VERSION ""

NS_ :

BS_:

BU_: WPC2 PSB SHVU_RR FCS vHS_B2 EMCU SLB GW_APSU GW_DLBCU RCM ARS CGW_CCU vDummy_HS_B GW_RLPSU ATS RLHV SGU PFSU GW_RRPSU ALBCU DSAU SWRC SHVU_FR RCS GW_DPSU BLTN_CAM SCM OHCL RWPC RRHV WPC HOD ASAU

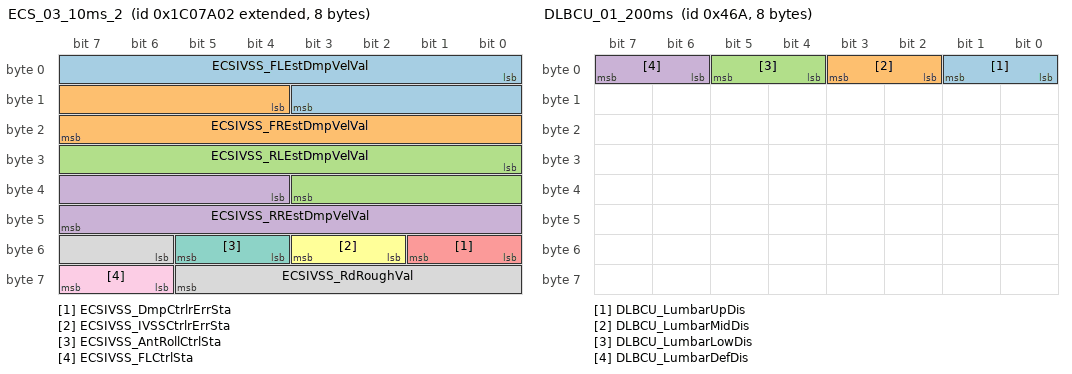
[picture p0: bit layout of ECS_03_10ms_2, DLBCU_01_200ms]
BO_ 2176875010 ECS_03_10ms_2: 8 CGW_CCU
 SG_ ECSIVSS_FLEstDmpVelVal : 0|12@1- (1,0) [0|0] "mm/s" Vector__XXX
 SG_ ECSIVSS_FREstDmpVelVal : 12|12@1- (1,0) [0|0] "mm/s" Vector__XXX
 SG_ ECSIVSS_RLEstDmpVelVal : 24|12@1- (1,0) [0|0] "mm/s" Vector__XXX
 SG_ ECSIVSS_RREstDmpVelVal : 36|12@1- (1,0) [0|0] "mm/s" Vector__XXX
 SG_ ECSIVSS_DmpCtrlrErrSta : 48|2@1+ (1,0) [0|0] "" Vector__XXX
 SG_ ECSIVSS_IVSSCtrlrErrSta : 50|2@1+ (1,0) [0|0] "" Vector__XXX
 SG_ ECSIVSS_AntRollCtrlSta : 52|2@1+ (1,0) [0|0] "" Vector__XXX
 SG_ ECSIVSS_RdRoughVal : 54|8@1+ (1,0) [0|0] ""  EMCU
 SG_ ECSIVSS_FLCtrlSta : 62|2@1+ (1,0) [0|0] "" Vector__XXX

BO_ 1130 DLBCU_01_200ms: 8 GW_DLBCU
 SG_ DLBCU_LumbarUpDis : 0|2@1+ (1,0) [0|0] ""  CGW_CCU,GW_DPSU
 SG_ DLBCU_LumbarMidDis : 2|2@1+ (1,0) [0|0] ""  CGW_CCU,GW_DPSU
 SG_ DLBCU_LumbarLowDis : 4|2@1+ (1,0) [0|0] ""  CGW_CCU,GW_DPSU
 SG_ DLBCU_LumbarDefDis : 6|2@1+ (1,0) [0|0] ""  CGW_CCU,GW_DPSU

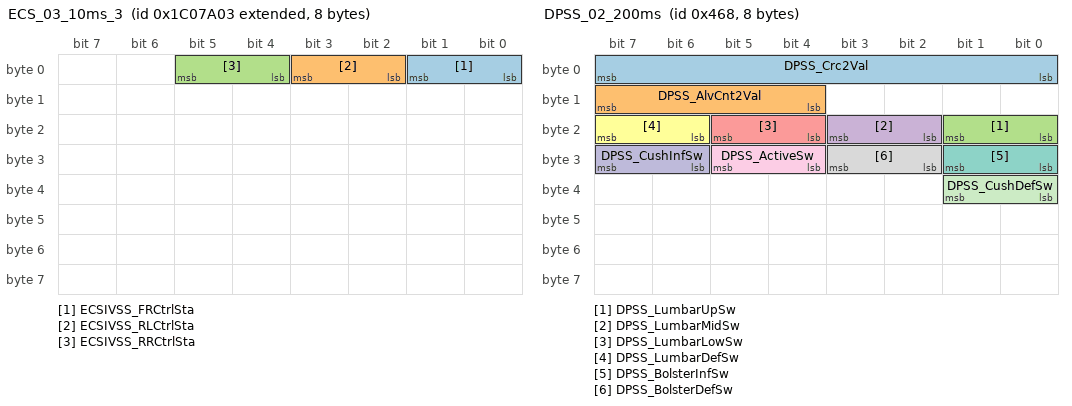
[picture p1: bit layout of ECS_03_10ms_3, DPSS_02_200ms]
BO_ 2176875011 ECS_03_10ms_3: 8 CGW_CCU
 SG_ ECSIVSS_FRCtrlSta : 0|2@1+ (1,0) [0|0] "" Vector__XXX
 SG_ ECSIVSS_RLCtrlSta : 2|2@1+ (1,0) [0|0] "" Vector__XXX
 SG_ ECSIVSS_RRCtrlSta : 4|2@1+ (1,0) [0|0] "" Vector__XXX

BO_ 1131 DLBCU_02_200ms: 8 GW_DLBCU
 SG_ DLBCU_BolsterInfDis : 0|2@1+ (1,0) [0|0] ""  CGW_CCU,GW_DPSU
 SG_ DLBCU_BolsterDefDis : 2|2@1+ (1,0) [0|0] ""  CGW_CCU,GW_DPSU

BO_ 1128 DPSS_02_200ms: 8 GW_DPSU
 SG_ DPSS_Crc2Val : 0|8@1+ (1,0) [0|0] ""  GW_DLBCU
 SG_ DPSS_AlvCnt2Val : 12|4@1+ (1,0) [0|0] ""  GW_DLBCU
 SG_ DPSS_LumbarUpSw : 16|2@1+ (1,0) [0|0] ""  CGW_CCU,GW_DLBCU
 SG_ DPSS_LumbarMidSw : 18|2@1+ (1,0) [0|0] ""  CGW_CCU,GW_DLBCU
 SG_ DPSS_LumbarLowSw : 20|2@1+ (1,0) [0|0] ""  CGW_CCU,GW_DLBCU
 SG_ DPSS_LumbarDefSw : 22|2@1+ (1,0) [0|0] ""  CGW_CCU,GW_DLBCU
 SG_ DPSS_BolsterInfSw : 24|2@1+ (1,0) [0|0] ""  GW_DLBCU
 SG_ DPSS_BolsterDefSw : 26|2@1+ (1,0) [0|0] ""  GW_DLBCU
 SG_ DPSS_ActiveSw : 28|2@1+ (1,0) [0|0] ""  GW_DLBCU
 SG_ DPSS_CushInfSw : 30|2@1+ (1,0) [0|0] ""  GW_DLBCU
 SG_ DPSS_CushDefSw : 32|2@1+ (1,0) [0|0] ""  GW_DLBCU

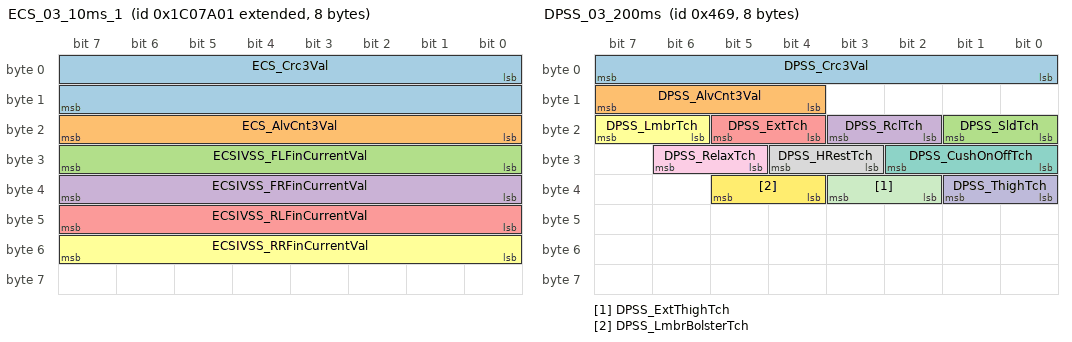
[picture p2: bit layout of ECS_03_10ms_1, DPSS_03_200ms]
BO_ 2176875009 ECS_03_10ms_1: 8 CGW_CCU
 SG_ ECS_Crc3Val : 0|16@1+ (1,0) [0|0] "" Vector__XXX
 SG_ ECS_AlvCnt3Val : 16|8@1+ (1,0) [0|0] "" Vector__XXX
 SG_ ECSIVSS_FLFinCurrentVal : 24|8@1+ (0.5,0) [0|0] "%" Vector__XXX
 SG_ ECSIVSS_FRFinCurrentVal : 32|8@1+ (0.5,0) [0|0] "%" Vector__XXX
 SG_ ECSIVSS_RLFinCurrentVal : 40|8@1+ (0.5,0) [0|0] "%" Vector__XXX
 SG_ ECSIVSS_RRFinCurrentVal : 48|8@1+ (0.5,0) [0|0] "%" Vector__XXX

BO_ 1129 DPSS_03_200ms: 8 GW_DPSU
 SG_ DPSS_Crc3Val : 0|8@1+ (1,0) [0|0] ""  CGW_CCU
 SG_ DPSS_AlvCnt3Val : 12|4@1+ (1,0) [0|0] "" Vector__XXX
 SG_ DPSS_SldTch : 16|2@1+ (1,0) [0|0] ""  CGW_CCU
 SG_ DPSS_RclTch : 18|2@1+ (1,0) [0|0] ""  CGW_CCU
 SG_ DPSS_ExtTch : 20|2@1+ (1,0) [0|0] ""  CGW_CCU
 SG_ DPSS_LmbrTch : 22|2@1+ (1,0) [0|0] ""  CGW_CCU
 SG_ DPSS_CushOnOffTch : 24|3@1+ (1,0) [0|0] ""  CGW_CCU
 SG_ DPSS_HRestTch : 27|2@1+ (1,0) [0|0] ""  CGW_CCU
 SG_ DPSS_RelaxTch : 29|2@1+ (1,0) [0|0] ""  CGW_CCU
 SG_ DPSS_ThighTch : 32|2@1+ (1,0) [0|0] ""  CGW_CCU
 SG_ DPSS_ExtThighTch : 34|2@1+ (1,0) [0|0] ""  CGW_CCU
 SG_ DPSS_LmbrBolsterTch : 36|2@1+ (1,0) [0|0] ""  CGW_CCU

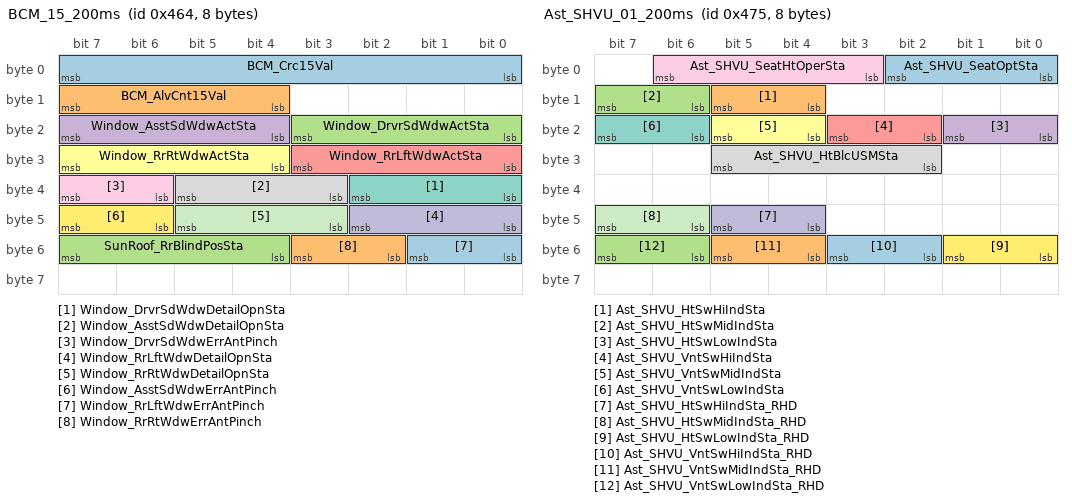
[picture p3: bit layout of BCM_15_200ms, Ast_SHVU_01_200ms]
BO_ 1124 BCM_15_200ms: 8 CGW_CCU
 SG_ BCM_Crc15Val : 0|8@1+ (1,0) [0|0] "" Vector__XXX
 SG_ BCM_AlvCnt15Val : 12|4@1+ (1,0) [0|0] "" Vector__XXX
 SG_ Window_DrvrSdWdwActSta : 16|4@1+ (1,0) [0|0] "" Vector__XXX
 SG_ Window_AsstSdWdwActSta : 20|4@1+ (1,0) [0|0] "" Vector__XXX
 SG_ Window_RrLftWdwActSta : 24|4@1+ (1,0) [0|0] "" Vector__XXX
 SG_ Window_RrRtWdwActSta : 28|4@1+ (1,0) [0|0] "" Vector__XXX
 SG_ Window_DrvrSdWdwDetailOpnSta : 32|3@1+ (1,0) [0|0] "" Vector__XXX
 SG_ Window_AsstSdWdwDetailOpnSta : 35|3@1+ (1,0) [0|0] "" Vector__XXX
 SG_ Window_DrvrSdWdwErrAntPinch : 38|2@1+ (1,0) [0|0] "" Vector__XXX
 SG_ Window_RrLftWdwDetailOpnSta : 40|3@1+ (1,0) [0|0] "" Vector__XXX
 SG_ Window_RrRtWdwDetailOpnSta : 43|3@1+ (1,0) [0|0] "" Vector__XXX
 SG_ Window_AsstSdWdwErrAntPinch : 46|2@1+ (1,0) [0|0] "" Vector__XXX
 SG_ Window_RrLftWdwErrAntPinch : 48|2@1+ (1,0) [0|0] "" Vector__XXX
 SG_ Window_RrRtWdwErrAntPinch : 50|2@1+ (1,0) [0|0] "" Vector__XXX
 SG_ SunRoof_RrBlindPosSta : 52|4@1+ (1,0) [0|0] ""  ATS

BO_ 1141 Ast_SHVU_01_200ms: 8 SHVU_FR
 SG_ Ast_SHVU_SeatOptSta : 0|3@1+ (1,0) [0|0] ""  CGW_CCU,FCS
 SG_ Ast_SHVU_HtSwHiIndSta : 12|2@1+ (1,0) [0|0] ""  CGW_CCU,FCS
 SG_ Ast_SHVU_HtSwMidIndSta : 14|2@1+ (1,0) [0|0] ""  CGW_CCU,FCS
 SG_ Ast_SHVU_HtSwLowIndSta : 16|2@1+ (1,0) [0|0] ""  CGW_CCU,FCS
 SG_ Ast_SHVU_VntSwHiIndSta : 18|2@1+ (1,0) [0|0] ""  CGW_CCU,FCS
 SG_ Ast_SHVU_VntSwMidIndSta : 20|2@1+ (1,0) [0|0] ""  CGW_CCU,FCS
 SG_ Ast_SHVU_VntSwLowIndSta : 22|2@1+ (1,0) [0|0] ""  CGW_CCU,FCS
 SG_ Ast_SHVU_HtBlcUSMSta : 26|4@1+ (1,0) [0|0] ""  CGW_CCU
 SG_ Ast_SHVU_SeatHtOperSta : 3|4@1+ (1,0) [0|0] ""  CGW_CCU,FCS
 SG_ Ast_SHVU_HtSwHiIndSta_RHD : 44|2@1+ (1,0) [0|0] ""  CGW_CCU,FCS
 SG_ Ast_SHVU_HtSwMidIndSta_RHD : 46|2@1+ (1,0) [0|0] ""  CGW_CCU,FCS
 SG_ Ast_SHVU_HtSwLowIndSta_RHD : 48|2@1+ (1,0) [0|0] ""  CGW_CCU,FCS
 SG_ Ast_SHVU_VntSwHiIndSta_RHD : 50|2@1+ (1,0) [0|0] ""  CGW_CCU,FCS
 SG_ Ast_SHVU_VntSwMidIndSta_RHD : 52|2@1+ (1,0) [0|0] ""  CGW_CCU,FCS
 SG_ Ast_SHVU_VntSwLowIndSta_RHD : 54|2@1+ (1,0) [0|0] ""  CGW_CCU,FCS

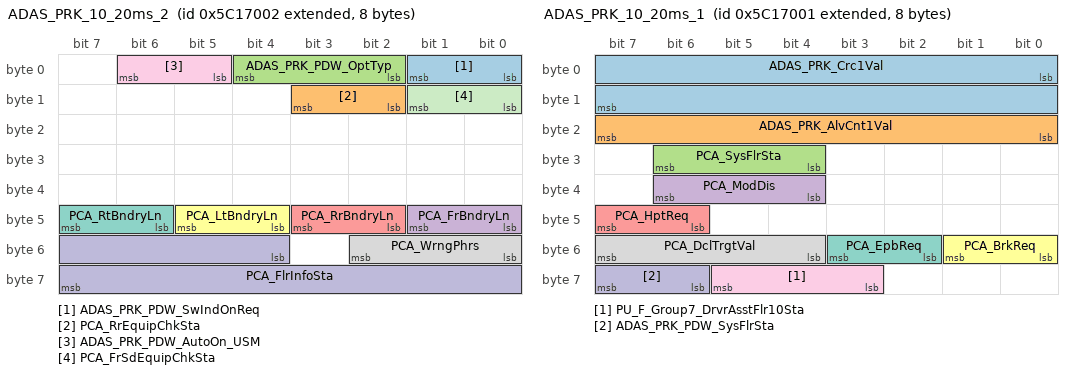
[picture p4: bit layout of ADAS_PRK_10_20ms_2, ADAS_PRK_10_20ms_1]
BO_ 2244046850 ADAS_PRK_10_20ms_2: 8 CGW_CCU
 SG_ ADAS_PRK_PDW_SwIndOnReq : 0|2@1+ (1,0) [0|0] ""  FCS
 SG_ PCA_RrEquipChkSta : 10|2@1+ (1,0) [0|0] "" Vector__XXX
 SG_ ADAS_PRK_PDW_OptTyp : 2|3@1+ (1,0) [0|0] "" Vector__XXX
 SG_ PCA_FrBndryLn : 40|2@1+ (1,0) [0|0] "" Vector__XXX
 SG_ PCA_RrBndryLn : 42|2@1+ (1,0) [0|0] "" Vector__XXX
 SG_ PCA_LtBndryLn : 44|2@1+ (1,0) [0|0] "" Vector__XXX
 SG_ PCA_RtBndryLn : 46|2@1+ (1,0) [0|0] "" Vector__XXX
 SG_ PCA_WrngPhrs : 48|3@1+ (1,0) [0|0] "" Vector__XXX
 SG_ ADAS_PRK_PDW_AutoOn_USM : 5|2@1+ (1,0) [0|0] "" Vector__XXX
 SG_ PCA_FlrInfoSta : 52|12@1+ (1,0) [0|0] "" Vector__XXX
 SG_ PCA_FrSdEquipChkSta : 8|2@1+ (1,0) [0|0] "" Vector__XXX

BO_ 2244046849 ADAS_PRK_10_20ms_1: 8 CGW_CCU
 SG_ ADAS_PRK_Crc1Val : 0|16@1+ (1,0) [0|0] "" Vector__XXX
 SG_ ADAS_PRK_AlvCnt1Val : 16|8@1+ (1,0) [0|0] "" Vector__XXX
 SG_ PCA_SysFlrSta : 28|3@1+ (1,0) [0|0] "" Vector__XXX
 SG_ PCA_ModDis : 36|3@1+ (1,0) [0|0] "" Vector__XXX
 SG_ PCA_HptReq : 46|2@1+ (1,0) [0|0] "" Vector__XXX
 SG_ PCA_BrkReq : 48|2@1+ (1,0) [0|0] "" Vector__XXX
 SG_ PCA_EpbReq : 50|2@1+ (1,0) [0|0] "" Vector__XXX
 SG_ PCA_DclTrgtVal : 52|4@1+ (0.04,0) [0|0] "g" Vector__XXX
 SG_ PU_F_Group7_DrvrAsstFlr10Sta : 59|3@1+ (1,0) [0|0] "" Vector__XXX
 SG_ ADAS_PRK_PDW_SysFlrSta : 62|2@1+ (1,0) [0|0] "" Vector__XXX

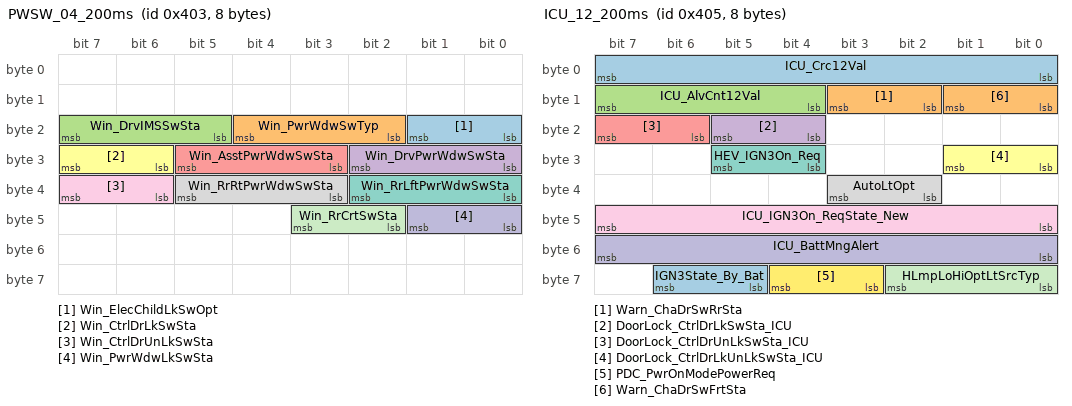
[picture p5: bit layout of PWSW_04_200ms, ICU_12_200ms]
BO_ 1027 PWSW_04_200ms: 8 CGW_CCU
 SG_ Win_ElecChildLkSwOpt : 16|2@1+ (1,0) [0|0] "" Vector__XXX
 SG_ Win_PwrWdwSwTyp : 18|3@1+ (1,0) [0|0] "" Vector__XXX
 SG_ Win_DrvIMSSwSta : 21|3@1+ (1,0) [0|0] ""  GW_DPSU
 SG_ Win_DrvPwrWdwSwSta : 24|3@1+ (1,0) [0|0] "" Vector__XXX
 SG_ Win_AsstPwrWdwSwSta : 27|3@1+ (1,0) [0|0] "" Vector__XXX
 SG_ Win_CtrlDrLkSwSta : 30|2@1+ (1,0) [0|0] "" Vector__XXX
 SG_ Win_RrLftPwrWdwSwSta : 32|3@1+ (1,0) [0|0] "" Vector__XXX
 SG_ Win_RrRtPwrWdwSwSta : 35|3@1+ (1,0) [0|0] "" Vector__XXX
 SG_ Win_CtrlDrUnLkSwSta : 38|2@1+ (1,0) [0|0] "" Vector__XXX
 SG_ Win_PwrWdwLkSwSta : 40|2@1+ (1,0) [0|0] "" Vector__XXX
 SG_ Win_RrCrtSwSta : 42|2@1+ (1,0) [0|0] "" Vector__XXX

BO_ 1029 ICU_12_200ms: 8 CGW_CCU
 SG_ ICU_Crc12Val : 0|8@1+ (1,0) [0|0] "" Vector__XXX
 SG_ Warn_ChaDrSwRrSta : 10|2@1+ (1,0) [0|0] "" Vector__XXX
 SG_ ICU_AlvCnt12Val : 12|4@1+ (1,0) [0|0] "" Vector__XXX
 SG_ DoorLock_CtrlDrLkSwSta_ICU : 20|2@1+ (1,0) [0|0] "" Vector__XXX
 SG_ DoorLock_CtrlDrUnLkSwSta_ICU : 22|2@1+ (1,0) [0|0] "" Vector__XXX
 SG_ DoorLock_CtrlDrLkUnLkSwSta_ICU : 24|2@1+ (1,0) [0|0] "" Vector__XXX
 SG_ HEV_IGN3On_Req : 28|2@1+ (1,0) [0|0] "" Vector__XXX
 SG_ AutoLtOpt : 34|2@1+ (1,0) [0|0] "" Vector__XXX
 SG_ ICU_IGN3On_ReqState_New : 40|8@1+ (1,0) [0|0] ""  GW_APSU,GW_DLBCU,GW_DPSU,GW_RLPSU,GW_RRPSU,PFSU,RLHV,RRHV,SHVU_FR,SHVU_RR
 SG_ ICU_BattMngAlert : 48|8@1+ (1,0) [0|0] "" Vector__XXX
 SG_ HLmpLoHiOptLtSrcTyp : 56|3@1+ (1,0) [0|0] "" Vector__XXX
 SG_ PDC_PwrOnModePowerReq : 59|2@1+ (1,0) [0|0] "" Vector__XXX
 SG_ IGN3State_By_Bat : 61|2@1+ (1,0) [0|0] "" Vector__XXX
 SG_ Warn_ChaDrSwFrtSta : 8|2@1+ (1,0) [0|0] "" Vector__XXX

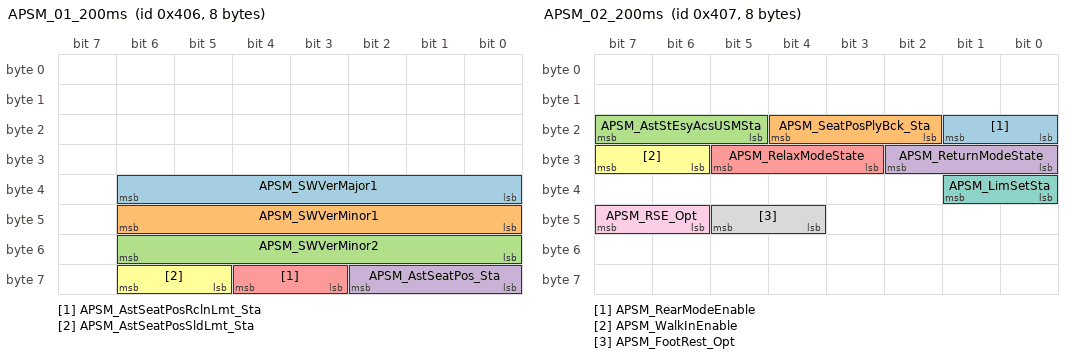
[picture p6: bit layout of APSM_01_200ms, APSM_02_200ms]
BO_ 1030 APSM_01_200ms: 8 GW_APSU
 SG_ APSM_SWVerMajor1 : 32|7@1+ (1,0) [0|0] ""  CGW_CCU
 SG_ APSM_SWVerMinor1 : 40|7@1+ (1,0) [0|0] ""  CGW_CCU
 SG_ APSM_SWVerMinor2 : 48|7@1+ (1,0) [0|0] ""  CGW_CCU
 SG_ APSM_AstSeatPos_Sta : 56|3@1+ (1,0) [0|0] ""  GW_RLPSU
 SG_ APSM_AstSeatPosRclnLmt_Sta : 59|2@1+ (1,0) [0|0] ""  CGW_CCU
 SG_ APSM_AstSeatPosSldLmt_Sta : 61|2@1+ (1,0) [0|0] ""  CGW_CCU

BO_ 1031 APSM_02_200ms: 8 GW_APSU
 SG_ APSM_RearModeEnable : 16|2@1+ (1,0) [0|0] ""  GW_RLPSU,GW_RRPSU
 SG_ APSM_SeatPosPlyBck_Sta : 18|3@1+ (1,0) [0|0] ""  GW_RLPSU
 SG_ APSM_AstStEsyAcsUSMSta : 21|3@1+ (1,0) [0|0] ""  ALBCU,CGW_CCU
 SG_ APSM_ReturnModeState : 24|3@1+ (1,0) [0|0] ""  GW_RLPSU,GW_RRPSU
 SG_ APSM_RelaxModeState : 27|3@1+ (1,0) [0|0] ""  GW_RLPSU,GW_RRPSU
 SG_ APSM_WalkInEnable : 30|2@1+ (1,0) [0|0] "" Vector__XXX
 SG_ APSM_LimSetSta : 32|2@1+ (1,0) [0|0] ""  GW_RLPSU,GW_RRPSU
 SG_ APSM_FootRest_Opt : 44|2@1+ (1,0) [0|0] "" Vector__XXX
 SG_ APSM_RSE_Opt : 46|2@1+ (1,0) [0|0] "" Vector__XXX

BO_ 1048 ICU_08_200ms: 8 CGW_CCU
 SG_ ICU_Crc8Val : 0|8@1+ (1,0) [0|0] "" Vector__XXX
 SG_ ICU_AlvCnt8Val : 12|4@1+ (1,0) [0|0] "" Vector__XXX
 SG_ DriveTypeOption : 16|2@1+ (1,0) [0|0] ""  ATS,BLTN_CAM,GW_APSU,GW_DLBCU,GW_DPSU,GW_RLPSU,GW_RRPSU,SHVU_FR,SHVU_RR
 SG_ Warn_RrLftSBRMATSwSta : 18|2@1+ (1,0) [0|0] "" Vector__XXX
 SG_ Warn_RrRhtSBRMATSwSta : 20|2@1+ (1,0) [0|0] "" Vector__XXX
 SG_ Lamp_FootLampOnReq : 30|2@1+ (1,0) [0|0] "" Vector__XXX
 SG_ Lamp_MoodLampOnReq : 32|3@1+ (1,0) [0|0] "" Vector__XXX
 SG_ ICU_PowerAutoCutModSta : 35|2@1+ (1,0) [0|0] ""  BLTN_CAM,GW_APSU,GW_DPSU,GW_RLPSU,GW_RRPSU,PFSU,RLHV,RRHV,SHVU_FR,SHVU_RR
 SG_ ICU_SoCBattStaMsgReq : 37|2@1+ (1,0) [0|0] "" Vector__XXX
 SG_ C_1stCTRSeatBeltSW : 39|1@1+ (1,0) [0|0] "" Vector__XXX
 SG_ Brake_SwSta_ICU : 46|2@1+ (1,0) [0|0] "" Vector__XXX
 SG_ C_1stCTRSBRMatSw : 48|1@1+ (1,0) [0|0] "" Vector__XXX
 SG_ C_3rdRCSeatBeltSW : 51|1@1+ (1,0) [0|0] ""  ARS,GW_RLPSU,GW_RRPSU,PFSU,WPC2
 SG_ C_3rdRRSBRMatSw : 52|1@1+ (1,0) [0|0] ""  ARS,GW_RRPSU,PFSU,WPC2
 SG_ C_3rdRLSBRMatSw : 53|1@1+ (1,0) [0|0] ""  ARS,GW_RLPSU,PFSU,WPC2
 SG_ C_3rdRRSeatBeltSW : 54|1@1+ (1,0) [0|0] ""  ARS,GW_RRPSU,PFSU,WPC2
 SG_ C_3rdRLSeatBeltSW : 55|1@1+ (1,0) [0|0] ""  ARS,GW_RLPSU,PFSU,WPC2
 SG_ HSWS_SysWrngSta_ICU : 8|2@1+ (1,0) [0|0] "" Vector__XXX

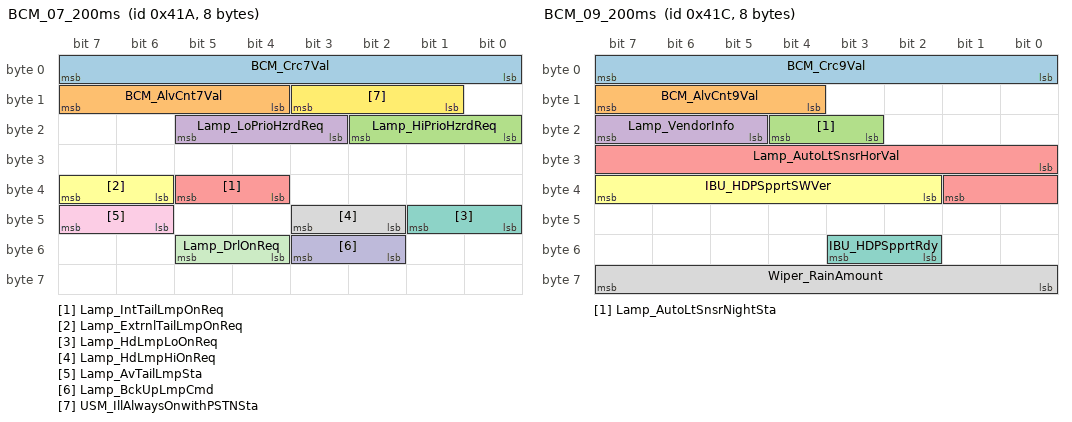
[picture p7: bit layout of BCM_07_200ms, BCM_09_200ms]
BO_ 1050 BCM_07_200ms: 8 CGW_CCU
 SG_ BCM_Crc7Val : 0|8@1+ (1,0) [0|0] "" Vector__XXX
 SG_ BCM_AlvCnt7Val : 12|4@1+ (1,0) [0|0] "" Vector__XXX
 SG_ Lamp_HiPrioHzrdReq : 16|3@1+ (1,0) [0|0] "" Vector__XXX
 SG_ Lamp_LoPrioHzrdReq : 19|3@1+ (1,0) [0|0] "" Vector__XXX
 SG_ Lamp_IntTailLmpOnReq : 36|2@1+ (1,0) [0|0] ""  FCS,GW_APSU,GW_DPSU,RLHV,RRHV,RWPC,SHVU_FR,SHVU_RR,WPC,WPC2
 SG_ Lamp_ExtrnlTailLmpOnReq : 38|2@1+ (1,0) [0|0] ""  BLTN_CAM
 SG_ Lamp_HdLmpLoOnReq : 40|2@1+ (1,0) [0|0] "" Vector__XXX
 SG_ Lamp_HdLmpHiOnReq : 42|2@1+ (1,0) [0|0] "" Vector__XXX
 SG_ Lamp_AvTailLmpSta : 46|2@1+ (1,0) [0|0] ""  ARS,ATS,GW_APSU,SWRC
 SG_ Lamp_BckUpLmpCmd : 50|2@1+ (1,0) [0|0] "" Vector__XXX
 SG_ Lamp_DrlOnReq : 52|2@1+ (1,0) [0|0] "" Vector__XXX
 SG_ USM_IllAlwaysOnwithPSTNSta : 9|3@1+ (1,0) [0|0] "" Vector__XXX

BO_ 1052 BCM_09_200ms: 8 CGW_CCU
 SG_ BCM_Crc9Val : 0|8@1+ (1,0) [0|0] "" Vector__XXX
 SG_ BCM_AlvCnt9Val : 12|4@1+ (1,0) [0|0] "" Vector__XXX
 SG_ Lamp_AutoLtSnsrNightSta : 19|2@1+ (1,0) [0|0] ""  ARS,ATS,GW_APSU,SWRC
 SG_ Lamp_VendorInfo : 21|3@1+ (1,0) [0|0] "" Vector__XXX
 SG_ Lamp_AutoLtSnsrHorVal : 24|10@1+ (1,0) [0|0] ""  ATS
 SG_ IBU_HDPSpprtSWVer : 34|6@1+ (1,0) [0|0] "" Vector__XXX
 SG_ IBU_HDPSpprtRdy : 50|2@1+ (1,0) [0|0] "" Vector__XXX
 SG_ Wiper_RainAmount : 56|8@1+ (0.1,0) [0|0] "" Vector__XXX

BO_ 1041 ICU_02_200ms: 8 CGW_CCU
 SG_ ICU_Crc2Val : 0|8@1+ (1,0) [0|0] "" Vector__XXX
 SG_ ICU_MtGearPosRSta : 10|2@1+ (1,0) [0|0] ""  BLTN_CAM
 SG_ ICU_AlvCnt2Val : 12|4@1+ (1,0) [0|0] "" Vector__XXX
 SG_ Autocut_DlvryModSta : 20|2@1+ (1,0) [0|0] "" Vector__XXX
 SG_ DoorLock_AsstDrUnLkSta : 22|2@1+ (1,0) [0|0] "" Vector__XXX
 SG_ Warn_DrvDrSwSta : 24|2@1+ (1,0) [0|0] ""  BLTN_CAM,GW_DPSU,PSB,RWPC,WPC,WPC2
 SG_ DoorLock_DrvKeyUnLkSwSta : 26|2@1+ (1,0) [0|0] "" Vector__XXX
 SG_ DoorLock_RrLftDrUnLkSta : 28|2@1+ (1,0) [0|0] "" Vector__XXX
 SG_ DoorLock_RrRtDrUnLkSta : 30|2@1+ (1,0) [0|0] "" Vector__XXX
 SG_ Warn_AsstDrSwSta : 34|2@1+ (1,0) [0|0] ""  ALBCU,BLTN_CAM,GW_APSU,GW_RLPSU,GW_RRPSU,PSB,RWPC,WPC,WPC2
 SG_ Warn_AsstStBltSwSta : 36|2@1+ (1,0) [0|0] ""  ALBCU,ASAU,GW_APSU,GW_RLPSU,PSB
 SG_ Warn_BrkFldSwSta : 38|2@1+ (1,0) [0|0] "" Vector__XXX
 SG_ DoorLock_DrvKeyLkSwSta : 40|2@1+ (1,0) [0|0] "" Vector__XXX
 SG_ Warn_DrvStBltSwSta : 42|2@1+ (1,0) [0|0] ""  ASAU,ATS,DSAU,GW_DLBCU,GW_DPSU,PSB
 SG_ Warn_HoodSwSta : 44|2@1+ (1,0) [0|0] ""  BLTN_CAM
 SG_ Warn_PassStOccSta : 46|2@1+ (1,0) [0|0] ""  GW_APSU
 SG_ Warn_PrkngBrkSwSta : 48|2@1+ (1,0) [0|0] ""  GW_APSU,GW_RLPSU,GW_RRPSU,PFSU,RLHV,RRHV
 SG_ Warn_RrCtrStBltSwSta : 50|2@1+ (1,0) [0|0] ""  GW_RLPSU,GW_RRPSU,PSB
 SG_ Warn_RrLftDrSwSta : 52|2@1+ (1,0) [0|0] ""  BLTN_CAM,GW_APSU,GW_RLPSU,GW_RRPSU,RLHV,RWPC,WPC,WPC2
 SG_ Warn_RrLftStBltSwSta : 54|2@1+ (1,0) [0|0] ""  GW_APSU,GW_DPSU,GW_RLPSU,GW_RRPSU,PSB
 SG_ Warn_RrRtDrSwSta : 56|2@1+ (1,0) [0|0] ""  BLTN_CAM,GW_APSU,GW_RLPSU,GW_RRPSU,RRHV,RWPC,WPC,WPC2
 SG_ Warn_RrRtStBltSwSta : 58|2@1+ (1,0) [0|0] ""  GW_APSU,GW_DPSU,GW_RRPSU,PSB
 SG_ Warn_HoodSwMemorySta : 60|2@1+ (1,0) [0|0] "" Vector__XXX
 SG_ Warn_WshrFldSwSta : 62|2@1+ (1,0) [0|0] "" Vector__XXX
 SG_ ICU_Haptic_OPT : 8|2@1+ (1,0) [0|0] "" Vector__XXX

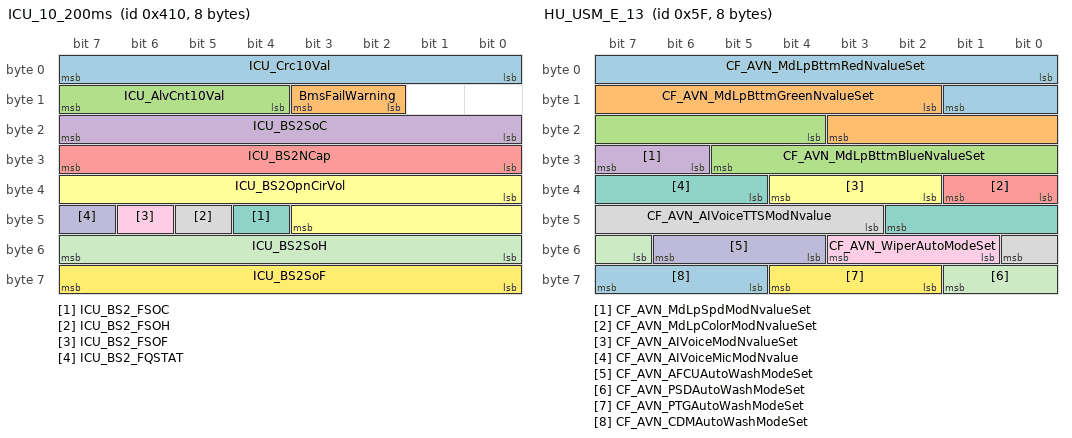
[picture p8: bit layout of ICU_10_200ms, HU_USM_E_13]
BO_ 1040 ICU_10_200ms: 8 CGW_CCU
 SG_ ICU_Crc10Val : 0|8@1+ (1,0) [0|0] "" Vector__XXX
 SG_ BmsFailWarning : 10|2@1+ (1,0) [0|0] "" Vector__XXX
 SG_ ICU_AlvCnt10Val : 12|4@1+ (1,0) [0|0] "" Vector__XXX
 SG_ ICU_BS2SoC : 16|8@1+ (1,0) [0|0] ""  BLTN_CAM
 SG_ ICU_BS2NCap : 24|8@1+ (1,0) [0|0] "" Vector__XXX
 SG_ ICU_BS2OpnCirVol : 32|12@1+ (0.001,10) [0|0] "" Vector__XXX
 SG_ ICU_BS2_FSOC : 44|1@1+ (1,0) [0|0] "" Vector__XXX
 SG_ ICU_BS2_FSOH : 45|1@1+ (1,0) [0|0] "" Vector__XXX
 SG_ ICU_BS2_FSOF : 46|1@1+ (1,0) [0|0] "" Vector__XXX
 SG_ ICU_BS2_FQSTAT : 47|1@1+ (1,0) [0|0] "" Vector__XXX
 SG_ ICU_BS2SoH : 48|8@1+ (1,0) [0|0] "" Vector__XXX
 SG_ ICU_BS2SoF : 56|8@1+ (0.05,0) [0|0] "" Vector__XXX

BO_ 95 HU_USM_E_13: 8 CGW_CCU
 SG_ CF_AVN_MdLpBttmRedNvalueSet : 0|10@1+ (1,0) [0|0] "" Vector__XXX
 SG_ CF_AVN_MdLpBttmGreenNvalueSet : 10|10@1+ (1,0) [0|0] "" Vector__XXX
 SG_ CF_AVN_MdLpBttmBlueNvalueSet : 20|10@1+ (1,0) [0|0] "" Vector__XXX
 SG_ CF_AVN_MdLpSpdModNvalueSet : 30|2@1+ (1,0) [0|0] "" Vector__XXX
 SG_ CF_AVN_MdLpColorModNvalueSet : 32|2@1+ (1,0) [0|0] "" Vector__XXX
 SG_ CF_AVN_AIVoiceModNvalueSet : 34|3@1+ (1,0) [0|0] ""  SWRC
 SG_ CF_AVN_AIVoiceMicModNvalue : 37|6@1+ (1,0) [0|0] ""  SWRC
 SG_ CF_AVN_AIVoiceTTSModNvalue : 43|6@1+ (1,0) [0|0] ""  SWRC
 SG_ CF_AVN_WiperAutoModeSet : 49|3@1+ (1,0) [0|0] "" Vector__XXX
 SG_ CF_AVN_AFCUAutoWashModeSet : 52|3@1+ (1,0) [0|0] "" Vector__XXX
 SG_ CF_AVN_PSDAutoWashModeSet : 55|3@1+ (1,0) [0|0] "" Vector__XXX
 SG_ CF_AVN_PTGAutoWashModeSet : 58|3@1+ (1,0) [0|0] "" Vector__XXX
 SG_ CF_AVN_CDMAutoWashModeSet : 61|3@1+ (1,0) [0|0] "" Vector__XXX

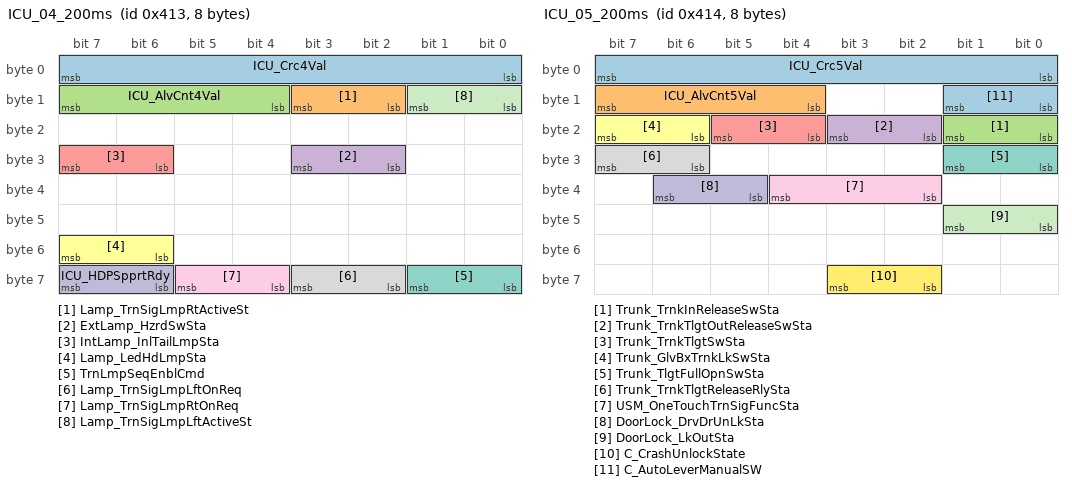
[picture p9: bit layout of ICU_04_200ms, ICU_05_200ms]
BO_ 1043 ICU_04_200ms: 8 CGW_CCU
 SG_ ICU_Crc4Val : 0|8@1+ (1,0) [0|0] "" Vector__XXX
 SG_ Lamp_TrnSigLmpRtActiveSt : 10|2@1+ (1,0) [0|0] "" Vector__XXX
 SG_ ICU_AlvCnt4Val : 12|4@1+ (1,0) [0|0] "" Vector__XXX
 SG_ ExtLamp_HzrdSwSta : 26|2@1+ (1,0) [0|0] "" Vector__XXX
 SG_ IntLamp_InlTailLmpSta : 30|2@1+ (1,0) [0|0] ""  BLTN_CAM,SWRC,WPC2
 SG_ Lamp_LedHdLmpSta : 54|2@1+ (1,0) [0|0] "" Vector__XXX
 SG_ TrnLmpSeqEnblCmd : 56|2@1+ (1,0) [0|0] "" Vector__XXX
 SG_ Lamp_TrnSigLmpLftOnReq : 58|2@1+ (1,0) [0|0] ""  BLTN_CAM
 SG_ Lamp_TrnSigLmpRtOnReq : 60|2@1+ (1,0) [0|0] ""  BLTN_CAM
 SG_ ICU_HDPSpprtRdy : 62|2@1+ (1,0) [0|0] "" Vector__XXX
 SG_ Lamp_TrnSigLmpLftActiveSt : 8|2@1+ (1,0) [0|0] "" Vector__XXX

BO_ 1044 ICU_05_200ms: 8 CGW_CCU
 SG_ ICU_Crc5Val : 0|8@1+ (1,0) [0|0] "" Vector__XXX
 SG_ ICU_AlvCnt5Val : 12|4@1+ (1,0) [0|0] "" Vector__XXX
 SG_ Trunk_TrnkInReleaseSwSta : 16|2@1+ (1,0) [0|0] "" Vector__XXX
 SG_ Trunk_TrnkTlgtOutReleaseSwSta : 18|2@1+ (1,0) [0|0] "" Vector__XXX
 SG_ Trunk_TrnkTlgtSwSta : 20|2@1+ (1,0) [0|0] ""  BLTN_CAM,GW_APSU,GW_RLPSU,GW_RRPSU,PFSU,RLHV,RRHV
 SG_ Trunk_GlvBxTrnkLkSwSta : 22|2@1+ (1,0) [0|0] "" Vector__XXX
 SG_ Trunk_TlgtFullOpnSwSta : 24|2@1+ (1,0) [0|0] "" Vector__XXX
 SG_ Trunk_TrnkTlgtReleaseRlySta : 30|2@1+ (1,0) [0|0] "" Vector__XXX
 SG_ USM_OneTouchTrnSigFuncSta : 34|3@1+ (1,0) [0|0] "" Vector__XXX
 SG_ DoorLock_DrvDrUnLkSta : 37|2@1+ (1,0) [0|0] ""  GW_DPSU
 SG_ DoorLock_LkOutSta : 40|2@1+ (1,0) [0|0] "" Vector__XXX
 SG_ C_CrashUnlockState : 58|2@1+ (1,0) [0|0] ""  BLTN_CAM
 SG_ C_AutoLeverManualSW : 8|2@1+ (1,0) [0|0] "" Vector__XXX

BO_TX_BU_ 1141 : SHVU_FR,GW_APSU;
CM_ BO_ 2176875010 "[P] Periodic";
CM_ SG_ 2176875010 ECSIVSS_FLEstDmpVelVal "ECSIVSS_FrontLeftEstimatedDamperVelocity";
CM_ SG_ 2176875010 ECSIVSS_FREstDmpVelVal "ECSIVSS_FrontRightEstimatedDamperVelocity";
CM_ SG_ 2176875010 ECSIVSS_RLEstDmpVelVal "ECSIVSS_RearLeftEstimatedDamperVelocity";
CM_ SG_ 2176875010 ECSIVSS_RREstDmpVelVal "ECSIVSS_RearRightEstimatedDamperVelocity";
CM_ SG_ 2176875010 ECSIVSS_DmpCtrlrErrSta "ECSIVSS_DamperControllerErrorStatus";
CM_ SG_ 2176875010 ECSIVSS_IVSSCtrlrErrSta "ECSIVSS_IVSSControllerErrorStatus";
CM_ SG_ 2176875010 ECSIVSS_AntRollCtrlSta "ECSIVSS_Anti-rollcontrolStatus";
CM_ SG_ 2176875010 ECSIVSS_RdRoughVal "ECSIVSS_RoadRoughnessValue";
CM_ SG_ 2176875010 ECSIVSS_FLCtrlSta "ECS Control Status - Front Left";
CM_ BO_ 1130 "[PE] Periodic and On Event";
CM_ SG_ 1130 DLBCU_LumbarUpDis "DLBCU_LumbarUppperDisplay";
CM_ SG_ 1130 DLBCU_LumbarMidDis "DLBCU_LumbarMidDisplay";
CM_ SG_ 1130 DLBCU_LumbarLowDis "DLBCU_LumbarLowerDisplay";
CM_ SG_ 1130 DLBCU_LumbarDefDis "DLBCU_LumbarDeflationDisplay";
CM_ BO_ 2176875011 "[P] Periodic";
CM_ SG_ 2176875011 ECSIVSS_FRCtrlSta "ECS Control Status - Front Right";
CM_ SG_ 2176875011 ECSIVSS_RLCtrlSta "ECS Control Status - Rear Left";
CM_ SG_ 2176875011 ECSIVSS_RRCtrlSta "ECS Control Status - Rear Right";
CM_ BO_ 1131 "[PE] Periodic and On Event";
CM_ SG_ 1131 DLBCU_BolsterInfDis "DLBCU_BolsterInflationDisplay";
CM_ SG_ 1131 DLBCU_BolsterDefDis "DLBCU_BolsterDeflationDisplay";
CM_ BO_ 1128 "[PE] Periodic and On Event";
CM_ SG_ 1128 DPSS_Crc2Val "DPSS_CyclicRedundancyCheck2Value";
CM_ SG_ 1128 DPSS_AlvCnt2Val "DPSS_AliveCounter2Value";
CM_ SG_ 1128 DPSS_LumbarUpSw "DPSS_LumbarUpMoveSwitch";
CM_ SG_ 1128 DPSS_LumbarMidSw "DPSS_LumbarMiddleSwitch";
CM_ SG_ 1128 DPSS_LumbarLowSw "DPSS_LumbarLowerSwitch";
CM_ SG_ 1128 DPSS_LumbarDefSw "DPSS_LumbarDeflationSwitch";
CM_ SG_ 1128 DPSS_BolsterInfSw "DPSS_BolsterInflationSwitch";
CM_ SG_ 1128 DPSS_BolsterDefSw "DPSS_BolsterDeflationSwitch";
CM_ SG_ 1128 DPSS_ActiveSw "DPSS_ActiveSwitch";
CM_ SG_ 1128 DPSS_CushInfSw "DPSS_Cush Support Inflation Switch";
CM_ SG_ 1128 DPSS_CushDefSw "DPSS_Cush Support Deflation Switch";
CM_ BO_ 2176875009 "[P] Periodic";
CM_ SG_ 2176875009 ECS_Crc3Val "ECS_CyclicRedundancyCheck3Value";
CM_ SG_ 2176875009 ECS_AlvCnt3Val "ECS_AliveCounter3Value";
CM_ SG_ 2176875009 ECSIVSS_FLFinCurrentVal "ECSIVSS_FrontLeftFinalCurrentValue";
CM_ SG_ 2176875009 ECSIVSS_FRFinCurrentVal "ECSIVSS_FrontRightFinalCurrentValue";
CM_ SG_ 2176875009 ECSIVSS_RLFinCurrentVal "ECSIVSS_RearLeftFinalCurrentValue";
CM_ SG_ 2176875009 ECSIVSS_RRFinCurrentVal "ECSIVSS_RearRightFinalCurrentValue";
CM_ BO_ 1129 "[PE] Periodic and On Event";
CM_ SG_ 1129 DPSS_Crc3Val "DPSS_CyclicRedundancyCheck3Value";
CM_ SG_ 1129 DPSS_AlvCnt3Val "DPSS_AliveCounter3Value";
CM_ SG_ 1129 DPSS_SldTch "DPSS_SlideTouch";
CM_ SG_ 1129 DPSS_RclTch "DPSS_ReclinerTouch";
CM_ SG_ 1129 DPSS_ExtTch "DPSS_ExtensionTouch";
CM_ SG_ 1129 DPSS_LmbrTch "DPSS_LumbarTouch";
CM_ SG_ 1129 DPSS_CushOnOffTch "DPSS_CushOnOffTouch";
CM_ SG_ 1129 DPSS_HRestTch "DPSS_HeadResetTouch";
CM_ SG_ 1129 DPSS_RelaxTch "DPSS_RelaxTouch";
CM_ SG_ 1129 DPSS_ThighTch "DPSS_ThighTouch";
CM_ SG_ 1129 DPSS_ExtThighTch "DPSS_ExtensionThighTouch";
CM_ SG_ 1129 DPSS_LmbrBolsterTch "DPSS_LumbarBolsterTouch";
CM_ BO_ 1124 "[PE] Periodic and On Event";
CM_ SG_ 1124 BCM_Crc15Val "BCM_CyclicRedundancyCheck15Value";
CM_ SG_ 1124 BCM_AlvCnt15Val "BCM_AliveCounter15Value";
CM_ SG_ 1124 Window_DrvrSdWdwActSta "Window_DriverSideWindowActionStatus ##2G##BCM - BCMmsg25 - C_DrvWindowActState";
CM_ SG_ 1124 Window_AsstSdWdwActSta "Window_AssistantSideWindowActionStatus ##2G##BCM - BCMmsg25 - C_AstWindowActState";
CM_ SG_ 1124 Window_RrLftWdwActSta "Window_RearLeftWindowActionStatus ##2G##BCM - BCMmsg25 - C_RLWindowActState";
CM_ SG_ 1124 Window_RrRtWdwActSta "Window_RearRightWindowActionStatus ##2G##BCM - BCMmsg25 - C_RRWindowActState";
CM_ SG_ 1124 Window_DrvrSdWdwDetailOpnSta "Window_DriverSideWindowDetailOpenStatus ##2G##BCM - BCMmsg26 - C_DrvWdwDetailOpenState";
CM_ SG_ 1124 Window_AsstSdWdwDetailOpnSta "Window_AssistantSideWindowDetailOpenStatus ##2G##BCM - BCMmsg26 - C_AstWdwDetailOpenState";
CM_ SG_ 1124 Window_DrvrSdWdwErrAntPinch "Window_DriverSideWindowErrorAntiPinch ##2G##BCM - BCMmsg26 - C_DrvWdwErrAntiPinch";
CM_ SG_ 1124 Window_RrLftWdwDetailOpnSta "Window_RearLeftWindowDetailOpenStatus ##2G##BCM - BCMmsg26 - C_RLWdwDetailOpenState";
CM_ SG_ 1124 Window_RrRtWdwDetailOpnSta "Window_RearRightWindowDetailOpenStatus ##2G##BCM - BCMmsg26 - C_RRWdwDetailOpenState";
CM_ SG_ 1124 Window_AsstSdWdwErrAntPinch "Window_AssistantSideWindowErrorAntiPinch ##2G##BCM - BCMmsg26 - C_AstWdwErrAntiPinch";
CM_ SG_ 1124 Window_RrLftWdwErrAntPinch "Window_RearLeftWindowErrorAntiPinch ##2G##BCM - BCMmsg26 - C_RLWdwErrAntiPinch";
CM_ SG_ 1124 Window_RrRtWdwErrAntPinch "Window_RearRightWindowErrorAntiPinch ##2G##BCM - BCMmsg26 - C_RRWdwErrAntiPinch";
CM_ SG_ 1124 SunRoof_RrBlindPosSta "SunRoof_RearBlindPositionStatus";
CM_ BO_ 1141 "[PE] Periodic and On Event";
CM_ SG_ 1141 Ast_SHVU_SeatOptSta "Ast Seat Heater/Vent option info";
CM_ SG_ 1141 Ast_SHVU_HtSwHiIndSta "Ast Seat Heater Switch High Indicator Status";
CM_ SG_ 1141 Ast_SHVU_HtSwMidIndSta "Ast Seat Heater Switch Mid Indicator Status";
CM_ SG_ 1141 Ast_SHVU_HtSwLowIndSta "Ast Seat Heater Switch Low Indicator Status";
CM_ SG_ 1141 Ast_SHVU_VntSwHiIndSta "Ast Seat Vent Switch High Indicator Status";
CM_ SG_ 1141 Ast_SHVU_VntSwMidIndSta "Ast Seat Vent Switch Mid Indicator Status";
CM_ SG_ 1141 Ast_SHVU_VntSwLowIndSta "Ast Seat Vent Switch Low Indicator Status";
CM_ SG_ 1141 Ast_SHVU_HtBlcUSMSta "Hetaer Balance Assistant USM R vaule";
CM_ SG_ 1141 Ast_SHVU_SeatHtOperSta "Ast Seat Heater/Vent current operation state";
CM_ SG_ 1141 Ast_SHVU_HtSwHiIndSta_RHD "Ast Seat Heater Switch High Indicator Status(RHD)";
CM_ SG_ 1141 Ast_SHVU_HtSwMidIndSta_RHD "Ast Seat Heater Switch Mid Indicator Status(RHD)";
CM_ SG_ 1141 Ast_SHVU_HtSwLowIndSta_RHD "Ast Seat Heater Switch Low Indicator Status(RHD)";
CM_ SG_ 1141 Ast_SHVU_VntSwHiIndSta_RHD "Ast Seat Vent Switch High Indicator Status(RHD)";
CM_ SG_ 1141 Ast_SHVU_VntSwMidIndSta_RHD "Ast Seat Vent Switch Mid Indicator Status(RHD)";
CM_ SG_ 1141 Ast_SHVU_VntSwLowIndSta_RHD "Ast Seat Vent Switch Low Indicator Status(RHD)";
CM_ BO_ 2244046850 "[P] Periodic";
CM_ SG_ 2244046850 PCA_RrEquipChkSta "PCA RearEquipmentCheckStatus";
CM_ SG_ 2244046850 ADAS_PRK_PDW_OptTyp "Option information for None, PDW-R, PDW-FR, PDW-FSR";
CM_ SG_ 2244046850 PCA_FrBndryLn "PCA - Front Boundary Line Display Status";
CM_ SG_ 2244046850 PCA_RrBndryLn "PCA - Rear Boundary Line Display Status";
CM_ SG_ 2244046850 PCA_LtBndryLn "PCA - Left Boundary Line Display Status";
CM_ SG_ 2244046850 PCA_RtBndryLn "PCA - Right Boundary Line Display Status";
CM_ SG_ 2244046850 PCA_WrngPhrs "PCA - Warning Phrase Display Status";
CM_ SG_ 2244046850 PCA_FlrInfoSta "PCA Failure Information State";
CM_ SG_ 2244046850 PCA_FrSdEquipChkSta "PCA_FrontSideEquipmentCheckStatus";
CM_ BO_ 2244046849 "[P] Periodic";
CM_ SG_ 2244046849 ADAS_PRK_Crc1Val "ADAS_PRK_CyclicRedundancyCheck1Value";
CM_ SG_ 2244046849 ADAS_PRK_AlvCnt1Val "ADAS_PRK_AliveCounter1Value";
CM_ SG_ 2244046849 PCA_SysFlrSta "PCA_SystemFailureStatus";
CM_ SG_ 2244046849 PCA_ModDis "PCA_ ModeDisplay";
CM_ SG_ 2244046849 PCA_HptReq "PCA_HapticRequest";
CM_ SG_ 2244046849 PCA_BrkReq "PCA_BrakeRequest";
CM_ SG_ 2244046849 PCA_EpbReq "PCA_EPBRequest";
CM_ SG_ 2244046849 PCA_DclTrgtVal "PCA_DecelerationTargetValue";
CM_ SG_ 2244046849 PU_F_Group7_DrvrAsstFlr10Sta "PDW or PCA Blockage / Failure Status";
CM_ SG_ 2244046849 ADAS_PRK_PDW_SysFlrSta "PDW System Failure State";
CM_ BO_ 1027 "[PE] Periodic and On Event";
CM_ SG_ 1027 Win_ElecChildLkSwOpt "Window_ElectricChildLockSwitchOption";
CM_ SG_ 1027 Win_PwrWdwSwTyp "Window_PowerWindowSwitchType";
CM_ SG_ 1027 Win_DrvIMSSwSta "Window_DriverIMSSwitchStatus";
CM_ SG_ 1027 Win_DrvPwrWdwSwSta "Window_DriverPowerWindowSwitchStatus";
CM_ SG_ 1027 Win_AsstPwrWdwSwSta "Window_AssistantPowerWindowSwitchStatus";
CM_ SG_ 1027 Win_CtrlDrLkSwSta "Window_CentralDoorLockSwitchStatus";
CM_ SG_ 1027 Win_RrLftPwrWdwSwSta "Window_RearLeftPowerWindowSwitchStatus";
CM_ SG_ 1027 Win_RrRtPwrWdwSwSta "Window_RearRightPowerWindowSwitchStatus";
CM_ SG_ 1027 Win_CtrlDrUnLkSwSta "Window_CentralDoorUnlockSwitchStatus";
CM_ SG_ 1027 Win_PwrWdwLkSwSta "Window_PowerWindowLockSwitchStatus";
CM_ SG_ 1027 Win_RrCrtSwSta "Window_RearCurtainSwitchStatus";
CM_ BO_ 1029 "[PE] Periodic and On Event";
CM_ SG_ 1029 ICU_Crc12Val "ICU_CyclicRedundancyCheck12Value";
CM_ SG_ 1029 Warn_ChaDrSwRrSta "##2G## -  - CF_Gway_ChaDrSwRr";
CM_ SG_ 1029 ICU_AlvCnt12Val "ICU_AliveCounter12Value";
CM_ SG_ 1029 DoorLock_CtrlDrLkSwSta_ICU "Central Door Lock Switch State(DRV or AST or RL or RR Door trim)";
CM_ SG_ 1029 DoorLock_CtrlDrUnLkSwSta_ICU "Central Door Unlock Switch State(DRV or AST or RL or RR Door trim)";
CM_ SG_ 1029 DoorLock_CtrlDrLkUnLkSwSta_ICU "Central Door Lock/Unlock Switch State(C/PAD, Integrated & self return type)";
CM_ SG_ 1029 HEV_IGN3On_Req "HEV IGN3 Relay Control Request State";
CM_ SG_ 1029 AutoLtOpt "Auto Light »ç¾ç Àû¿ë ¿©ºÎ ¹× Àû¿ë ¿É¼Ç Á¤º¸ Ãâ·Â (¹ÌÀû¿ë/Àû¿ë)";
CM_ SG_ 1029 ICU_IGN3On_ReqState_New "EV IGN3 Relay Request unit State";
CM_ SG_ 1029 ICU_BattMngAlert "This signal is for battery discharge warning.";
CM_ SG_ 1029 HLmpLoHiOptLtSrcTyp "Head Low&High Lamp »ç¾ç Àû¿ë ¿©ºÎ ¹× Light Source Type, ¿É¼Ç Á¤º¸ Ãâ·Â";
CM_ SG_ 1029 PDC_PwrOnModePowerReq "This is for high voltage battery discharge request at Power On mode of EV";
CM_ SG_ 1029 IGN3State_By_Bat "Output status of ignition 3 by IBS or BMS request for HEV 12V auxiliary battery charging";
CM_ SG_ 1029 Warn_ChaDrSwFrtSta "##2G## - -  CF_Gway_ChaDrSwFrt";
CM_ BO_ 1030 "[PE] Periodic and On Event";
CM_ SG_ 1030 APSM_SWVerMajor1 "First Word(ASCII) in APSM S/W Ver";
CM_ SG_ 1030 APSM_SWVerMinor1 "Second Word(ASCII) in APSM S/W Ver";
CM_ SG_ 1030 APSM_SWVerMinor2 "Third Word(ASCII) in APSM S/W Ver";
CM_ SG_ 1030 APSM_AstSeatPos_Sta "APSM_SeatPosition_State";
CM_ SG_ 1030 APSM_AstSeatPosRclnLmt_Sta "APSM_SeatPositionReclineLimit_State";
CM_ SG_ 1030 APSM_AstSeatPosSldLmt_Sta "APSM_SeatPositionSlideLimitState";
CM_ BO_ 1031 "[PE] Periodic and On Event";
CM_ SG_ 1031 APSM_SeatPosPlyBck_Sta "APSM_SeatPositionPlayBack_State";
CM_ SG_ 1031 APSM_AstStEsyAcsUSMSta "USM_MovingValue";
CM_ SG_ 1031 APSM_LimSetSta "APSM limit setting state";
CM_ SG_ 1031 APSM_FootRest_Opt "Foot Rest OPTION";
CM_ SG_ 1031 APSM_RSE_Opt "RSE OPTION";
CM_ BO_ 1048 "[PE] Periodic and On Event";
CM_ SG_ 1048 ICU_Crc8Val "ICU_CyclicRedundancyCheck8Value";
CM_ SG_ 1048 ICU_AlvCnt8Val "ICU_AliveCounter8Value";
CM_ SG_ 1048 DriveTypeOption "##2G## -  - C_DriveTypeOption,CF_Gway_DriveTypeOption";
CM_ SG_ 1048 Warn_RrLftSBRMATSwSta "##2G## -  - C_RLSBRMatSw";
CM_ SG_ 1048 Warn_RrRhtSBRMATSwSta "##2G## -  - C_RRSBRMatSw";
CM_ SG_ 1048 Lamp_FootLampOnReq "##2G## -  - C_FootLpOn";
CM_ SG_ 1048 Lamp_MoodLampOnReq "##2G## -  - C_MoodLpOn";
CM_ SG_ 1048 ICU_PowerAutoCutModSta "##2G## -  - CF_Gway_ICUPowerAutoCutMode";
CM_ SG_ 1048 ICU_SoCBattStaMsgReq "##2G## -  - Batt_SoCWarningAlertMsgReq";
CM_ SG_ 1048 Brake_SwSta_ICU "Brake Switch Status ##2G## -  - C_BrakeSw";
CM_ SG_ 1048 C_3rdRRSeatBeltSW "3rd Rear Right Seat Belt Switch Status";
CM_ SG_ 1048 C_3rdRLSeatBeltSW "3rd Rear Left Seat Belt Switch Status";
CM_ SG_ 1048 HSWS_SysWrngSta_ICU "HSWS Status ##2G## -  - C_HSWSSysStat";
CM_ BO_ 1050 "[PE] Periodic and On Event";
CM_ SG_ 1050 BCM_Crc7Val "BCM_CyclicRedundancyCheck7Value";
CM_ SG_ 1050 BCM_AlvCnt7Val "BCM_AliveCounter7Value";
CM_ SG_ 1050 Lamp_HiPrioHzrdReq "Lamp_HighPriorityHazardRequest ##2G##BCM - BCMmsg19 - C_HazardFromBCMHigh";
CM_ SG_ 1050 Lamp_LoPrioHzrdReq "Lamp_LowPriorityHazardStatus ##2G##BCM - BCMmsg19 - C_HazardfromBCMLow";
CM_ SG_ 1050 Lamp_IntTailLmpOnReq "Lamp_InternalTailLampOnRequest ##2G##BCM - BCMmsg19 - C_IntTailOn";
CM_ SG_ 1050 Lamp_ExtrnlTailLmpOnReq "Lamp_ExternalTailLampOnRequest ##2G##BCM - BCMmsg19 - C_ExtTailOn";
CM_ SG_ 1050 Lamp_HdLmpLoOnReq "Lamp_HeadLampLowOnRequest ##2G##BCM - BCMmsg19 - C_HLpLowOn";
CM_ SG_ 1050 Lamp_HdLmpHiOnReq "Lamp_HeadLampHighOnRequest ##2G##BCM - BCMmsg19 - C_HLpHighOn";
CM_ SG_ 1050 Lamp_AvTailLmpSta "Lamp_AvTailLampStatus ##2G##BCM - BCMmsg18 - C_AvTail";
CM_ BO_ 1052 "[PE] Periodic and On Event";
CM_ SG_ 1052 BCM_Crc9Val "BCM_CyclicRedundancyCheck9Value";
CM_ SG_ 1052 BCM_AlvCnt9Val "BCM_AliveCounter9Value";
CM_ SG_ 1052 Lamp_AutoLtSnsrNightSta "Lamp_AutoLightSensorNightStatus ##2G##BCM - BCMmsg24 - C_AutolightValue";
CM_ SG_ 1052 Lamp_AutoLtSnsrHorVal "Lamp_AutoLightSensorHorValue ##2G##BCM - BCMmsg24 - C_AutolightSensorHorState";
CM_ BO_ 1041 "[PE] Periodic and On Event";
CM_ SG_ 1041 ICU_Crc2Val "ICU_CyclicRedundancyCheck2Value";
CM_ SG_ 1041 ICU_MtGearPosRSta "##2G## -  - C_InhibitRMT,CF_Gway_InhibitRMT";
CM_ SG_ 1041 ICU_AlvCnt2Val "ICU_AliveCounter2Value";
CM_ SG_ 1041 Autocut_DlvryModSta "Autocut_DeliveryModeStatus ##2G## -  - C_SJBDeliveryMode,CF_Gway_SJBDeliveryMode";
CM_ SG_ 1041 DoorLock_AsstDrUnLkSta "DoorLock_AssistDoorUnLockStatus ##2G## -  - C_AstUnlockState,DoorLock_AsstDrUnLkSta";
CM_ SG_ 1041 Warn_DrvDrSwSta "DoorLock_DriverDoorSwitchStatus ##2G## -  - C_DrvDrSw,CF_Gway_DrvDrSw,Warn_DrvDrSwSta";
CM_ SG_ 1041 DoorLock_DrvKeyUnLkSwSta "DoorLock_DriverKeyUnLockSwitchStatus ##2G## -  - C_DrvKeyUnlockSw";
CM_ SG_ 1041 DoorLock_RrLftDrUnLkSta "DoorLock_RearLeftDoorUnLockStatus ##2G## -  - C_RLUnlockState,DoorLock_RrLftDrUnLkSta";
CM_ SG_ 1041 DoorLock_RrRtDrUnLkSta "DoorLock_RearRightDoorUnLockStatus ##2G## -  - C_RRUnlockState,DoorLock_RrRtDrUnLkSta";
CM_ SG_ 1041 Warn_AsstDrSwSta "Warn_AssistDoorSwitchStatus ##2G## -  - C_AstDrSw,CF_Gway_AstDrSw,Warn_AsstDrSwSta";
CM_ SG_ 1041 Warn_AsstStBltSwSta "Warn_AssistSeatBeltSwitchStatus ##2G## -  - C_AstSeatBeltSw,CF_Gway_AstSeatBeltSw";
CM_ SG_ 1041 Warn_BrkFldSwSta "Warn_BrakeFluidSwitchStatus ##2G## -  - C_BrakeFluidSw,CF_Gway_BrakeFluidSw";
CM_ SG_ 1041 DoorLock_DrvKeyLkSwSta "DoorLock_DriverKeyLockSwitchStatus ##2G## -  - C_DrvKeyLockSw";
CM_ SG_ 1041 Warn_DrvStBltSwSta "Warn_DriverSeatbeltSwitchStatus ##2G## -  - C_DrvSeatBeltSw,CF_Gway_DrvSeatBeltSw";
CM_ SG_ 1041 Warn_HoodSwSta "Warn_HoodSwitchStatus ##2G## -  - C_HoodSw,CF_Gway_HoodSw";
CM_ SG_ 1041 Warn_PassStOccSta "Warn_PassengerSeatOccupyStatus ##2G## -  - C_SBRMatSw";
CM_ SG_ 1041 Warn_PrkngBrkSwSta "Warn_ParkingBrakeSwitchStatus ##2G## -  - C_ParkBrakeSw";
CM_ SG_ 1041 Warn_RrCtrStBltSwSta "Warn_RearCenterSeatBeltSwitchStatus ##2G## -  - C_RCSeatBeltSw";
CM_ SG_ 1041 Warn_RrLftDrSwSta "Warn_RearLeftDoorSwitchStatus ##2G## -  - C_RLDrSw,CF_Gway_RLDrSw,Warn_RrLftDrSwSta";
CM_ SG_ 1041 Warn_RrLftStBltSwSta "Warn_RearLeftSeatBeltSwitchStatus ##2G## -  - C_RLSeatBeltSw";
CM_ SG_ 1041 Warn_RrRtDrSwSta "Warn_RearRightDoorSwitchStatus ##2G## -  - C_RRDrSw,CF_Gway_RRDrSw,Warn_RrRtDrSwSta";
CM_ SG_ 1041 Warn_RrRtStBltSwSta "Warn_RearRightSeatBeltSwitchStatus ##2G## -  - C_RRSeatBeltSw";
CM_ SG_ 1041 Warn_HoodSwMemorySta "Warn_HoodSwitchMemoryStatus ##2G## -  - CF_Hoodsw_memory,C_HoodSwMemory";
CM_ SG_ 1041 Warn_WshrFldSwSta "Washer Fluid Switch Signal ##2G## -  - CF_Gway_WasherFluidSw";
CM_ SG_ 1041 ICU_Haptic_OPT "Steering Wheel Haptic Warning Option Infomation ##2G## -  - C_ICU_Haptic_OPT";
CM_ BO_ 1040 "[PE] Periodic and On Event";
CM_ SG_ 1040 ICU_Crc10Val "ICU_CyclicRedundancyCheck10Value";
CM_ SG_ 1040 ICU_AlvCnt10Val "ICU_AliveCounter10Value";
CM_ SG_ 1040 ICU_BS2SoC "This signal is battery State of Charge as calculated by battery sensor. ##2G## -  - BS2_SOC,Batt_SoC";
CM_ SG_ 1040 ICU_BS2NCap "Nominal capacity ##2G## -  - BS2_CNOM";
CM_ SG_ 1040 ICU_BS2OpnCirVol "Last open circuit voltage ##2G## -  - BS2_OCV";
CM_ SG_ 1040 ICU_BS2_FSOC "Fault State of SOC";
CM_ SG_ 1040 ICU_BS2_FSOH "Fault State of SOH";
CM_ SG_ 1040 ICU_BS2_FSOF "Fault State of SOF";
CM_ SG_ 1040 ICU_BS2_FQSTAT "State of quiescent current";
CM_ SG_ 1040 ICU_BS2SoH "This signal is battery State of Health(SOH) as calculated by battery sensor. ##2G## -  - BAT_SOH";
CM_ SG_ 1040 ICU_BS2SoF "This signal is battery State of Function(SOF) as calculated by battery sensor. ##2G## -  - BAT_SOF";
CM_ BO_ 95 "[EC] On Event and On Change";
CM_ SG_ 95 CF_AVN_AIVoiceModNvalueSet "Signal of mood lamp concern about AI voice";
CM_ SG_ 95 CF_AVN_AIVoiceMicModNvalue "Signal of AI voice size HU to MLM";
CM_ SG_ 95 CF_AVN_AIVoiceTTSModNvalue "Signal TTS Mode HU to MLM";
CM_ BO_ 1043 "[PE] Periodic and On Event";
CM_ SG_ 1043 ICU_Crc4Val "ICU_CyclicRedundancyCheck4Value";
CM_ SG_ 1043 Lamp_TrnSigLmpRtActiveSt "Lamp_TurnSignalLampRightActiveState";
CM_ SG_ 1043 ICU_AlvCnt4Val "ICU_AliveCounter4Value";
CM_ SG_ 1043 ExtLamp_HzrdSwSta "ExtLamp_HazardSwitchStatus ##2G## -  - C_HazardSw,CF_Gway_HazardSw";
CM_ SG_ 1043 IntLamp_InlTailLmpSta "IntLamp_InternalTailLampStatus ##2G## -  - C_IntTailAct,CF_Gway_IntTailAct";
CM_ SG_ 1043 Lamp_LedHdLmpSta "Lamp_LedHeadLampStatus ##2G## -  - CF_Afs_LedHLStat";
CM_ SG_ 1043 Lamp_TrnSigLmpLftOnReq "Lamp_TurnSignalLampLeftOnRequest ##2G## -  - Lamp_TsigLmpFrtLftOnReq";
CM_ SG_ 1043 Lamp_TrnSigLmpRtOnReq "Lamp_TurnSignalLampRightOnRequest ##2G## -  - Lamp_TSigLmpRtLftOnReq";
CM_ SG_ 1043 ICU_HDPSpprtRdy "This signal is the received state information signal of the ADAS message.";
CM_ SG_ 1043 Lamp_TrnSigLmpLftActiveSt "Lamp_TurnSignalLampLeftActiveState";
CM_ BO_ 1044 "[PE] Periodic and On Event";
CM_ SG_ 1044 ICU_Crc5Val "ICU_CyclicRedundancyCheck5Value";
CM_ SG_ 1044 ICU_AlvCnt5Val "ICU_AliveCounter5Value";
CM_ SG_ 1044 Trunk_TrnkInReleaseSwSta "Trunk_TrunkInnerReleaseSwitchStatus ##2G## -  - C_TrunkInnerReleaseSw";
CM_ SG_ 1044 Trunk_TrnkTlgtOutReleaseSwSta "Trunk_TrunkTailgateOutReleaseSwitchStatus ##2G## -  - C_TrunkTgOtrReleaseSW";
CM_ SG_ 1044 Trunk_TrnkTlgtSwSta "Trunk_TrunkTailgateSwitchStatus ##2G## -  - C_TrunkTgSw,CF_Gway_TrunkTgSw,Trunk_TrnkTlgtSwSta";
CM_ SG_ 1044 Trunk_GlvBxTrnkLkSwSta "Trunk_GloveBoxTrunkLockSwitchStatus ##2G## -  - C_GloveBoxTrunkLockSw";
CM_ SG_ 1044 Trunk_TlgtFullOpnSwSta "Trunk_TailGateFullOpenSwitchStatus ##2G## -  - C_TgFullOpenSW";
CM_ SG_ 1044 Trunk_TrnkTlgtReleaseRlySta "Trunk_TrunkTailgateReleaseRelayStatus ##2G## -  - C_TrunkTgReleaseRlyAct";
CM_ SG_ 1044 USM_OneTouchTrnSigFuncSta "USM_OneTouchTurnSignalFunctionStatus ##2G## -  - CF_Gway_OTTurnRValue,C_OTTurnRValue";
CM_ SG_ 1044 DoorLock_DrvDrUnLkSta "DoorLock_DriverDoorUnLockStatus ##2G## -  - C_DrvUnlockState,CF_Gway_DrvUnlockState";
CM_ SG_ 1044 DoorLock_LkOutSta "DoorLock_LockOutputStatus ##2G## -  - C_LockUnlockOutState";
CM_ SG_ 1044 C_CrashUnlockState "Crash Unlock Active State";
CM_ SG_ 1044 C_AutoLeverManualSW "Auto Lever Manual Switch Status Information";
BA_DEF_ BO_  "DiagState" ENUM  "No","Yes";
BA_DEF_ BO_  "DiagResponse" ENUM  "No","Yes";
BA_DEF_ BO_  "DiagRequest" ENUM  "No","Yes";
BA_DEF_ BO_  "TpMessage" ENUM  "No","Yes";
BA_DEF_ BO_  "UsrMsgIDSforwardDeviation" INT 0 100;
BA_DEF_ BO_  "UsrMsgIDSbackwardDeviation" INT 50 1000;
BA_DEF_ BO_  "GenMsgCycleTime" INT 0 2000;
BA_DEF_ BO_  "GenMsgStartDelayTime" INT 0 2000;
BA_DEF_ BO_  "GenMsgSendType" ENUM  "Cyclic","NoMsgSendType";
BA_DEF_ BO_  "GenMsgCycleTimeFast" INT 0 500;
BA_DEF_ BO_  "GenMsgDelayTime" INT 0 20;
BA_DEF_ BO_  "GenMsgILSupport" ENUM  "No","Yes";
BA_DEF_ BO_  "GenMsgNrOfRepetition" INT 0 3;
BA_DEF_ BO_  "NmMessage" ENUM  "No","Yes";
BA_DEF_ BO_  "NWM-Botschaft" ENUM  "No","Yes";
BA_DEF_ BO_  "TpTxIndex" INT 0 65535;
BA_DEF_ BO_  "VFrameFormat" ENUM  "StandardCAN","ExtendedCAN","reserved","reserved","reserved","reserved","reserved","reserved","reserved","reserved","reserved","reserved","reserved","reserved","StandardCAN_FD","ExtendedCAN_FD";
BA_DEF_ SG_  "UserSigValidity" ENUM  "B+","ACC","IG","IG1","IG2","IG3","IG1 or IG2","IG1 or IG3","Undef";
BA_DEF_ SG_  "TimeoutValue" STRING ;
BA_DEF_ SG_  "UsrSigPurpose" ENUM  "Undef","FN","DIAG","DIAG(Req)","DIAG(Res)","DIAG(Phy)","DEV","CCP(Req)","CCP(Res)","NM","TP";
BA_DEF_ SG_  "GenSigStartValue" INT 0 1215752192;
BA_DEF_ SG_  "NetworkRequest" ENUM  "Yes","No";
BA_DEF_ SG_  "NetworkRequestHoldingTime" INT 0 65535;
BA_DEF_ SG_  "Description" STRING ;
BA_DEF_ SG_  "Version" STRING ;
BA_DEF_ SG_  "GenSigEnvVarType" ENUM  "Int","Float","Undef";
BA_DEF_ SG_  "GenSigSendType" ENUM  "Cyclic","OnWrite","OnWriteWithRepetition","OnChange","OnChangeWithRepetition","IfActive","IfActiveWithRepetition","NoSigSendType","OnChangeAndIfActive","OnChangeAndIfActiveWithRepetition";
BA_DEF_ SG_  "GwSigLatencyTime" INT 0 65536;
BA_DEF_ SG_  "GwSigMissingSourceType" ENUM  "Undef","OldValue","DefaultValue","InitialValue";
BA_DEF_ SG_  "NWM-WakeupAllowed" ENUM  "<n.a.>";
BA_DEF_ SG_  "RoutingFactor" INT 1 1215752192;
BA_DEF_ SG_  "SystemSignalLongSymbol" STRING ;
BA_DEF_REL_ BU_SG_REL_  "GenSigTimeoutTime" INT 0 7000;
BA_DEF_DEF_  "DiagState" "No";
BA_DEF_DEF_  "DiagResponse" "No";
BA_DEF_DEF_  "DiagRequest" "No";
BA_DEF_DEF_  "TpMessage" "No";
BA_DEF_DEF_  "UsrMsgIDSforwardDeviation" 10;
BA_DEF_DEF_  "UsrMsgIDSbackwardDeviation" 100;
BA_DEF_DEF_  "GenMsgCycleTime" 200;
BA_DEF_DEF_  "GenMsgStartDelayTime" 0;
BA_DEF_DEF_  "GenMsgSendType" "NoMsgSendType";
BA_DEF_DEF_  "GenMsgCycleTimeFast" 40;
BA_DEF_DEF_  "GenMsgDelayTime" 20;
BA_DEF_DEF_  "GenMsgILSupport" "Yes";
BA_DEF_DEF_  "GenMsgNrOfRepetition" 3;
BA_DEF_DEF_  "NmMessage" "No";
BA_DEF_DEF_  "NWM-Botschaft" "No";
BA_DEF_DEF_  "TpTxIndex" 0;
BA_DEF_DEF_  "VFrameFormat" "StandardCAN";
BA_DEF_DEF_  "UserSigValidity" "IG";
BA_DEF_DEF_  "TimeoutValue" "";
BA_DEF_DEF_  "UsrSigPurpose" "FN";
BA_DEF_DEF_  "GenSigStartValue" 0;
BA_DEF_DEF_  "NetworkRequest" "No";
BA_DEF_DEF_  "NetworkRequestHoldingTime" 0;
BA_DEF_DEF_  "Description" "";
BA_DEF_DEF_  "Version" "";
BA_DEF_DEF_  "GenSigEnvVarType" "Undef";
BA_DEF_DEF_  "GenSigSendType" "NoSigSendType";
BA_DEF_DEF_  "GwSigLatencyTime" 40;
BA_DEF_DEF_  "GwSigMissingSourceType" "Undef";
BA_DEF_DEF_  "NWM-WakeupAllowed" "<n.a.>";
BA_DEF_DEF_  "RoutingFactor" 1;
BA_DEF_DEF_REL_ "GenSigTimeoutTime" 500;
BA_DEF_DEF_  "SystemSignalLongSymbol" "";
BA_ "VFrameFormat" BO_ 2176875010 1;
BA_ "GenMsgNrOfRepetition" BO_ 2176875010 0;
BA_ "GenMsgCycleTimeFast" BO_ 2176875010 0;
BA_ "GenMsgCycleTime" BO_ 2176875010 100;
BA_ "GenMsgSendType" BO_ 2176875010 0;
BA_ "GenMsgSendType" BO_ 1130 0;
BA_ "VFrameFormat" BO_ 2176875011 1;
BA_ "GenMsgNrOfRepetition" BO_ 2176875011 0;
BA_ "GenMsgCycleTimeFast" BO_ 2176875011 0;
BA_ "GenMsgCycleTime" BO_ 2176875011 100;
BA_ "GenMsgSendType" BO_ 2176875011 0;
BA_ "GenMsgSendType" BO_ 1131 0;
BA_ "GenMsgSendType" BO_ 1128 0;
BA_ "VFrameFormat" BO_ 2176875009 1;
BA_ "GenMsgNrOfRepetition" BO_ 2176875009 0;
BA_ "GenMsgCycleTimeFast" BO_ 2176875009 0;
BA_ "GenMsgCycleTime" BO_ 2176875009 100;
BA_ "GenMsgSendType" BO_ 2176875009 0;
BA_ "GenMsgSendType" BO_ 1129 0;
BA_ "GenMsgSendType" BO_ 1124 0;
BA_ "GenMsgSendType" BO_ 1141 0;
BA_ "VFrameFormat" BO_ 2244046850 1;
BA_ "GenMsgNrOfRepetition" BO_ 2244046850 0;
BA_ "GenMsgCycleTimeFast" BO_ 2244046850 0;
BA_ "GenMsgCycleTime" BO_ 2244046850 100;
BA_ "GenMsgSendType" BO_ 2244046850 0;
BA_ "VFrameFormat" BO_ 2244046849 1;
BA_ "GenMsgNrOfRepetition" BO_ 2244046849 0;
BA_ "GenMsgCycleTimeFast" BO_ 2244046849 0;
BA_ "GenMsgCycleTime" BO_ 2244046849 100;
BA_ "GenMsgSendType" BO_ 2244046849 0;
BA_ "GenMsgSendType" BO_ 1027 0;
BA_ "GenMsgSendType" BO_ 1029 0;
BA_ "GenMsgSendType" BO_ 1030 0;
BA_ "GenMsgSendType" BO_ 1031 0;
BA_ "GenMsgSendType" BO_ 1048 0;
BA_ "GenMsgSendType" BO_ 1050 0;
BA_ "GenMsgSendType" BO_ 1052 0;
BA_ "GenMsgSendType" BO_ 1041 0;
BA_ "GenMsgSendType" BO_ 1040 0;
BA_ "GenMsgCycleTime" BO_ 95 0;
BA_ "GenMsgSendType" BO_ 1043 0;
BA_ "GenMsgSendType" BO_ 1044 0;
BA_ "Version" SG_ 2176875010 ECSIVSS_FLEstDmpVelVal "18.03.06";
BA_ "RoutingFactor" SG_ 2176875010 ECSIVSS_FLEstDmpVelVal 10;
BA_ "UserSigValidity" SG_ 2176875010 ECSIVSS_FLEstDmpVelVal 3;
BA_ "Description" SG_ 2176875010 ECSIVSS_FLEstDmpVelVal "Estimated Damper Velocity - FL

- Physical Range: -640 mm/s ~ 635 mm/s with factor 1";
BA_ "Version" SG_ 2176875010 ECSIVSS_FREstDmpVelVal "18.03.06";
BA_ "RoutingFactor" SG_ 2176875010 ECSIVSS_FREstDmpVelVal 10;
BA_ "UserSigValidity" SG_ 2176875010 ECSIVSS_FREstDmpVelVal 3;
BA_ "Description" SG_ 2176875010 ECSIVSS_FREstDmpVelVal "Estimated Damper Velocity - FR

- Physical Range: -640 mm/s ~ 635 mm/s with factor 1";
BA_ "Version" SG_ 2176875010 ECSIVSS_RLEstDmpVelVal "18.03.06";
BA_ "RoutingFactor" SG_ 2176875010 ECSIVSS_RLEstDmpVelVal 10;
BA_ "UserSigValidity" SG_ 2176875010 ECSIVSS_RLEstDmpVelVal 3;
BA_ "Description" SG_ 2176875010 ECSIVSS_RLEstDmpVelVal "Estimated Damper Velocity - RL

- Physical Range: -640 mm/s ~ 635 mm/s with factor 1";
BA_ "Version" SG_ 2176875010 ECSIVSS_RREstDmpVelVal "18.03.06";
BA_ "RoutingFactor" SG_ 2176875010 ECSIVSS_RREstDmpVelVal 10;
BA_ "UserSigValidity" SG_ 2176875010 ECSIVSS_RREstDmpVelVal 3;
BA_ "Description" SG_ 2176875010 ECSIVSS_RREstDmpVelVal "Estimated Damper Velocity - RR

- Physical Range: -640 mm/s ~ 635 mm/s with factor 1";
BA_ "Version" SG_ 2176875010 ECSIVSS_DmpCtrlrErrSta "18.07.04";
BA_ "RoutingFactor" SG_ 2176875010 ECSIVSS_DmpCtrlrErrSta 10;
BA_ "UserSigValidity" SG_ 2176875010 ECSIVSS_DmpCtrlrErrSta 3;
BA_ "Description" SG_ 2176875010 ECSIVSS_DmpCtrlrErrSta "ECS Damper Controller Error Status";
BA_ "Version" SG_ 2176875010 ECSIVSS_IVSSCtrlrErrSta "18.07.04";
BA_ "RoutingFactor" SG_ 2176875010 ECSIVSS_IVSSCtrlrErrSta 10;
BA_ "UserSigValidity" SG_ 2176875010 ECSIVSS_IVSSCtrlrErrSta 3;
BA_ "Description" SG_ 2176875010 ECSIVSS_IVSSCtrlrErrSta "IVSS Controller Error Status";
BA_ "Version" SG_ 2176875010 ECSIVSS_AntRollCtrlSta "18.07.04";
BA_ "RoutingFactor" SG_ 2176875010 ECSIVSS_AntRollCtrlSta 10;
BA_ "UserSigValidity" SG_ 2176875010 ECSIVSS_AntRollCtrlSta 3;
BA_ "Description" SG_ 2176875010 ECSIVSS_AntRollCtrlSta "Anti-Roll Control Activation Status";
BA_ "Version" SG_ 2176875010 ECSIVSS_RdRoughVal "17.11.00";
BA_ "RoutingFactor" SG_ 2176875010 ECSIVSS_RdRoughVal 10;
BA_ "UserSigValidity" SG_ 2176875010 ECSIVSS_RdRoughVal 3;
BA_ "Description" SG_ 2176875010 ECSIVSS_RdRoughVal "Road Roughness

(0: Flat ~ 253: Rough)";
BA_ "Version" SG_ 2176875010 ECSIVSS_FLCtrlSta "18.12.01";
BA_ "RoutingFactor" SG_ 2176875010 ECSIVSS_FLCtrlSta 10;
BA_ "UserSigValidity" SG_ 2176875010 ECSIVSS_FLCtrlSta 3;
BA_ "Description" SG_ 2176875010 ECSIVSS_FLCtrlSta "ECS Control System Status - FL";
BA_ "Version" SG_ 1130 DLBCU_LumbarUpDis "18.03.07";
BA_ "NetworkRequestHoldingTime" SG_ 1130 DLBCU_LumbarUpDis 5000;
BA_ "NetworkRequest" SG_ 1130 DLBCU_LumbarUpDis 0;
BA_ "UserSigValidity" SG_ 1130 DLBCU_LumbarUpDis 1;
BA_ "GenSigSendType" SG_ 1130 DLBCU_LumbarUpDis 4;
BA_ "Description" SG_ 1130 DLBCU_LumbarUpDis "This signal is used to display the seat movement to AVN";
BA_ "Version" SG_ 1130 DLBCU_LumbarMidDis "18.03.07";
BA_ "NetworkRequestHoldingTime" SG_ 1130 DLBCU_LumbarMidDis 5000;
BA_ "NetworkRequest" SG_ 1130 DLBCU_LumbarMidDis 0;
BA_ "UserSigValidity" SG_ 1130 DLBCU_LumbarMidDis 1;
BA_ "GenSigSendType" SG_ 1130 DLBCU_LumbarMidDis 4;
BA_ "Description" SG_ 1130 DLBCU_LumbarMidDis "This signal is used to display the seat movement to AVN";
BA_ "Version" SG_ 1130 DLBCU_LumbarLowDis "18.03.07";
BA_ "NetworkRequestHoldingTime" SG_ 1130 DLBCU_LumbarLowDis 5000;
BA_ "NetworkRequest" SG_ 1130 DLBCU_LumbarLowDis 0;
BA_ "UserSigValidity" SG_ 1130 DLBCU_LumbarLowDis 1;
BA_ "GenSigSendType" SG_ 1130 DLBCU_LumbarLowDis 4;
BA_ "Description" SG_ 1130 DLBCU_LumbarLowDis "This signal is used to display the seat movement to AVN";
BA_ "Version" SG_ 1130 DLBCU_LumbarDefDis "18.03.07";
BA_ "NetworkRequestHoldingTime" SG_ 1130 DLBCU_LumbarDefDis 5000;
BA_ "NetworkRequest" SG_ 1130 DLBCU_LumbarDefDis 0;
BA_ "UserSigValidity" SG_ 1130 DLBCU_LumbarDefDis 1;
BA_ "GenSigSendType" SG_ 1130 DLBCU_LumbarDefDis 4;
BA_ "Description" SG_ 1130 DLBCU_LumbarDefDis "This signal is used to display the seat movement to AVN";
BA_ "Version" SG_ 2176875011 ECSIVSS_FRCtrlSta "18.12.01";
BA_ "RoutingFactor" SG_ 2176875011 ECSIVSS_FRCtrlSta 10;
BA_ "UserSigValidity" SG_ 2176875011 ECSIVSS_FRCtrlSta 3;
BA_ "Description" SG_ 2176875011 ECSIVSS_FRCtrlSta "ECS Control System Status ? FR";
BA_ "Version" SG_ 2176875011 ECSIVSS_RLCtrlSta "18.12.01";
BA_ "RoutingFactor" SG_ 2176875011 ECSIVSS_RLCtrlSta 10;
BA_ "UserSigValidity" SG_ 2176875011 ECSIVSS_RLCtrlSta 3;
BA_ "Description" SG_ 2176875011 ECSIVSS_RLCtrlSta "ECS Control System Status ? RL";
BA_ "Version" SG_ 2176875011 ECSIVSS_RRCtrlSta "18.12.01";
BA_ "RoutingFactor" SG_ 2176875011 ECSIVSS_RRCtrlSta 10;
BA_ "UserSigValidity" SG_ 2176875011 ECSIVSS_RRCtrlSta 3;
BA_ "Description" SG_ 2176875011 ECSIVSS_RRCtrlSta "ECS Control System Status - RR";
BA_ "Version" SG_ 1131 DLBCU_BolsterInfDis "18.03.07";
BA_ "NetworkRequestHoldingTime" SG_ 1131 DLBCU_BolsterInfDis 5000;
BA_ "NetworkRequest" SG_ 1131 DLBCU_BolsterInfDis 0;
BA_ "UserSigValidity" SG_ 1131 DLBCU_BolsterInfDis 1;
BA_ "GenSigSendType" SG_ 1131 DLBCU_BolsterInfDis 4;
BA_ "Description" SG_ 1131 DLBCU_BolsterInfDis "This signal is used to display the seat movement to AVN";
BA_ "Version" SG_ 1131 DLBCU_BolsterDefDis "18.03.07";
BA_ "NetworkRequestHoldingTime" SG_ 1131 DLBCU_BolsterDefDis 5000;
BA_ "NetworkRequest" SG_ 1131 DLBCU_BolsterDefDis 0;
BA_ "UserSigValidity" SG_ 1131 DLBCU_BolsterDefDis 1;
BA_ "GenSigSendType" SG_ 1131 DLBCU_BolsterDefDis 4;
BA_ "Description" SG_ 1131 DLBCU_BolsterDefDis "This signal is used to display the seat movement to AVN";
BA_ "Version" SG_ 1128 DPSS_Crc2Val "21.09.03";
BA_ "UserSigValidity" SG_ 1128 DPSS_Crc2Val 0;
BA_ "GenSigSendType" SG_ 1128 DPSS_Crc2Val 4;
BA_ "Description" SG_ 1128 DPSS_Crc2Val "The data area for CRC calculation is based on the data length (DLC) of the message DB.

The CRC shall be calculated over the entire data block (excluding the CRC bytes) including the user data, alive counter and Data ID 

 

- CRC Polynomial (0x1D) , Ini";
BA_ "Version" SG_ 1128 DPSS_AlvCnt2Val "21.09.03";
BA_ "UserSigValidity" SG_ 1128 DPSS_AlvCnt2Val 0;
BA_ "GenSigSendType" SG_ 1128 DPSS_AlvCnt2Val 4;
BA_ "Description" SG_ 1128 DPSS_AlvCnt2Val "For the first transmission request for a data element the counter shall be initialized with 0 and shall be incremented by 1

for every subsequent send request. When the counter reaches the maximum value(0xE), then it shall restart with 0 for the next sen";
BA_ "Version" SG_ 1128 DPSS_LumbarUpSw "20.03.01";
BA_ "NetworkRequestHoldingTime" SG_ 1128 DPSS_LumbarUpSw 5000;
BA_ "NetworkRequest" SG_ 1128 DPSS_LumbarUpSw 0;
BA_ "UserSigValidity" SG_ 1128 DPSS_LumbarUpSw 0;
BA_ "GenSigSendType" SG_ 1128 DPSS_LumbarUpSw 4;
BA_ "Description" SG_ 1128 DPSS_LumbarUpSw "¿îÀü¼® ·³¹ö ¾÷ ½ºÀ§Ä¡";
BA_ "Version" SG_ 1128 DPSS_LumbarMidSw "20.03.01";
BA_ "NetworkRequestHoldingTime" SG_ 1128 DPSS_LumbarMidSw 5000;
BA_ "NetworkRequest" SG_ 1128 DPSS_LumbarMidSw 0;
BA_ "UserSigValidity" SG_ 1128 DPSS_LumbarMidSw 0;
BA_ "GenSigSendType" SG_ 1128 DPSS_LumbarMidSw 4;
BA_ "Description" SG_ 1128 DPSS_LumbarMidSw "¿îÀü¼® ·³¹ö ¹Ìµé ½ºÀ§Ä¡";
BA_ "Version" SG_ 1128 DPSS_LumbarLowSw "20.03.01";
BA_ "NetworkRequestHoldingTime" SG_ 1128 DPSS_LumbarLowSw 5000;
BA_ "NetworkRequest" SG_ 1128 DPSS_LumbarLowSw 0;
BA_ "UserSigValidity" SG_ 1128 DPSS_LumbarLowSw 0;
BA_ "GenSigSendType" SG_ 1128 DPSS_LumbarLowSw 4;
BA_ "Description" SG_ 1128 DPSS_LumbarLowSw "¿îÀü¼® ·³¹ö ÇÏ´Ü ¹öÆ°";
BA_ "Version" SG_ 1128 DPSS_LumbarDefSw "20.03.01";
BA_ "NetworkRequestHoldingTime" SG_ 1128 DPSS_LumbarDefSw 5000;
BA_ "NetworkRequest" SG_ 1128 DPSS_LumbarDefSw 0;
BA_ "UserSigValidity" SG_ 1128 DPSS_LumbarDefSw 0;
BA_ "GenSigSendType" SG_ 1128 DPSS_LumbarDefSw 4;
BA_ "Description" SG_ 1128 DPSS_LumbarDefSw "¿îÀü¼® ·³¹ö µðÇÃ·¹ÀÌ¼Ç ¹öÆ°";
BA_ "Version" SG_ 1128 DPSS_BolsterInfSw "20.03.01";
BA_ "NetworkRequestHoldingTime" SG_ 1128 DPSS_BolsterInfSw 5000;
BA_ "NetworkRequest" SG_ 1128 DPSS_BolsterInfSw 0;
BA_ "UserSigValidity" SG_ 1128 DPSS_BolsterInfSw 0;
BA_ "GenSigSendType" SG_ 1128 DPSS_BolsterInfSw 4;
BA_ "Description" SG_ 1128 DPSS_BolsterInfSw "¿îÀü¼® º¼½ºÅÍ Èí±â ¹öÆ°";
BA_ "Version" SG_ 1128 DPSS_BolsterDefSw "20.03.01";
BA_ "NetworkRequestHoldingTime" SG_ 1128 DPSS_BolsterDefSw 5000;
BA_ "NetworkRequest" SG_ 1128 DPSS_BolsterDefSw 0;
BA_ "UserSigValidity" SG_ 1128 DPSS_BolsterDefSw 0;
BA_ "GenSigSendType" SG_ 1128 DPSS_BolsterDefSw 4;
BA_ "Description" SG_ 1128 DPSS_BolsterDefSw "¿îÀü¼® º¼½ºÅÍ ¹è±â ¹öÆ°";
BA_ "Version" SG_ 1128 DPSS_ActiveSw "20.03.01";
BA_ "NetworkRequestHoldingTime" SG_ 1128 DPSS_ActiveSw 5000;
BA_ "NetworkRequest" SG_ 1128 DPSS_ActiveSw 0;
BA_ "UserSigValidity" SG_ 1128 DPSS_ActiveSw 0;
BA_ "GenSigSendType" SG_ 1128 DPSS_ActiveSw 4;
BA_ "Description" SG_ 1128 DPSS_ActiveSw "¿îÀü¼® Äí¼Ç º¼½ºÅÍ Á¶Àý ½ºÀ§Ä¡";
BA_ "Version" SG_ 1128 DPSS_CushInfSw "20.03.01";
BA_ "NetworkRequestHoldingTime" SG_ 1128 DPSS_CushInfSw 5000;
BA_ "NetworkRequest" SG_ 1128 DPSS_CushInfSw 0;
BA_ "UserSigValidity" SG_ 1128 DPSS_CushInfSw 0;
BA_ "GenSigSendType" SG_ 1128 DPSS_CushInfSw 4;
BA_ "Description" SG_ 1128 DPSS_CushInfSw "¿îÀü¼® Äí¼Ç°ø¾ÐÁ¶Àý Èí±â ¹öÆ°";
BA_ "Version" SG_ 1128 DPSS_CushDefSw "20.03.01";
BA_ "NetworkRequestHoldingTime" SG_ 1128 DPSS_CushDefSw 5000;
BA_ "NetworkRequest" SG_ 1128 DPSS_CushDefSw 0;
BA_ "UserSigValidity" SG_ 1128 DPSS_CushDefSw 0;
BA_ "GenSigSendType" SG_ 1128 DPSS_CushDefSw 4;
BA_ "Description" SG_ 1128 DPSS_CushDefSw "¿îÀü¼® Äí¼Ç °ø¾Ð Á¶Àý ¹è±â ¹öÆ°";
BA_ "Version" SG_ 2176875009 ECS_Crc3Val "21.09.03";
BA_ "RoutingFactor" SG_ 2176875009 ECS_Crc3Val 10;
BA_ "UserSigValidity" SG_ 2176875009 ECS_Crc3Val 3;
BA_ "GenSigStartValue" SG_ 2176875009 ECS_Crc3Val 65535;
BA_ "Description" SG_ 2176875009 ECS_Crc3Val "The data area for CRC calculation is based on the data length (DLC) of the message DB.

The CRC shall be calculated over the entire data block (excluding the CRC bytes) including the user data, alive counter and Data ID



- CRC Polynomial (0x1021) , Ini";
BA_ "Version" SG_ 2176875009 ECS_AlvCnt3Val "21.09.03";
BA_ "RoutingFactor" SG_ 2176875009 ECS_AlvCnt3Val 10;
BA_ "UserSigValidity" SG_ 2176875009 ECS_AlvCnt3Val 3;
BA_ "Description" SG_ 2176875009 ECS_AlvCnt3Val "For the first transmission request for a data element the counter shall be initialized with 0 and shall be incremented by 1 for every subsequent send request. 

When the counter reaches the maximum value(0xFF), then it shall restart with 0 for the next s";
BA_ "Version" SG_ 2176875009 ECSIVSS_FLFinCurrentVal "18.11.01";
BA_ "RoutingFactor" SG_ 2176875009 ECSIVSS_FLFinCurrentVal 10;
BA_ "UserSigValidity" SG_ 2176875009 ECSIVSS_FLFinCurrentVal 3;
BA_ "Description" SG_ 2176875009 ECSIVSS_FLFinCurrentVal "ECS Final Current FL (%)

- 0%: Full Soft, 100%: Full Hard

- 0x00~0xC8:0~100%/0xC9~0xFE:Not used/0xFF:Invalid";
BA_ "Version" SG_ 2176875009 ECSIVSS_FRFinCurrentVal "18.11.01";
BA_ "RoutingFactor" SG_ 2176875009 ECSIVSS_FRFinCurrentVal 10;
BA_ "UserSigValidity" SG_ 2176875009 ECSIVSS_FRFinCurrentVal 3;
BA_ "Description" SG_ 2176875009 ECSIVSS_FRFinCurrentVal "ECS Final Current FR (%)

- 0%: Full Soft, 100%: Full Hard

- 0x00~0xC8:0~100%/0xC9~0xFE:Not used/0xFF:Invalid";
BA_ "Version" SG_ 2176875009 ECSIVSS_RLFinCurrentVal "18.11.01";
BA_ "RoutingFactor" SG_ 2176875009 ECSIVSS_RLFinCurrentVal 10;
BA_ "UserSigValidity" SG_ 2176875009 ECSIVSS_RLFinCurrentVal 3;
BA_ "Description" SG_ 2176875009 ECSIVSS_RLFinCurrentVal "ECS Final Current RL (%)

- 0%: Full Soft, 100%: Full Hard

- 0x00~0xC8:0~100%/0xC9~0xFE:Not used/0xFF:Invalid";
BA_ "Version" SG_ 2176875009 ECSIVSS_RRFinCurrentVal "18.11.01";
BA_ "RoutingFactor" SG_ 2176875009 ECSIVSS_RRFinCurrentVal 10;
BA_ "UserSigValidity" SG_ 2176875009 ECSIVSS_RRFinCurrentVal 3;
BA_ "Description" SG_ 2176875009 ECSIVSS_RRFinCurrentVal "ECS Final Current RR (%)

- 0%: Full Soft, 100%: Full Hard

- 0x00~0xC8:0~100%/0xC9~0xFE:Not used/0xFF:Invalid";
BA_ "Version" SG_ 1129 DPSS_Crc3Val "22.05.03";
BA_ "UserSigValidity" SG_ 1129 DPSS_Crc3Val 0;
BA_ "GenSigSendType" SG_ 1129 DPSS_Crc3Val 4;
BA_ "Description" SG_ 1129 DPSS_Crc3Val "The data area for CRC calculation is based on the data length (DLC) of the message DB.

The CRC shall be calculated over the entire data block (excluding the CRC bytes) including the user data, alive counter and Data ID 

 

- CRC Polynomial (0x1D) , Ini";
BA_ "Version" SG_ 1129 DPSS_AlvCnt3Val "22.05.03";
BA_ "UserSigValidity" SG_ 1129 DPSS_AlvCnt3Val 0;
BA_ "GenSigSendType" SG_ 1129 DPSS_AlvCnt3Val 4;
BA_ "Description" SG_ 1129 DPSS_AlvCnt3Val "For the first transmission request for a data element the counter shall be initialized with 0 and shall be incremented by 1

for every subsequent send request. When the counter reaches the maximum value(0xE), then it shall restart with 0 for the next sen";
BA_ "Version" SG_ 1129 DPSS_SldTch "19.01.01";
BA_ "NetworkRequestHoldingTime" SG_ 1129 DPSS_SldTch 5000;
BA_ "NetworkRequest" SG_ 1129 DPSS_SldTch 0;
BA_ "UserSigValidity" SG_ 1129 DPSS_SldTch 3;
BA_ "GenSigSendType" SG_ 1129 DPSS_SldTch 4;
BA_ "Description" SG_ 1129 DPSS_SldTch "ÅÍÄ¡ ½ºÀ§Ä¡ Á¤º¸";
BA_ "Version" SG_ 1129 DPSS_RclTch "19.01.01";
BA_ "NetworkRequestHoldingTime" SG_ 1129 DPSS_RclTch 5000;
BA_ "NetworkRequest" SG_ 1129 DPSS_RclTch 0;
BA_ "UserSigValidity" SG_ 1129 DPSS_RclTch 3;
BA_ "GenSigSendType" SG_ 1129 DPSS_RclTch 4;
BA_ "Description" SG_ 1129 DPSS_RclTch "ÅÍÄ¡ ½ºÀ§Ä¡ Á¤º¸";
BA_ "Version" SG_ 1129 DPSS_ExtTch "19.01.01";
BA_ "NetworkRequestHoldingTime" SG_ 1129 DPSS_ExtTch 5000;
BA_ "NetworkRequest" SG_ 1129 DPSS_ExtTch 0;
BA_ "UserSigValidity" SG_ 1129 DPSS_ExtTch 3;
BA_ "GenSigSendType" SG_ 1129 DPSS_ExtTch 4;
BA_ "Description" SG_ 1129 DPSS_ExtTch "ÅÍÄ¡ ½ºÀ§Ä¡ Á¤º¸";
BA_ "Version" SG_ 1129 DPSS_LmbrTch "19.01.01";
BA_ "NetworkRequestHoldingTime" SG_ 1129 DPSS_LmbrTch 5000;
BA_ "NetworkRequest" SG_ 1129 DPSS_LmbrTch 0;
BA_ "UserSigValidity" SG_ 1129 DPSS_LmbrTch 3;
BA_ "GenSigSendType" SG_ 1129 DPSS_LmbrTch 4;
BA_ "Description" SG_ 1129 DPSS_LmbrTch "ÅÍÄ¡ ½ºÀ§Ä¡ Á¤º¸";
BA_ "Version" SG_ 1129 DPSS_CushOnOffTch "19.09.00";
BA_ "NetworkRequestHoldingTime" SG_ 1129 DPSS_CushOnOffTch 5000;
BA_ "NetworkRequest" SG_ 1129 DPSS_CushOnOffTch 0;
BA_ "UserSigValidity" SG_ 1129 DPSS_CushOnOffTch 3;
BA_ "GenSigSendType" SG_ 1129 DPSS_CushOnOffTch 4;
BA_ "Description" SG_ 1129 DPSS_CushOnOffTch "ÅÍÄ¡ ½ºÀ§Ä¡ Á¤º¸";
BA_ "Version" SG_ 1129 DPSS_HRestTch "19.11.09";
BA_ "NetworkRequestHoldingTime" SG_ 1129 DPSS_HRestTch 5000;
BA_ "NetworkRequest" SG_ 1129 DPSS_HRestTch 0;
BA_ "UserSigValidity" SG_ 1129 DPSS_HRestTch 3;
BA_ "GenSigSendType" SG_ 1129 DPSS_HRestTch 4;
BA_ "Description" SG_ 1129 DPSS_HRestTch "Çìµå·¹½ºÆ® ½ºÀ§Ä¡ ÅÍÄ¡ Á¤º¸";
BA_ "Version" SG_ 1129 DPSS_RelaxTch "21.07.05";
BA_ "NetworkRequestHoldingTime" SG_ 1129 DPSS_RelaxTch 5000;
BA_ "NetworkRequest" SG_ 1129 DPSS_RelaxTch 0;
BA_ "UserSigValidity" SG_ 1129 DPSS_RelaxTch 3;
BA_ "GenSigSendType" SG_ 1129 DPSS_RelaxTch 4;
BA_ "Description" SG_ 1129 DPSS_RelaxTch "ÅÍÄ¡ ½ºÀ§Ä¡ Á¤º¸";
BA_ "Version" SG_ 1129 DPSS_ThighTch "22.02.02";
BA_ "NetworkRequestHoldingTime" SG_ 1129 DPSS_ThighTch 5000;
BA_ "NetworkRequest" SG_ 1129 DPSS_ThighTch 0;
BA_ "UserSigValidity" SG_ 1129 DPSS_ThighTch 3;
BA_ "GenSigSendType" SG_ 1129 DPSS_ThighTch 4;
BA_ "Description" SG_ 1129 DPSS_ThighTch "¿îÀü¼® Äí¼Ç ¿¡¾î¼¿ ½ºÀ§Ä¡ ³ëºê ÅÍÄ¡ Á¤º¸";
BA_ "Version" SG_ 1129 DPSS_ExtThighTch "22.02.02";
BA_ "NetworkRequestHoldingTime" SG_ 1129 DPSS_ExtThighTch 5000;
BA_ "NetworkRequest" SG_ 1129 DPSS_ExtThighTch 0;
BA_ "UserSigValidity" SG_ 1129 DPSS_ExtThighTch 3;
BA_ "GenSigSendType" SG_ 1129 DPSS_ExtThighTch 4;
BA_ "Description" SG_ 1129 DPSS_ExtThighTch "¿îÀü¼® Äí¼Ç ÀÍ½ºÅÙ¼Ç&¿¡¾î¼¿ ½ºÀ§Ä¡ ³ëºê ÅÍÄ¡";
BA_ "Version" SG_ 1129 DPSS_LmbrBolsterTch "22.02.02";
BA_ "NetworkRequestHoldingTime" SG_ 1129 DPSS_LmbrBolsterTch 5000;
BA_ "NetworkRequest" SG_ 1129 DPSS_LmbrBolsterTch 0;
BA_ "UserSigValidity" SG_ 1129 DPSS_LmbrBolsterTch 3;
BA_ "GenSigSendType" SG_ 1129 DPSS_LmbrBolsterTch 4;
BA_ "Description" SG_ 1129 DPSS_LmbrBolsterTch "¿îÀü¼® ·³¹ö, º¼½ºÅÍ ³ëºê ÅÍÄ¡ Á¤º¸";
BA_ "Version" SG_ 1124 BCM_Crc15Val "21.09.03";
BA_ "UserSigValidity" SG_ 1124 BCM_Crc15Val 0;
BA_ "GenSigSendType" SG_ 1124 BCM_Crc15Val 4;
BA_ "Description" SG_ 1124 BCM_Crc15Val "The data area for CRC calculation is based on the data length (DLC) of the message DB.

The CRC shall be calculated over the entire data block (excluding the CRC bytes) including the user data, alive counter and Data ID 

 

- CRC Polynomial (0x1D) , Ini";
BA_ "Version" SG_ 1124 BCM_AlvCnt15Val "21.09.03";
BA_ "UserSigValidity" SG_ 1124 BCM_AlvCnt15Val 0;
BA_ "GenSigSendType" SG_ 1124 BCM_AlvCnt15Val 4;
BA_ "Description" SG_ 1124 BCM_AlvCnt15Val "For the first transmission request for a data element the counter shall be initialized with 0 and shall be incremented by 1

for every subsequent send request. When the counter reaches the maximum value(0xE), then it shall restart with 0 for the next sen";
BA_ "Version" SG_ 1124 Window_DrvrSdWdwActSta "18.02.01";
BA_ "NetworkRequestHoldingTime" SG_ 1124 Window_DrvrSdWdwActSta 5000;
BA_ "NetworkRequest" SG_ 1124 Window_DrvrSdWdwActSta 0;
BA_ "UserSigValidity" SG_ 1124 Window_DrvrSdWdwActSta 0;
BA_ "GenSigStartValue" SG_ 1124 Window_DrvrSdWdwActSta 15;
BA_ "GenSigSendType" SG_ 1124 Window_DrvrSdWdwActSta 4;
BA_ "Description" SG_ 1124 Window_DrvrSdWdwActSta "This signal indicates DRV Window Action Status";
BA_ "Version" SG_ 1124 Window_AsstSdWdwActSta "18.02.01";
BA_ "NetworkRequestHoldingTime" SG_ 1124 Window_AsstSdWdwActSta 5000;
BA_ "NetworkRequest" SG_ 1124 Window_AsstSdWdwActSta 0;
BA_ "UserSigValidity" SG_ 1124 Window_AsstSdWdwActSta 0;
BA_ "GenSigStartValue" SG_ 1124 Window_AsstSdWdwActSta 15;
BA_ "GenSigSendType" SG_ 1124 Window_AsstSdWdwActSta 4;
BA_ "Description" SG_ 1124 Window_AsstSdWdwActSta "This signal indicates AST Window Action Status";
BA_ "Version" SG_ 1124 Window_RrLftWdwActSta "18.02.01";
BA_ "NetworkRequestHoldingTime" SG_ 1124 Window_RrLftWdwActSta 5000;
BA_ "NetworkRequest" SG_ 1124 Window_RrLftWdwActSta 0;
BA_ "UserSigValidity" SG_ 1124 Window_RrLftWdwActSta 0;
BA_ "GenSigStartValue" SG_ 1124 Window_RrLftWdwActSta 15;
BA_ "GenSigSendType" SG_ 1124 Window_RrLftWdwActSta 4;
BA_ "Description" SG_ 1124 Window_RrLftWdwActSta "This signal indicates RL Window Action Status";
BA_ "Version" SG_ 1124 Window_RrRtWdwActSta "18.02.01";
BA_ "NetworkRequestHoldingTime" SG_ 1124 Window_RrRtWdwActSta 5000;
BA_ "NetworkRequest" SG_ 1124 Window_RrRtWdwActSta 0;
BA_ "UserSigValidity" SG_ 1124 Window_RrRtWdwActSta 0;
BA_ "GenSigStartValue" SG_ 1124 Window_RrRtWdwActSta 15;
BA_ "GenSigSendType" SG_ 1124 Window_RrRtWdwActSta 4;
BA_ "Description" SG_ 1124 Window_RrRtWdwActSta "This signal indicates RR Window Action Status";
BA_ "Version" SG_ 1124 Window_DrvrSdWdwDetailOpnSta "18.02.01";
BA_ "NetworkRequestHoldingTime" SG_ 1124 Window_DrvrSdWdwDetailOpnSta 5000;
BA_ "NetworkRequest" SG_ 1124 Window_DrvrSdWdwDetailOpnSta 0;
BA_ "UserSigValidity" SG_ 1124 Window_DrvrSdWdwDetailOpnSta 0;
BA_ "GenSigStartValue" SG_ 1124 Window_DrvrSdWdwDetailOpnSta 7;
BA_ "GenSigSendType" SG_ 1124 Window_DrvrSdWdwDetailOpnSta 4;
BA_ "Description" SG_ 1124 Window_DrvrSdWdwDetailOpnSta "This signal indicates DRV Window Open/Close Detail Status";
BA_ "Version" SG_ 1124 Window_AsstSdWdwDetailOpnSta "18.02.01";
BA_ "NetworkRequestHoldingTime" SG_ 1124 Window_AsstSdWdwDetailOpnSta 5000;
BA_ "NetworkRequest" SG_ 1124 Window_AsstSdWdwDetailOpnSta 0;
BA_ "UserSigValidity" SG_ 1124 Window_AsstSdWdwDetailOpnSta 0;
BA_ "GenSigStartValue" SG_ 1124 Window_AsstSdWdwDetailOpnSta 7;
BA_ "GenSigSendType" SG_ 1124 Window_AsstSdWdwDetailOpnSta 4;
BA_ "Description" SG_ 1124 Window_AsstSdWdwDetailOpnSta "This signal indicates AST Window Open/Close Detail Status";
BA_ "Version" SG_ 1124 Window_DrvrSdWdwErrAntPinch "18.02.01";
BA_ "NetworkRequestHoldingTime" SG_ 1124 Window_DrvrSdWdwErrAntPinch 5000;
BA_ "NetworkRequest" SG_ 1124 Window_DrvrSdWdwErrAntPinch 0;
BA_ "UserSigValidity" SG_ 1124 Window_DrvrSdWdwErrAntPinch 0;
BA_ "GenSigStartValue" SG_ 1124 Window_DrvrSdWdwErrAntPinch 1;
BA_ "GenSigSendType" SG_ 1124 Window_DrvrSdWdwErrAntPinch 4;
BA_ "Description" SG_ 1124 Window_DrvrSdWdwErrAntPinch "The DRV Window state whether Calibrated or not";
BA_ "Version" SG_ 1124 Window_RrLftWdwDetailOpnSta "18.02.01";
BA_ "NetworkRequestHoldingTime" SG_ 1124 Window_RrLftWdwDetailOpnSta 5000;
BA_ "NetworkRequest" SG_ 1124 Window_RrLftWdwDetailOpnSta 0;
BA_ "UserSigValidity" SG_ 1124 Window_RrLftWdwDetailOpnSta 0;
BA_ "GenSigStartValue" SG_ 1124 Window_RrLftWdwDetailOpnSta 7;
BA_ "GenSigSendType" SG_ 1124 Window_RrLftWdwDetailOpnSta 4;
BA_ "Description" SG_ 1124 Window_RrLftWdwDetailOpnSta "This signal indicates RL Window Open/Close Detail Status";
BA_ "Version" SG_ 1124 Window_RrRtWdwDetailOpnSta "18.02.01";
BA_ "NetworkRequestHoldingTime" SG_ 1124 Window_RrRtWdwDetailOpnSta 5000;
BA_ "NetworkRequest" SG_ 1124 Window_RrRtWdwDetailOpnSta 0;
BA_ "UserSigValidity" SG_ 1124 Window_RrRtWdwDetailOpnSta 0;
BA_ "GenSigStartValue" SG_ 1124 Window_RrRtWdwDetailOpnSta 7;
BA_ "GenSigSendType" SG_ 1124 Window_RrRtWdwDetailOpnSta 4;
BA_ "Description" SG_ 1124 Window_RrRtWdwDetailOpnSta "This signal indicates RR Window Open/Close Detail Status";
BA_ "Version" SG_ 1124 Window_AsstSdWdwErrAntPinch "18.02.01";
BA_ "NetworkRequestHoldingTime" SG_ 1124 Window_AsstSdWdwErrAntPinch 5000;
BA_ "NetworkRequest" SG_ 1124 Window_AsstSdWdwErrAntPinch 0;
BA_ "UserSigValidity" SG_ 1124 Window_AsstSdWdwErrAntPinch 0;
BA_ "GenSigStartValue" SG_ 1124 Window_AsstSdWdwErrAntPinch 1;
BA_ "GenSigSendType" SG_ 1124 Window_AsstSdWdwErrAntPinch 4;
BA_ "Description" SG_ 1124 Window_AsstSdWdwErrAntPinch "The AST Window state whether Calibrated or not";
BA_ "Version" SG_ 1124 Window_RrLftWdwErrAntPinch "18.02.01";
BA_ "NetworkRequestHoldingTime" SG_ 1124 Window_RrLftWdwErrAntPinch 5000;
BA_ "NetworkRequest" SG_ 1124 Window_RrLftWdwErrAntPinch 0;
BA_ "UserSigValidity" SG_ 1124 Window_RrLftWdwErrAntPinch 0;
BA_ "GenSigStartValue" SG_ 1124 Window_RrLftWdwErrAntPinch 1;
BA_ "GenSigSendType" SG_ 1124 Window_RrLftWdwErrAntPinch 4;
BA_ "Description" SG_ 1124 Window_RrLftWdwErrAntPinch "The RL Window state whether Calibrated or not";
BA_ "Version" SG_ 1124 Window_RrRtWdwErrAntPinch "18.02.01";
BA_ "NetworkRequestHoldingTime" SG_ 1124 Window_RrRtWdwErrAntPinch 5000;
BA_ "NetworkRequest" SG_ 1124 Window_RrRtWdwErrAntPinch 0;
BA_ "UserSigValidity" SG_ 1124 Window_RrRtWdwErrAntPinch 0;
BA_ "GenSigStartValue" SG_ 1124 Window_RrRtWdwErrAntPinch 1;
BA_ "GenSigSendType" SG_ 1124 Window_RrRtWdwErrAntPinch 4;
BA_ "Description" SG_ 1124 Window_RrRtWdwErrAntPinch "The RR Window state whether Calibrated or not";
BA_ "Version" SG_ 1124 SunRoof_RrBlindPosSta "20.01.01";
BA_ "UserSigValidity" SG_ 1124 SunRoof_RrBlindPosSta 0;
BA_ "GenSigStartValue" SG_ 1124 SunRoof_RrBlindPosSta 15;
BA_ "GenSigSendType" SG_ 1124 SunRoof_RrBlindPosSta 4;
BA_ "Description" SG_ 1124 SunRoof_RrBlindPosSta "This signal indicates Rear Sunroof Blind Open/Close Status";
BA_ "Version" SG_ 1141 Ast_SHVU_SeatOptSta "22.05.04";
BA_ "NetworkRequestHoldingTime" SG_ 1141 Ast_SHVU_SeatOptSta 5000;
BA_ "NetworkRequest" SG_ 1141 Ast_SHVU_SeatOptSta 0;
BA_ "UserSigValidity" SG_ 1141 Ast_SHVU_SeatOptSta 7;
BA_ "GenSigSendType" SG_ 1141 Ast_SHVU_SeatOptSta 4;
BA_ "Description" SG_ 1141 Ast_SHVU_SeatOptSta "µ¿½Â¼® ½ÃÆ®¿¡ Àû¿ëµÈ È÷ÅÍ/ÅëÇ³ ¿É¼Ç »ç¾ç";
BA_ "Version" SG_ 1141 Ast_SHVU_HtSwHiIndSta "22.05.04";
BA_ "NetworkRequestHoldingTime" SG_ 1141 Ast_SHVU_HtSwHiIndSta 5000;
BA_ "NetworkRequest" SG_ 1141 Ast_SHVU_HtSwHiIndSta 0;
BA_ "UserSigValidity" SG_ 1141 Ast_SHVU_HtSwHiIndSta 7;
BA_ "GenSigSendType" SG_ 1141 Ast_SHVU_HtSwHiIndSta 4;
BA_ "Description" SG_ 1141 Ast_SHVU_HtSwHiIndSta "µ¿½Â¼® ½ÃÆ® ¿­¼± ½ºÀ§Ä¡ High Indicator Á¤º¸";
BA_ "Version" SG_ 1141 Ast_SHVU_HtSwMidIndSta "22.05.04";
BA_ "NetworkRequestHoldingTime" SG_ 1141 Ast_SHVU_HtSwMidIndSta 5000;
BA_ "NetworkRequest" SG_ 1141 Ast_SHVU_HtSwMidIndSta 0;
BA_ "UserSigValidity" SG_ 1141 Ast_SHVU_HtSwMidIndSta 7;
BA_ "GenSigSendType" SG_ 1141 Ast_SHVU_HtSwMidIndSta 4;
BA_ "Description" SG_ 1141 Ast_SHVU_HtSwMidIndSta "µ¿½Â¼® ½ÃÆ® ¿­¼± ½ºÀ§Ä¡ Mid Indicator Á¤º¸";
BA_ "Version" SG_ 1141 Ast_SHVU_HtSwLowIndSta "22.05.04";
BA_ "NetworkRequestHoldingTime" SG_ 1141 Ast_SHVU_HtSwLowIndSta 5000;
BA_ "NetworkRequest" SG_ 1141 Ast_SHVU_HtSwLowIndSta 0;
BA_ "UserSigValidity" SG_ 1141 Ast_SHVU_HtSwLowIndSta 7;
BA_ "GenSigSendType" SG_ 1141 Ast_SHVU_HtSwLowIndSta 4;
BA_ "Description" SG_ 1141 Ast_SHVU_HtSwLowIndSta "µ¿½Â¼® ½ÃÆ® ¿­¼± ½ºÀ§Ä¡ Low Indicator Á¤º¸";
BA_ "Version" SG_ 1141 Ast_SHVU_VntSwHiIndSta "22.05.04";
BA_ "NetworkRequestHoldingTime" SG_ 1141 Ast_SHVU_VntSwHiIndSta 5000;
BA_ "NetworkRequest" SG_ 1141 Ast_SHVU_VntSwHiIndSta 0;
BA_ "UserSigValidity" SG_ 1141 Ast_SHVU_VntSwHiIndSta 7;
BA_ "GenSigSendType" SG_ 1141 Ast_SHVU_VntSwHiIndSta 4;
BA_ "Description" SG_ 1141 Ast_SHVU_VntSwHiIndSta "µ¿½Â¼® ½ÃÆ® ÅëÇ³ ½ºÀ§Ä¡ High Indicator Á¤º¸";
BA_ "Version" SG_ 1141 Ast_SHVU_VntSwMidIndSta "22.05.04";
BA_ "NetworkRequestHoldingTime" SG_ 1141 Ast_SHVU_VntSwMidIndSta 5000;
BA_ "NetworkRequest" SG_ 1141 Ast_SHVU_VntSwMidIndSta 0;
BA_ "UserSigValidity" SG_ 1141 Ast_SHVU_VntSwMidIndSta 7;
BA_ "GenSigSendType" SG_ 1141 Ast_SHVU_VntSwMidIndSta 4;
BA_ "Description" SG_ 1141 Ast_SHVU_VntSwMidIndSta "µ¿½Â¼® ½ÃÆ® ÅëÇ³ ½ºÀ§Ä¡ Mid Indicator Á¤º¸";
BA_ "Version" SG_ 1141 Ast_SHVU_VntSwLowIndSta "22.05.04";
BA_ "NetworkRequestHoldingTime" SG_ 1141 Ast_SHVU_VntSwLowIndSta 5000;
BA_ "NetworkRequest" SG_ 1141 Ast_SHVU_VntSwLowIndSta 0;
BA_ "UserSigValidity" SG_ 1141 Ast_SHVU_VntSwLowIndSta 7;
BA_ "GenSigSendType" SG_ 1141 Ast_SHVU_VntSwLowIndSta 4;
BA_ "Description" SG_ 1141 Ast_SHVU_VntSwLowIndSta "µ¿½Â¼® ½ÃÆ® ÅëÇ³ ½ºÀ§Ä¡ Low Indicator Á¤º¸";
BA_ "Version" SG_ 1141 Ast_SHVU_HtBlcUSMSta "22.05.04";
BA_ "UserSigValidity" SG_ 1141 Ast_SHVU_HtBlcUSMSta 7;
BA_ "GenSigSendType" SG_ 1141 Ast_SHVU_HtBlcUSMSta 4;
BA_ "Description" SG_ 1141 Ast_SHVU_HtBlcUSMSta "Hetaer Balance Assistant USM R vaule";
BA_ "Version" SG_ 1141 Ast_SHVU_SeatHtOperSta "22.05.04";
BA_ "NetworkRequestHoldingTime" SG_ 1141 Ast_SHVU_SeatHtOperSta 5000;
BA_ "NetworkRequest" SG_ 1141 Ast_SHVU_SeatHtOperSta 0;
BA_ "UserSigValidity" SG_ 1141 Ast_SHVU_SeatHtOperSta 7;
BA_ "GenSigSendType" SG_ 1141 Ast_SHVU_SeatHtOperSta 4;
BA_ "Description" SG_ 1141 Ast_SHVU_SeatHtOperSta "µ¿½Â¼® ½ÃÆ® ÇöÀç ÀÛµ¿ ÁßÀÎ È÷ÅÍ/ÅëÇ³ ´Ü¼ö »óÅÂ";
BA_ "Version" SG_ 1141 Ast_SHVU_HtSwHiIndSta_RHD "22.05.04";
BA_ "NetworkRequestHoldingTime" SG_ 1141 Ast_SHVU_HtSwHiIndSta_RHD 5000;
BA_ "NetworkRequest" SG_ 1141 Ast_SHVU_HtSwHiIndSta_RHD 0;
BA_ "UserSigValidity" SG_ 1141 Ast_SHVU_HtSwHiIndSta_RHD 7;
BA_ "GenSigSendType" SG_ 1141 Ast_SHVU_HtSwHiIndSta_RHD 4;
BA_ "Description" SG_ 1141 Ast_SHVU_HtSwHiIndSta_RHD "µ¿½Â¼® ½ÃÆ® ¿­¼± ½ºÀ§Ä¡ High Indicator Á¤º¸(RHD)";
BA_ "Version" SG_ 1141 Ast_SHVU_HtSwMidIndSta_RHD "22.05.04";
BA_ "NetworkRequestHoldingTime" SG_ 1141 Ast_SHVU_HtSwMidIndSta_RHD 5000;
BA_ "NetworkRequest" SG_ 1141 Ast_SHVU_HtSwMidIndSta_RHD 0;
BA_ "UserSigValidity" SG_ 1141 Ast_SHVU_HtSwMidIndSta_RHD 7;
BA_ "GenSigSendType" SG_ 1141 Ast_SHVU_HtSwMidIndSta_RHD 4;
BA_ "Description" SG_ 1141 Ast_SHVU_HtSwMidIndSta_RHD "µ¿½Â¼® ½ÃÆ® ¿­¼± ½ºÀ§Ä¡ Mid Indicator Á¤º¸(RHD)";
BA_ "Version" SG_ 1141 Ast_SHVU_HtSwLowIndSta_RHD "22.05.04";
BA_ "NetworkRequestHoldingTime" SG_ 1141 Ast_SHVU_HtSwLowIndSta_RHD 5000;
BA_ "NetworkRequest" SG_ 1141 Ast_SHVU_HtSwLowIndSta_RHD 0;
BA_ "UserSigValidity" SG_ 1141 Ast_SHVU_HtSwLowIndSta_RHD 7;
BA_ "GenSigSendType" SG_ 1141 Ast_SHVU_HtSwLowIndSta_RHD 4;
BA_ "Description" SG_ 1141 Ast_SHVU_HtSwLowIndSta_RHD "µ¿½Â¼® ½ÃÆ® ¿­¼± ½ºÀ§Ä¡ Low Indicator Á¤º¸(RHD)";
BA_ "Version" SG_ 1141 Ast_SHVU_VntSwHiIndSta_RHD "22.05.04";
BA_ "NetworkRequestHoldingTime" SG_ 1141 Ast_SHVU_VntSwHiIndSta_RHD 5000;
BA_ "NetworkRequest" SG_ 1141 Ast_SHVU_VntSwHiIndSta_RHD 0;
BA_ "UserSigValidity" SG_ 1141 Ast_SHVU_VntSwHiIndSta_RHD 7;
BA_ "GenSigSendType" SG_ 1141 Ast_SHVU_VntSwHiIndSta_RHD 4;
BA_ "Description" SG_ 1141 Ast_SHVU_VntSwHiIndSta_RHD "µ¿½Â¼® ½ÃÆ® ÅëÇ³ ½ºÀ§Ä¡ High Indicator Á¤º¸(RHD)";
BA_ "Version" SG_ 1141 Ast_SHVU_VntSwMidIndSta_RHD "22.05.04";
BA_ "NetworkRequestHoldingTime" SG_ 1141 Ast_SHVU_VntSwMidIndSta_RHD 5000;
BA_ "NetworkRequest" SG_ 1141 Ast_SHVU_VntSwMidIndSta_RHD 0;
BA_ "UserSigValidity" SG_ 1141 Ast_SHVU_VntSwMidIndSta_RHD 7;
BA_ "GenSigSendType" SG_ 1141 Ast_SHVU_VntSwMidIndSta_RHD 4;
BA_ "Description" SG_ 1141 Ast_SHVU_VntSwMidIndSta_RHD "µ¿½Â¼® ½ÃÆ® ÅëÇ³ ½ºÀ§Ä¡ Mid Indicator Á¤º¸(RHD)";
BA_ "Version" SG_ 1141 Ast_SHVU_VntSwLowIndSta_RHD "22.05.04";
BA_ "NetworkRequestHoldingTime" SG_ 1141 Ast_SHVU_VntSwLowIndSta_RHD 5000;
BA_ "NetworkRequest" SG_ 1141 Ast_SHVU_VntSwLowIndSta_RHD 0;
BA_ "UserSigValidity" SG_ 1141 Ast_SHVU_VntSwLowIndSta_RHD 7;
BA_ "GenSigSendType" SG_ 1141 Ast_SHVU_VntSwLowIndSta_RHD 4;
BA_ "Description" SG_ 1141 Ast_SHVU_VntSwLowIndSta_RHD "µ¿½Â¼® ½ÃÆ® ÅëÇ³ ½ºÀ§Ä¡ Low Indicator Á¤º¸(RHD)";
BA_ "Version" SG_ 2244046850 ADAS_PRK_PDW_SwIndOnReq "18.05.02";
BA_ "RoutingFactor" SG_ 2244046850 ADAS_PRK_PDW_SwIndOnReq 5;
BA_ "UserSigValidity" SG_ 2244046850 ADAS_PRK_PDW_SwIndOnReq 3;
BA_ "Description" SG_ 2244046850 ADAS_PRK_PDW_SwIndOnReq "-PDW Switch Indicator On/Off Request

This signal is used for PDW-R and PDW-F/R";
BA_ "Version" SG_ 2244046850 PCA_RrEquipChkSta "20.05.02";
BA_ "RoutingFactor" SG_ 2244046850 PCA_RrEquipChkSta 5;
BA_ "UserSigValidity" SG_ 2244046850 PCA_RrEquipChkSta 3;
BA_ "Description" SG_ 2244046850 PCA_RrEquipChkSta "PCA Rear Equipment Check Status";
BA_ "Version" SG_ 2244046850 ADAS_PRK_PDW_OptTyp "20.11.02";
BA_ "RoutingFactor" SG_ 2244046850 ADAS_PRK_PDW_OptTyp 5;
BA_ "UserSigValidity" SG_ 2244046850 ADAS_PRK_PDW_OptTyp 3;
BA_ "Description" SG_ 2244046850 ADAS_PRK_PDW_OptTyp "this signal means PDW Option (Non, PDW-R, PDW-FR, PDW-FSR)";
BA_ "Version" SG_ 2244046850 PCA_FrBndryLn "21.04.09";
BA_ "RoutingFactor" SG_ 2244046850 PCA_FrBndryLn 5;
BA_ "UserSigValidity" SG_ 2244046850 PCA_FrBndryLn 3;
BA_ "Version" SG_ 2244046850 PCA_RrBndryLn "21.04.09";
BA_ "RoutingFactor" SG_ 2244046850 PCA_RrBndryLn 5;
BA_ "UserSigValidity" SG_ 2244046850 PCA_RrBndryLn 3;
BA_ "Version" SG_ 2244046850 PCA_LtBndryLn "22.05.03";
BA_ "RoutingFactor" SG_ 2244046850 PCA_LtBndryLn 5;
BA_ "UserSigValidity" SG_ 2244046850 PCA_LtBndryLn 3;
BA_ "Version" SG_ 2244046850 PCA_RtBndryLn "22.05.03";
BA_ "RoutingFactor" SG_ 2244046850 PCA_RtBndryLn 5;
BA_ "UserSigValidity" SG_ 2244046850 PCA_RtBndryLn 3;
BA_ "Version" SG_ 2244046850 PCA_WrngPhrs "21.04.09";
BA_ "RoutingFactor" SG_ 2244046850 PCA_WrngPhrs 5;
BA_ "UserSigValidity" SG_ 2244046850 PCA_WrngPhrs 3;
BA_ "Version" SG_ 2244046850 ADAS_PRK_PDW_AutoOn_USM "18.05.02";
BA_ "RoutingFactor" SG_ 2244046850 ADAS_PRK_PDW_AutoOn_USM 5;
BA_ "UserSigValidity" SG_ 2244046850 ADAS_PRK_PDW_AutoOn_USM 3;
BA_ "Description" SG_ 2244046850 ADAS_PRK_PDW_AutoOn_USM "PDW system automatically on/off setting status";
BA_ "Version" SG_ 2244046850 PCA_FlrInfoSta "23.01.00";
BA_ "RoutingFactor" SG_ 2244046850 PCA_FlrInfoSta 5;
BA_ "UserSigValidity" SG_ 2244046850 PCA_FlrInfoSta 3;
BA_ "Description" SG_ 2244046850 PCA_FlrInfoSta "The signal is designed to deliver detailed information over PCA System Failure.

Bit 0 : DTC Failure

Bit 1 : Ultrasonic Sensor Failure

Bit 2 : Gear Position Signal Failure

Bit 3 : ESC Failure

Bit 4 : EPB Failure

Bit 5 : FAN Failure

Bit 6 : Door Sta";
BA_ "Version" SG_ 2244046850 PCA_FrSdEquipChkSta "20.05.02";
BA_ "RoutingFactor" SG_ 2244046850 PCA_FrSdEquipChkSta 5;
BA_ "UserSigValidity" SG_ 2244046850 PCA_FrSdEquipChkSta 3;
BA_ "Description" SG_ 2244046850 PCA_FrSdEquipChkSta "PCA Front Side Equipment Check Status";
BA_ "Version" SG_ 2244046849 ADAS_PRK_Crc1Val "21.09.03";
BA_ "RoutingFactor" SG_ 2244046849 ADAS_PRK_Crc1Val 5;
BA_ "UserSigValidity" SG_ 2244046849 ADAS_PRK_Crc1Val 3;
BA_ "GenSigStartValue" SG_ 2244046849 ADAS_PRK_Crc1Val 65535;
BA_ "Description" SG_ 2244046849 ADAS_PRK_Crc1Val "The data area for CRC calculation is based on the data length (DLC) of the message DB.

The CRC shall be calculated over the entire data block (excluding the CRC bytes) including the user data, alive counter and Data ID



- CRC Polynomial (0x1021) , Ini";
BA_ "Version" SG_ 2244046849 ADAS_PRK_AlvCnt1Val "21.09.03";
BA_ "RoutingFactor" SG_ 2244046849 ADAS_PRK_AlvCnt1Val 5;
BA_ "UserSigValidity" SG_ 2244046849 ADAS_PRK_AlvCnt1Val 3;
BA_ "Description" SG_ 2244046849 ADAS_PRK_AlvCnt1Val "For the first transmission request for a data element the counter shall be initialized with 0 and shall be incremented by 1 for every subsequent send request. 

When the counter reaches the maximum value(0xFF), then it shall restart with 0 for the next s";
BA_ "Version" SG_ 2244046849 PCA_SysFlrSta "22.04.01";
BA_ "RoutingFactor" SG_ 2244046849 PCA_SysFlrSta 5;
BA_ "UserSigValidity" SG_ 2244046849 PCA_SysFlrSta 3;
BA_ "Description" SG_ 2244046849 PCA_SysFlrSta "PCA Failure status";
BA_ "Version" SG_ 2244046849 PCA_ModDis "20.02.01";
BA_ "RoutingFactor" SG_ 2244046849 PCA_ModDis 5;
BA_ "UserSigValidity" SG_ 2244046849 PCA_ModDis 3;
BA_ "Description" SG_ 2244046849 PCA_ModDis "PCA Mode Display";
BA_ "Version" SG_ 2244046849 PCA_HptReq "20.02.03";
BA_ "RoutingFactor" SG_ 2244046849 PCA_HptReq 5;
BA_ "UserSigValidity" SG_ 2244046849 PCA_HptReq 3;
BA_ "Description" SG_ 2244046849 PCA_HptReq "PCA Haptic Request";
BA_ "Version" SG_ 2244046849 PCA_BrkReq "19.07.06";
BA_ "RoutingFactor" SG_ 2244046849 PCA_BrkReq 5;
BA_ "UserSigValidity" SG_ 2244046849 PCA_BrkReq 3;
BA_ "Description" SG_ 2244046849 PCA_BrkReq "Brake request

with EPB : 0x2 PCA Brake on (hold)

without EPB : 0x1 PCA Brake on";
BA_ "Version" SG_ 2244046849 PCA_EpbReq "19.07.06";
BA_ "RoutingFactor" SG_ 2244046849 PCA_EpbReq 5;
BA_ "UserSigValidity" SG_ 2244046849 PCA_EpbReq 3;
BA_ "Description" SG_ 2244046849 PCA_EpbReq "request to hold the vehicle, applying EPB";
BA_ "Version" SG_ 2244046849 PCA_DclTrgtVal "18.07.01";
BA_ "RoutingFactor" SG_ 2244046849 PCA_DclTrgtVal 5;
BA_ "UserSigValidity" SG_ 2244046849 PCA_DclTrgtVal 3;
BA_ "Description" SG_ 2244046849 PCA_DclTrgtVal "Deceleration target value";
BA_ "Version" SG_ 2244046849 PU_F_Group7_DrvrAsstFlr10Sta "22.04.01";
BA_ "RoutingFactor" SG_ 2244046849 PU_F_Group7_DrvrAsstFlr10Sta 5;
BA_ "UserSigValidity" SG_ 2244046849 PU_F_Group7_DrvrAsstFlr10Sta 3;
BA_ "Description" SG_ 2244046849 PU_F_Group7_DrvrAsstFlr10Sta "PDW & PCA Blockage / Failure Display (Full Pop-up)";
BA_ "Version" SG_ 2244046849 ADAS_PRK_PDW_SysFlrSta "20.11.02";
BA_ "RoutingFactor" SG_ 2244046849 ADAS_PRK_PDW_SysFlrSta 5;
BA_ "UserSigValidity" SG_ 2244046849 ADAS_PRK_PDW_SysFlrSta 3;
BA_ "Description" SG_ 2244046849 ADAS_PRK_PDW_SysFlrSta "PDW Failure Status";
BA_ "Version" SG_ 1027 Win_ElecChildLkSwOpt "21.07.05";
BA_ "NetworkRequestHoldingTime" SG_ 1027 Win_ElecChildLkSwOpt 5000;
BA_ "NetworkRequest" SG_ 1027 Win_ElecChildLkSwOpt 0;
BA_ "UserSigValidity" SG_ 1027 Win_ElecChildLkSwOpt 0;
BA_ "GenSigSendType" SG_ 1027 Win_ElecChildLkSwOpt 4;
BA_ "Version" SG_ 1027 Win_PwrWdwSwTyp "21.07.05";
BA_ "NetworkRequestHoldingTime" SG_ 1027 Win_PwrWdwSwTyp 5000;
BA_ "NetworkRequest" SG_ 1027 Win_PwrWdwSwTyp 0;
BA_ "UserSigValidity" SG_ 1027 Win_PwrWdwSwTyp 0;
BA_ "GenSigSendType" SG_ 1027 Win_PwrWdwSwTyp 4;
BA_ "Version" SG_ 1027 Win_DrvIMSSwSta "21.07.05";
BA_ "NetworkRequestHoldingTime" SG_ 1027 Win_DrvIMSSwSta 5000;
BA_ "NetworkRequest" SG_ 1027 Win_DrvIMSSwSta 0;
BA_ "UserSigValidity" SG_ 1027 Win_DrvIMSSwSta 0;
BA_ "GenSigSendType" SG_ 1027 Win_DrvIMSSwSta 4;
BA_ "Version" SG_ 1027 Win_DrvPwrWdwSwSta "21.07.05";
BA_ "NetworkRequestHoldingTime" SG_ 1027 Win_DrvPwrWdwSwSta 5000;
BA_ "NetworkRequest" SG_ 1027 Win_DrvPwrWdwSwSta 0;
BA_ "UserSigValidity" SG_ 1027 Win_DrvPwrWdwSwSta 0;
BA_ "GenSigSendType" SG_ 1027 Win_DrvPwrWdwSwSta 4;
BA_ "Version" SG_ 1027 Win_AsstPwrWdwSwSta "21.07.05";
BA_ "NetworkRequestHoldingTime" SG_ 1027 Win_AsstPwrWdwSwSta 5000;
BA_ "NetworkRequest" SG_ 1027 Win_AsstPwrWdwSwSta 0;
BA_ "UserSigValidity" SG_ 1027 Win_AsstPwrWdwSwSta 0;
BA_ "GenSigSendType" SG_ 1027 Win_AsstPwrWdwSwSta 4;
BA_ "Version" SG_ 1027 Win_CtrlDrLkSwSta "21.07.05";
BA_ "NetworkRequestHoldingTime" SG_ 1027 Win_CtrlDrLkSwSta 5000;
BA_ "NetworkRequest" SG_ 1027 Win_CtrlDrLkSwSta 0;
BA_ "UserSigValidity" SG_ 1027 Win_CtrlDrLkSwSta 0;
BA_ "GenSigSendType" SG_ 1027 Win_CtrlDrLkSwSta 4;
BA_ "Version" SG_ 1027 Win_RrLftPwrWdwSwSta "21.07.05";
BA_ "NetworkRequestHoldingTime" SG_ 1027 Win_RrLftPwrWdwSwSta 5000;
BA_ "NetworkRequest" SG_ 1027 Win_RrLftPwrWdwSwSta 0;
BA_ "UserSigValidity" SG_ 1027 Win_RrLftPwrWdwSwSta 0;
BA_ "GenSigSendType" SG_ 1027 Win_RrLftPwrWdwSwSta 4;
BA_ "Version" SG_ 1027 Win_RrRtPwrWdwSwSta "21.07.05";
BA_ "NetworkRequestHoldingTime" SG_ 1027 Win_RrRtPwrWdwSwSta 5000;
BA_ "NetworkRequest" SG_ 1027 Win_RrRtPwrWdwSwSta 0;
BA_ "UserSigValidity" SG_ 1027 Win_RrRtPwrWdwSwSta 0;
BA_ "GenSigSendType" SG_ 1027 Win_RrRtPwrWdwSwSta 4;
BA_ "Version" SG_ 1027 Win_CtrlDrUnLkSwSta "21.07.05";
BA_ "NetworkRequestHoldingTime" SG_ 1027 Win_CtrlDrUnLkSwSta 5000;
BA_ "NetworkRequest" SG_ 1027 Win_CtrlDrUnLkSwSta 0;
BA_ "UserSigValidity" SG_ 1027 Win_CtrlDrUnLkSwSta 0;
BA_ "GenSigSendType" SG_ 1027 Win_CtrlDrUnLkSwSta 4;
BA_ "Version" SG_ 1027 Win_PwrWdwLkSwSta "21.07.05";
BA_ "NetworkRequestHoldingTime" SG_ 1027 Win_PwrWdwLkSwSta 5000;
BA_ "NetworkRequest" SG_ 1027 Win_PwrWdwLkSwSta 0;
BA_ "UserSigValidity" SG_ 1027 Win_PwrWdwLkSwSta 0;
BA_ "GenSigSendType" SG_ 1027 Win_PwrWdwLkSwSta 4;
BA_ "Version" SG_ 1027 Win_RrCrtSwSta "21.07.05";
BA_ "NetworkRequestHoldingTime" SG_ 1027 Win_RrCrtSwSta 5000;
BA_ "NetworkRequest" SG_ 1027 Win_RrCrtSwSta 0;
BA_ "UserSigValidity" SG_ 1027 Win_RrCrtSwSta 0;
BA_ "GenSigSendType" SG_ 1027 Win_RrCrtSwSta 4;
BA_ "Version" SG_ 1029 ICU_Crc12Val "21.09.03";
BA_ "RoutingFactor" SG_ 1029 ICU_Crc12Val 0;
BA_ "UserSigValidity" SG_ 1029 ICU_Crc12Val 0;
BA_ "GenSigSendType" SG_ 1029 ICU_Crc12Val 4;
BA_ "Description" SG_ 1029 ICU_Crc12Val "The data area for CRC calculation is based on the data length (DLC) of the message DB.

The CRC shall be calculated over the entire data block (excluding the CRC bytes) including the user data, alive counter and Data ID 

 

- CRC Polynomial (0x1D) , Ini";
BA_ "Version" SG_ 1029 Warn_ChaDrSwRrSta "18.08.12";
BA_ "RoutingFactor" SG_ 1029 Warn_ChaDrSwRrSta 0;
BA_ "UserSigValidity" SG_ 1029 Warn_ChaDrSwRrSta 7;
BA_ "GenSigSendType" SG_ 1029 Warn_ChaDrSwRrSta 4;
BA_ "Description" SG_ 1029 Warn_ChaDrSwRrSta "Rear Charging Door Open Switch";
BA_ "Version" SG_ 1029 ICU_AlvCnt12Val "21.09.03";
BA_ "RoutingFactor" SG_ 1029 ICU_AlvCnt12Val 0;
BA_ "UserSigValidity" SG_ 1029 ICU_AlvCnt12Val 0;
BA_ "GenSigSendType" SG_ 1029 ICU_AlvCnt12Val 4;
BA_ "Description" SG_ 1029 ICU_AlvCnt12Val "For the first transmission request for a data element the counter shall be initialized with 0 and shall be incremented by 1

for every subsequent send request. When the counter reaches the maximum value(0xE), then it shall restart with 0 for the next sen";
BA_ "Version" SG_ 1029 DoorLock_CtrlDrLkSwSta_ICU "19.07.01";
BA_ "RoutingFactor" SG_ 1029 DoorLock_CtrlDrLkSwSta_ICU 0;
BA_ "NetworkRequestHoldingTime" SG_ 1029 DoorLock_CtrlDrLkSwSta_ICU 5000;
BA_ "NetworkRequest" SG_ 1029 DoorLock_CtrlDrLkSwSta_ICU 0;
BA_ "UserSigValidity" SG_ 1029 DoorLock_CtrlDrLkSwSta_ICU 0;
BA_ "GenSigSendType" SG_ 1029 DoorLock_CtrlDrLkSwSta_ICU 4;
BA_ "Description" SG_ 1029 DoorLock_CtrlDrLkSwSta_ICU "Central Door Lock Switch State

(DRV or AST or RL or RR Door trim)";
BA_ "Version" SG_ 1029 DoorLock_CtrlDrUnLkSwSta_ICU "19.07.01";
BA_ "RoutingFactor" SG_ 1029 DoorLock_CtrlDrUnLkSwSta_ICU 0;
BA_ "NetworkRequestHoldingTime" SG_ 1029 DoorLock_CtrlDrUnLkSwSta_ICU 5000;
BA_ "NetworkRequest" SG_ 1029 DoorLock_CtrlDrUnLkSwSta_ICU 0;
BA_ "UserSigValidity" SG_ 1029 DoorLock_CtrlDrUnLkSwSta_ICU 0;
BA_ "GenSigSendType" SG_ 1029 DoorLock_CtrlDrUnLkSwSta_ICU 4;
BA_ "Description" SG_ 1029 DoorLock_CtrlDrUnLkSwSta_ICU "Central Door Unlock Switch State

(DRV or AST or RL or RR Door trim)";
BA_ "Version" SG_ 1029 DoorLock_CtrlDrLkUnLkSwSta_ICU "19.07.01";
BA_ "RoutingFactor" SG_ 1029 DoorLock_CtrlDrLkUnLkSwSta_ICU 0;
BA_ "NetworkRequestHoldingTime" SG_ 1029 DoorLock_CtrlDrLkUnLkSwSta_ICU 5000;
BA_ "NetworkRequest" SG_ 1029 DoorLock_CtrlDrLkUnLkSwSta_ICU 0;
BA_ "UserSigValidity" SG_ 1029 DoorLock_CtrlDrLkUnLkSwSta_ICU 0;
BA_ "GenSigSendType" SG_ 1029 DoorLock_CtrlDrLkUnLkSwSta_ICU 4;
BA_ "Description" SG_ 1029 DoorLock_CtrlDrLkUnLkSwSta_ICU "Central Door Lock/Unlock Switch State

(C/PAD, Integrated & self return type)";
BA_ "Version" SG_ 1029 HEV_IGN3On_Req "20.04.04";
BA_ "RoutingFactor" SG_ 1029 HEV_IGN3On_Req 0;
BA_ "UserSigValidity" SG_ 1029 HEV_IGN3On_Req 7;
BA_ "GenSigSendType" SG_ 1029 HEV_IGN3On_Req 4;
BA_ "Description" SG_ 1029 HEV_IGN3On_Req "HEV IGN3 Relay Control Request State

0x0:Default (IG3 Off)

0x1:IG3 On (by BMS)

0x2:IG3 On (by IG1 On)

0x3:IG3 On (by AVNT)";
BA_ "Version" SG_ 1029 AutoLtOpt "20.09.00";
BA_ "RoutingFactor" SG_ 1029 AutoLtOpt 0;
BA_ "UserSigValidity" SG_ 1029 AutoLtOpt 0;
BA_ "GenSigSendType" SG_ 1029 AutoLtOpt 4;
BA_ "Description" SG_ 1029 AutoLtOpt "Auto Light »ç¾ç Àû¿ë ¿©ºÎ ¹× Àû¿ë ¿É¼Ç Á¤º¸ Ãâ·Â (¹ÌÀû¿ë/Àû¿ë)";
BA_ "Version" SG_ 1029 ICU_IGN3On_ReqState_New "24.05.01";
BA_ "RoutingFactor" SG_ 1029 ICU_IGN3On_ReqState_New 0;
BA_ "UserSigValidity" SG_ 1029 ICU_IGN3On_ReqState_New 7;
BA_ "GenSigSendType" SG_ 1029 ICU_IGN3On_ReqState_New 4;
BA_ "Description" SG_ 1029 ICU_IGN3On_ReqState_New "IGN3 Relay Control Request Unit State For EV/ PHEV Vehicle";
BA_ "Version" SG_ 1029 ICU_BattMngAlert "21.07.05";
BA_ "RoutingFactor" SG_ 1029 ICU_BattMngAlert 0;
BA_ "UserSigValidity" SG_ 1029 ICU_BattMngAlert 0;
BA_ "GenSigSendType" SG_ 1029 ICU_BattMngAlert 4;
BA_ "Description" SG_ 1029 ICU_BattMngAlert "This signal is for battery discharge warning.

1bit : Hazard

2bit : Tail

3bit~8bit : Reserved";
BA_ "Version" SG_ 1029 HLmpLoHiOptLtSrcTyp "20.09.00";
BA_ "RoutingFactor" SG_ 1029 HLmpLoHiOptLtSrcTyp 0;
BA_ "UserSigValidity" SG_ 1029 HLmpLoHiOptLtSrcTyp 0;
BA_ "GenSigSendType" SG_ 1029 HLmpLoHiOptLtSrcTyp 4;
BA_ "Description" SG_ 1029 HLmpLoHiOptLtSrcTyp "Head Low and High Lamp Option and Light Source Type";
BA_ "Version" SG_ 1029 PDC_PwrOnModePowerReq "23.07.05";
BA_ "RoutingFactor" SG_ 1029 PDC_PwrOnModePowerReq 0;
BA_ "UserSigValidity" SG_ 1029 PDC_PwrOnModePowerReq 0;
BA_ "TimeoutValue" SG_ 1029 PDC_PwrOnModePowerReq "0x0";
BA_ "GenSigSendType" SG_ 1029 PDC_PwrOnModePowerReq 4;
BA_ "Description" SG_ 1029 PDC_PwrOnModePowerReq "This is for high voltage battery discharge request at Power On mode of EV";
BA_ "Version" SG_ 1029 IGN3State_By_Bat "23.02.01";
BA_ "RoutingFactor" SG_ 1029 IGN3State_By_Bat 0;
BA_ "UserSigValidity" SG_ 1029 IGN3State_By_Bat 7;
BA_ "TimeoutValue" SG_ 1029 IGN3State_By_Bat "0x0";
BA_ "GenSigSendType" SG_ 1029 IGN3State_By_Bat 4;
BA_ "Description" SG_ 1029 IGN3State_By_Bat "Output status of ignition 3 by IBS or BMS request for HEV 12V auxiliary battery charging";
BA_ "Version" SG_ 1029 Warn_ChaDrSwFrtSta "18.08.12";
BA_ "RoutingFactor" SG_ 1029 Warn_ChaDrSwFrtSta 0;
BA_ "UserSigValidity" SG_ 1029 Warn_ChaDrSwFrtSta 7;
BA_ "GenSigSendType" SG_ 1029 Warn_ChaDrSwFrtSta 4;
BA_ "Description" SG_ 1029 Warn_ChaDrSwFrtSta "Front Charging Door Open Switch";
BA_ "Version" SG_ 1030 APSM_SWVerMajor1 "21.07.00";
BA_ "UserSigValidity" SG_ 1030 APSM_SWVerMajor1 0;
BA_ "GenSigSendType" SG_ 1030 APSM_SWVerMajor1 4;
BA_ "Description" SG_ 1030 APSM_SWVerMajor1 "Indicate the SCM software version as follows:

- The software version is displayed in three digits.

- The Major and Minor digits are separated by '.'

- Signal values are transmitted to ASCII codes.



¡Ø Example

APSM_SWVerMajor1 : 0x41 (HEX) -> ASCII ";
BA_ "Version" SG_ 1030 APSM_SWVerMinor1 "18.10.06";
BA_ "UserSigValidity" SG_ 1030 APSM_SWVerMinor1 0;
BA_ "GenSigSendType" SG_ 1030 APSM_SWVerMinor1 4;
BA_ "Description" SG_ 1030 APSM_SWVerMinor1 "Indicate the APSM software version as follows:

- The software version is displayed in three digits.

- The Major and Minor digits are separated by '.'

- Signal values are transmitted to ASCII codes.



¡Ø Example

APSM_SWVerMajor1 : 0x41 (HEX) -> ASCII";
BA_ "Version" SG_ 1030 APSM_SWVerMinor2 "18.10.06";
BA_ "UserSigValidity" SG_ 1030 APSM_SWVerMinor2 0;
BA_ "GenSigSendType" SG_ 1030 APSM_SWVerMinor2 4;
BA_ "Description" SG_ 1030 APSM_SWVerMinor2 "Indicate the APSM software version as follows:

- The software version is displayed in three digits.

- The Major and Minor digits are separated by '.'

- Signal values are transmitted to ASCII codes.



¡Ø Example

APSM_SWVerMajor1 : 0x41 (HEX) -> ASCII";
BA_ "Version" SG_ 1030 APSM_AstSeatPos_Sta "23.05.00";
BA_ "UserSigValidity" SG_ 1030 APSM_AstSeatPos_Sta 0;
BA_ "GenSigSendType" SG_ 1030 APSM_AstSeatPos_Sta 4;
BA_ "Description" SG_ 1030 APSM_AstSeatPos_Sta "The signal indicates the state of  Assist seat Meomry State";
BA_ "Version" SG_ 1030 APSM_AstSeatPosRclnLmt_Sta "23.05.00";
BA_ "NetworkRequestHoldingTime" SG_ 1030 APSM_AstSeatPosRclnLmt_Sta 5000;
BA_ "NetworkRequest" SG_ 1030 APSM_AstSeatPosRclnLmt_Sta 0;
BA_ "UserSigValidity" SG_ 1030 APSM_AstSeatPosRclnLmt_Sta 0;
BA_ "GenSigSendType" SG_ 1030 APSM_AstSeatPosRclnLmt_Sta 4;
BA_ "Description" SG_ 1030 APSM_AstSeatPosRclnLmt_Sta "APSM Recline end Position and limit Initialize State information";
BA_ "Version" SG_ 1030 APSM_AstSeatPosSldLmt_Sta "23.05.00";
BA_ "NetworkRequestHoldingTime" SG_ 1030 APSM_AstSeatPosSldLmt_Sta 5000;
BA_ "NetworkRequest" SG_ 1030 APSM_AstSeatPosSldLmt_Sta 0;
BA_ "UserSigValidity" SG_ 1030 APSM_AstSeatPosSldLmt_Sta 0;
BA_ "GenSigSendType" SG_ 1030 APSM_AstSeatPosSldLmt_Sta 4;
BA_ "Description" SG_ 1030 APSM_AstSeatPosSldLmt_Sta "APSM Slide end Position and limit Initialize State information";
BA_ "Version" SG_ 1031 APSM_RearModeEnable "19.07.06";
BA_ "NetworkRequestHoldingTime" SG_ 1031 APSM_RearModeEnable 5000;
BA_ "NetworkRequest" SG_ 1031 APSM_RearModeEnable 0;
BA_ "UserSigValidity" SG_ 1031 APSM_RearModeEnable 0;
BA_ "GenSigSendType" SG_ 1031 APSM_RearModeEnable 4;
BA_ "Description" SG_ 1031 APSM_RearModeEnable "Rear One Touch Mode Enable/Disable";
BA_ "Version" SG_ 1031 APSM_SeatPosPlyBck_Sta "20.03.00";
BA_ "UserSigValidity" SG_ 1031 APSM_SeatPosPlyBck_Sta 0;
BA_ "GenSigSendType" SG_ 1031 APSM_SeatPosPlyBck_Sta 4;
BA_ "Description" SG_ 1031 APSM_SeatPosPlyBck_Sta "The signal indicates the state of Assistant's seat position playing back.";
BA_ "Version" SG_ 1031 APSM_AstStEsyAcsUSMSta "19.08.08";
BA_ "NetworkRequestHoldingTime" SG_ 1031 APSM_AstStEsyAcsUSMSta 5000;
BA_ "NetworkRequest" SG_ 1031 APSM_AstStEsyAcsUSMSta 0;
BA_ "UserSigValidity" SG_ 1031 APSM_AstStEsyAcsUSMSta 0;
BA_ "GenSigSendType" SG_ 1031 APSM_AstStEsyAcsUSMSta 4;
BA_ "Version" SG_ 1031 APSM_ReturnModeState "20.07.05";
BA_ "NetworkRequestHoldingTime" SG_ 1031 APSM_ReturnModeState 5000;
BA_ "NetworkRequest" SG_ 1031 APSM_ReturnModeState 0;
BA_ "UserSigValidity" SG_ 1031 APSM_ReturnModeState 0;
BA_ "GenSigSendType" SG_ 1031 APSM_ReturnModeState 4;
BA_ "Description" SG_ 1031 APSM_ReturnModeState "APSM move state for Return Mode";
BA_ "Version" SG_ 1031 APSM_RelaxModeState "20.07.05";
BA_ "NetworkRequestHoldingTime" SG_ 1031 APSM_RelaxModeState 5000;
BA_ "NetworkRequest" SG_ 1031 APSM_RelaxModeState 0;
BA_ "UserSigValidity" SG_ 1031 APSM_RelaxModeState 0;
BA_ "GenSigSendType" SG_ 1031 APSM_RelaxModeState 4;
BA_ "Description" SG_ 1031 APSM_RelaxModeState "APSM move state for Relax Mode";
BA_ "Version" SG_ 1031 APSM_WalkInEnable "19.07.06";
BA_ "NetworkRequestHoldingTime" SG_ 1031 APSM_WalkInEnable 5000;
BA_ "NetworkRequest" SG_ 1031 APSM_WalkInEnable 0;
BA_ "UserSigValidity" SG_ 1031 APSM_WalkInEnable 0;
BA_ "GenSigSendType" SG_ 1031 APSM_WalkInEnable 4;
BA_ "Description" SG_ 1031 APSM_WalkInEnable "Apsm Walk In Mode Enable/Disable";
BA_ "Version" SG_ 1031 APSM_LimSetSta "21.04.01";
BA_ "NetworkRequestHoldingTime" SG_ 1031 APSM_LimSetSta 5000;
BA_ "NetworkRequest" SG_ 1031 APSM_LimSetSta 0;
BA_ "UserSigValidity" SG_ 1031 APSM_LimSetSta 0;
BA_ "GenSigSendType" SG_ 1031 APSM_LimSetSta 4;
BA_ "Version" SG_ 1031 APSM_FootRest_Opt "19.11.05";
BA_ "NetworkRequestHoldingTime" SG_ 1031 APSM_FootRest_Opt 5000;
BA_ "NetworkRequest" SG_ 1031 APSM_FootRest_Opt 0;
BA_ "UserSigValidity" SG_ 1031 APSM_FootRest_Opt 0;
BA_ "GenSigSendType" SG_ 1031 APSM_FootRest_Opt 4;
BA_ "Description" SG_ 1031 APSM_FootRest_Opt "Foot Rest OPTION";
BA_ "Version" SG_ 1031 APSM_RSE_Opt "20.07.11";
BA_ "NetworkRequestHoldingTime" SG_ 1031 APSM_RSE_Opt 5000;
BA_ "NetworkRequest" SG_ 1031 APSM_RSE_Opt 0;
BA_ "UserSigValidity" SG_ 1031 APSM_RSE_Opt 0;
BA_ "GenSigSendType" SG_ 1031 APSM_RSE_Opt 4;
BA_ "Description" SG_ 1031 APSM_RSE_Opt "RSE OPTION";
BA_ "Version" SG_ 1048 ICU_Crc8Val "21.09.03";
BA_ "RoutingFactor" SG_ 1048 ICU_Crc8Val 0;
BA_ "UserSigValidity" SG_ 1048 ICU_Crc8Val 0;
BA_ "GenSigSendType" SG_ 1048 ICU_Crc8Val 4;
BA_ "Description" SG_ 1048 ICU_Crc8Val "The data area for CRC calculation is based on the data length (DLC) of the message DB.

The CRC shall be calculated over the entire data block (excluding the CRC bytes) including the user data, alive counter and Data ID 

 

- CRC Polynomial (0x1D) , Ini";
BA_ "Version" SG_ 1048 ICU_AlvCnt8Val "21.09.03";
BA_ "RoutingFactor" SG_ 1048 ICU_AlvCnt8Val 0;
BA_ "UserSigValidity" SG_ 1048 ICU_AlvCnt8Val 0;
BA_ "GenSigSendType" SG_ 1048 ICU_AlvCnt8Val 4;
BA_ "Description" SG_ 1048 ICU_AlvCnt8Val "For the first transmission request for a data element the counter shall be initialized with 0 and shall be incremented by 1

for every subsequent send request. When the counter reaches the maximum value(0xE), then it shall restart with 0 for the next sen";
BA_ "Version" SG_ 1048 DriveTypeOption "21.11.00";
BA_ "RoutingFactor" SG_ 1048 DriveTypeOption 0;
BA_ "NetworkRequestHoldingTime" SG_ 1048 DriveTypeOption 5000;
BA_ "NetworkRequest" SG_ 1048 DriveTypeOption 0;
BA_ "UserSigValidity" SG_ 1048 DriveTypeOption 0;
BA_ "GenSigSendType" SG_ 1048 DriveTypeOption 4;
BA_ "Description" SG_ 1048 DriveTypeOption "Drive Type Option

This signal is used to determine driver's seat position('Drive Type') about this vehicle.";
BA_ "Version" SG_ 1048 Warn_RrLftSBRMATSwSta "21.11.00";
BA_ "RoutingFactor" SG_ 1048 Warn_RrLftSBRMATSwSta 0;
BA_ "NetworkRequestHoldingTime" SG_ 1048 Warn_RrLftSBRMATSwSta 5000;
BA_ "NetworkRequest" SG_ 1048 Warn_RrLftSBRMATSwSta 0;
BA_ "UserSigValidity" SG_ 1048 Warn_RrLftSBRMATSwSta 0;
BA_ "GenSigSendType" SG_ 1048 Warn_RrLftSBRMATSwSta 4;
BA_ "Description" SG_ 1048 Warn_RrLftSBRMATSwSta "Rear Left Seated State";
BA_ "Version" SG_ 1048 Warn_RrRhtSBRMATSwSta "21.11.00";
BA_ "RoutingFactor" SG_ 1048 Warn_RrRhtSBRMATSwSta 0;
BA_ "NetworkRequestHoldingTime" SG_ 1048 Warn_RrRhtSBRMATSwSta 5000;
BA_ "NetworkRequest" SG_ 1048 Warn_RrRhtSBRMATSwSta 0;
BA_ "UserSigValidity" SG_ 1048 Warn_RrRhtSBRMATSwSta 0;
BA_ "GenSigSendType" SG_ 1048 Warn_RrRhtSBRMATSwSta 4;
BA_ "Description" SG_ 1048 Warn_RrRhtSBRMATSwSta "Rear Right Seated State";
BA_ "Version" SG_ 1048 Lamp_FootLampOnReq "17.12.00";
BA_ "RoutingFactor" SG_ 1048 Lamp_FootLampOnReq 0;
BA_ "NetworkRequestHoldingTime" SG_ 1048 Lamp_FootLampOnReq 5000;
BA_ "NetworkRequest" SG_ 1048 Lamp_FootLampOnReq 0;
BA_ "UserSigValidity" SG_ 1048 Lamp_FootLampOnReq 0;
BA_ "GenSigSendType" SG_ 1048 Lamp_FootLampOnReq 4;
BA_ "Description" SG_ 1048 Lamp_FootLampOnReq "Foot Lamp Command";
BA_ "Version" SG_ 1048 Lamp_MoodLampOnReq "21.07.05";
BA_ "RoutingFactor" SG_ 1048 Lamp_MoodLampOnReq 0;
BA_ "NetworkRequestHoldingTime" SG_ 1048 Lamp_MoodLampOnReq 5000;
BA_ "NetworkRequest" SG_ 1048 Lamp_MoodLampOnReq 0;
BA_ "UserSigValidity" SG_ 1048 Lamp_MoodLampOnReq 0;
BA_ "GenSigSendType" SG_ 1048 Lamp_MoodLampOnReq 4;
BA_ "Description" SG_ 1048 Lamp_MoodLampOnReq "Mood lamp command";
BA_ "Version" SG_ 1048 ICU_PowerAutoCutModSta "22.06.05";
BA_ "RoutingFactor" SG_ 1048 ICU_PowerAutoCutModSta 0;
BA_ "UserSigValidity" SG_ 1048 ICU_PowerAutoCutModSta 0;
BA_ "GenSigSendType" SG_ 1048 ICU_PowerAutoCutModSta 4;
BA_ "Description" SG_ 1048 ICU_PowerAutoCutModSta "ICU Delivery Mode State";
BA_ "Version" SG_ 1048 ICU_SoCBattStaMsgReq "17.12.00";
BA_ "RoutingFactor" SG_ 1048 ICU_SoCBattStaMsgReq 0;
BA_ "UserSigValidity" SG_ 1048 ICU_SoCBattStaMsgReq 0;
BA_ "GenSigStartValue" SG_ 1048 ICU_SoCBattStaMsgReq 3;
BA_ "GenSigSendType" SG_ 1048 ICU_SoCBattStaMsgReq 4;
BA_ "Description" SG_ 1048 ICU_SoCBattStaMsgReq "Determine if soc level is warning or alert.";
BA_ "Version" SG_ 1048 C_1stCTRSeatBeltSW "19.04.06";
BA_ "RoutingFactor" SG_ 1048 C_1stCTRSeatBeltSW 0;
BA_ "NetworkRequestHoldingTime" SG_ 1048 C_1stCTRSeatBeltSW 5000;
BA_ "NetworkRequest" SG_ 1048 C_1stCTRSeatBeltSW 0;
BA_ "UserSigValidity" SG_ 1048 C_1stCTRSeatBeltSW 0;
BA_ "GenSigSendType" SG_ 1048 C_1stCTRSeatBeltSW 4;
BA_ "Description" SG_ 1048 C_1stCTRSeatBeltSW "1st Center Seat Belt Switch Status";
BA_ "Version" SG_ 1048 Brake_SwSta_ICU "21.07.05";
BA_ "RoutingFactor" SG_ 1048 Brake_SwSta_ICU 0;
BA_ "NetworkRequestHoldingTime" SG_ 1048 Brake_SwSta_ICU 5000;
BA_ "NetworkRequest" SG_ 1048 Brake_SwSta_ICU 0;
BA_ "UserSigValidity" SG_ 1048 Brake_SwSta_ICU 0;
BA_ "GenSigSendType" SG_ 1048 Brake_SwSta_ICU 4;
BA_ "Description" SG_ 1048 Brake_SwSta_ICU "Brake Switch Status";
BA_ "Version" SG_ 1048 C_1stCTRSBRMatSw "19.04.06";
BA_ "RoutingFactor" SG_ 1048 C_1stCTRSBRMatSw 0;
BA_ "NetworkRequestHoldingTime" SG_ 1048 C_1stCTRSBRMatSw 5000;
BA_ "NetworkRequest" SG_ 1048 C_1stCTRSBRMatSw 0;
BA_ "UserSigValidity" SG_ 1048 C_1stCTRSBRMatSw 0;
BA_ "GenSigSendType" SG_ 1048 C_1stCTRSBRMatSw 4;
BA_ "Description" SG_ 1048 C_1stCTRSBRMatSw "1st Center Seated State



-Default value: 0x0 (¹ÌÅ¾½Â)

-Initial value: 0x0 (¹ÌÅ¾½Â)

-Timeout value: 0x0 (¹ÌÅ¾½Â)";
BA_ "Version" SG_ 1048 C_3rdRCSeatBeltSW "18.03.04";
BA_ "RoutingFactor" SG_ 1048 C_3rdRCSeatBeltSW 0;
BA_ "NetworkRequestHoldingTime" SG_ 1048 C_3rdRCSeatBeltSW 5000;
BA_ "NetworkRequest" SG_ 1048 C_3rdRCSeatBeltSW 0;
BA_ "UserSigValidity" SG_ 1048 C_3rdRCSeatBeltSW 0;
BA_ "GenSigSendType" SG_ 1048 C_3rdRCSeatBeltSW 4;
BA_ "Description" SG_ 1048 C_3rdRCSeatBeltSW "3rd Rear Center Seat Belt Switch Status";
BA_ "Version" SG_ 1048 C_3rdRRSBRMatSw "18.03.04";
BA_ "RoutingFactor" SG_ 1048 C_3rdRRSBRMatSw 0;
BA_ "NetworkRequestHoldingTime" SG_ 1048 C_3rdRRSBRMatSw 5000;
BA_ "NetworkRequest" SG_ 1048 C_3rdRRSBRMatSw 0;
BA_ "UserSigValidity" SG_ 1048 C_3rdRRSBRMatSw 0;
BA_ "GenSigSendType" SG_ 1048 C_3rdRRSBRMatSw 4;
BA_ "Description" SG_ 1048 C_3rdRRSBRMatSw "3rd Rear Right Seated State



-Default value: 0x0 (¹ÌÅ¾½Â)

-Initial value: 0x0 (¹ÌÅ¾½Â)

-Timeout value: 0x0 (¹ÌÅ¾½Â)";
BA_ "Version" SG_ 1048 C_3rdRLSBRMatSw "18.03.04";
BA_ "RoutingFactor" SG_ 1048 C_3rdRLSBRMatSw 0;
BA_ "NetworkRequestHoldingTime" SG_ 1048 C_3rdRLSBRMatSw 5000;
BA_ "NetworkRequest" SG_ 1048 C_3rdRLSBRMatSw 0;
BA_ "UserSigValidity" SG_ 1048 C_3rdRLSBRMatSw 0;
BA_ "GenSigSendType" SG_ 1048 C_3rdRLSBRMatSw 4;
BA_ "Description" SG_ 1048 C_3rdRLSBRMatSw "3rd Rear Left Seated State



-Default value: 0x0 (¹ÌÅ¾½Â)

-Initial value: 0x0 (¹ÌÅ¾½Â)

-Timeout value: 0x0 (¹ÌÅ¾½Â)";
BA_ "Version" SG_ 1048 C_3rdRRSeatBeltSW "18.03.04";
BA_ "RoutingFactor" SG_ 1048 C_3rdRRSeatBeltSW 0;
BA_ "NetworkRequestHoldingTime" SG_ 1048 C_3rdRRSeatBeltSW 5000;
BA_ "NetworkRequest" SG_ 1048 C_3rdRRSeatBeltSW 0;
BA_ "UserSigValidity" SG_ 1048 C_3rdRRSeatBeltSW 0;
BA_ "GenSigSendType" SG_ 1048 C_3rdRRSeatBeltSW 4;
BA_ "Description" SG_ 1048 C_3rdRRSeatBeltSW "3rd Rear Right Seat Belt Switch Status";
BA_ "Version" SG_ 1048 C_3rdRLSeatBeltSW "18.03.04";
BA_ "RoutingFactor" SG_ 1048 C_3rdRLSeatBeltSW 0;
BA_ "NetworkRequestHoldingTime" SG_ 1048 C_3rdRLSeatBeltSW 5000;
BA_ "NetworkRequest" SG_ 1048 C_3rdRLSeatBeltSW 0;
BA_ "UserSigValidity" SG_ 1048 C_3rdRLSeatBeltSW 0;
BA_ "GenSigSendType" SG_ 1048 C_3rdRLSeatBeltSW 4;
BA_ "Description" SG_ 1048 C_3rdRLSeatBeltSW "3rd Rear Left Seat Belt Switch Status";
BA_ "Version" SG_ 1048 HSWS_SysWrngSta_ICU "21.11.00";
BA_ "RoutingFactor" SG_ 1048 HSWS_SysWrngSta_ICU 0;
BA_ "UserSigValidity" SG_ 1048 HSWS_SysWrngSta_ICU 4;
BA_ "GenSigSendType" SG_ 1048 HSWS_SysWrngSta_ICU 4;
BA_ "Description" SG_ 1048 HSWS_SysWrngSta_ICU "0x0 : Normal

0x1 : System Fail

0x2 : Reserved

0x3 : Invalid";
BA_ "Version" SG_ 1050 BCM_Crc7Val "21.09.03";
BA_ "UserSigValidity" SG_ 1050 BCM_Crc7Val 0;
BA_ "GenSigSendType" SG_ 1050 BCM_Crc7Val 4;
BA_ "Description" SG_ 1050 BCM_Crc7Val "The data area for CRC calculation is based on the data length (DLC) of the message DB.

The CRC shall be calculated over the entire data block (excluding the CRC bytes) including the user data, alive counter and Data ID 

 

- CRC Polynomial (0x1D) , Ini";
BA_ "Version" SG_ 1050 BCM_AlvCnt7Val "21.09.03";
BA_ "UserSigValidity" SG_ 1050 BCM_AlvCnt7Val 0;
BA_ "GenSigSendType" SG_ 1050 BCM_AlvCnt7Val 4;
BA_ "Description" SG_ 1050 BCM_AlvCnt7Val "For the first transmission request for a data element the counter shall be initialized with 0 and shall be incremented by 1

for every subsequent send request. When the counter reaches the maximum value(0xE), then it shall restart with 0 for the next sen";
BA_ "Version" SG_ 1050 Lamp_HiPrioHzrdReq "17.12.00";
BA_ "NetworkRequestHoldingTime" SG_ 1050 Lamp_HiPrioHzrdReq 5000;
BA_ "NetworkRequest" SG_ 1050 Lamp_HiPrioHzrdReq 0;
BA_ "UserSigValidity" SG_ 1050 Lamp_HiPrioHzrdReq 0;
BA_ "GenSigStartValue" SG_ 1050 Lamp_HiPrioHzrdReq 2;
BA_ "GenSigSendType" SG_ 1050 Lamp_HiPrioHzrdReq 4;
BA_ "Description" SG_ 1050 Lamp_HiPrioHzrdReq "-Higher priority than SJB hazard

-Diag/Arm/DisArm/Balarm/Panic/MTS

-Initial Value: 2";
BA_ "Version" SG_ 1050 Lamp_LoPrioHzrdReq "17.12.00";
BA_ "NetworkRequestHoldingTime" SG_ 1050 Lamp_LoPrioHzrdReq 5000;
BA_ "NetworkRequest" SG_ 1050 Lamp_LoPrioHzrdReq 0;
BA_ "UserSigValidity" SG_ 1050 Lamp_LoPrioHzrdReq 0;
BA_ "GenSigStartValue" SG_ 1050 Lamp_LoPrioHzrdReq 2;
BA_ "GenSigSendType" SG_ 1050 Lamp_LoPrioHzrdReq 4;
BA_ "Description" SG_ 1050 Lamp_LoPrioHzrdReq "-Lower priority than SJB hazard

-TrunkOpenClose/CrashUnlock/RemoteStart

-Initial Value: 2";
BA_ "Version" SG_ 1050 Lamp_IntTailLmpOnReq "17.12.00";
BA_ "NetworkRequestHoldingTime" SG_ 1050 Lamp_IntTailLmpOnReq 5000;
BA_ "NetworkRequest" SG_ 1050 Lamp_IntTailLmpOnReq 0;
BA_ "UserSigValidity" SG_ 1050 Lamp_IntTailLmpOnReq 0;
BA_ "GenSigSendType" SG_ 1050 Lamp_IntTailLmpOnReq 4;
BA_ "Description" SG_ 1050 Lamp_IntTailLmpOnReq "-(Old)C_INTTailOn";
BA_ "Version" SG_ 1050 Lamp_ExtrnlTailLmpOnReq "17.12.00";
BA_ "NetworkRequestHoldingTime" SG_ 1050 Lamp_ExtrnlTailLmpOnReq 5000;
BA_ "NetworkRequest" SG_ 1050 Lamp_ExtrnlTailLmpOnReq 0;
BA_ "UserSigValidity" SG_ 1050 Lamp_ExtrnlTailLmpOnReq 0;
BA_ "GenSigSendType" SG_ 1050 Lamp_ExtrnlTailLmpOnReq 4;
BA_ "Description" SG_ 1050 Lamp_ExtrnlTailLmpOnReq "-(Old)C_EXTTailOn";
BA_ "Version" SG_ 1050 Lamp_HdLmpLoOnReq "17.12.00";
BA_ "NetworkRequestHoldingTime" SG_ 1050 Lamp_HdLmpLoOnReq 5000;
BA_ "NetworkRequest" SG_ 1050 Lamp_HdLmpLoOnReq 0;
BA_ "UserSigValidity" SG_ 1050 Lamp_HdLmpLoOnReq 0;
BA_ "GenSigSendType" SG_ 1050 Lamp_HdLmpLoOnReq 4;
BA_ "Description" SG_ 1050 Lamp_HdLmpLoOnReq "-(Old)C_HLampLowON";
BA_ "Version" SG_ 1050 Lamp_HdLmpHiOnReq "17.12.00";
BA_ "NetworkRequestHoldingTime" SG_ 1050 Lamp_HdLmpHiOnReq 5000;
BA_ "NetworkRequest" SG_ 1050 Lamp_HdLmpHiOnReq 0;
BA_ "UserSigValidity" SG_ 1050 Lamp_HdLmpHiOnReq 0;
BA_ "GenSigSendType" SG_ 1050 Lamp_HdLmpHiOnReq 4;
BA_ "Description" SG_ 1050 Lamp_HdLmpHiOnReq "-(Old)C_HLampHighON";
BA_ "Version" SG_ 1050 Lamp_AvTailLmpSta "21.09.05";
BA_ "NetworkRequestHoldingTime" SG_ 1050 Lamp_AvTailLmpSta 5000;
BA_ "NetworkRequest" SG_ 1050 Lamp_AvTailLmpSta 0;
BA_ "UserSigValidity" SG_ 1050 Lamp_AvTailLmpSta 0;
BA_ "GenSigStartValue" SG_ 1050 Lamp_AvTailLmpSta 1;
BA_ "GenSigSendType" SG_ 1050 Lamp_AvTailLmpSta 4;
BA_ "Description" SG_ 1050 Lamp_AvTailLmpSta "-Send with at the same time with C_IntTailOn

-Initiail Value: 1";
BA_ "Version" SG_ 1050 Lamp_BckUpLmpCmd "20.08.02";
BA_ "NetworkRequestHoldingTime" SG_ 1050 Lamp_BckUpLmpCmd 5000;
BA_ "NetworkRequest" SG_ 1050 Lamp_BckUpLmpCmd 0;
BA_ "UserSigValidity" SG_ 1050 Lamp_BckUpLmpCmd 0;
BA_ "GenSigSendType" SG_ 1050 Lamp_BckUpLmpCmd 4;
BA_ "Description" SG_ 1050 Lamp_BckUpLmpCmd "BackUp Lamp On/Off Command";
BA_ "Version" SG_ 1050 Lamp_DrlOnReq "20.09.00";
BA_ "NetworkRequestHoldingTime" SG_ 1050 Lamp_DrlOnReq 5000;
BA_ "NetworkRequest" SG_ 1050 Lamp_DrlOnReq 0;
BA_ "UserSigValidity" SG_ 1050 Lamp_DrlOnReq 0;
BA_ "GenSigSendType" SG_ 1050 Lamp_DrlOnReq 4;
BA_ "Description" SG_ 1050 Lamp_DrlOnReq "Lamp on command for DRL";
BA_ "Version" SG_ 1050 USM_IllAlwaysOnwithPSTNSta "22.06.00";
BA_ "NetworkRequestHoldingTime" SG_ 1050 USM_IllAlwaysOnwithPSTNSta 5000;
BA_ "NetworkRequest" SG_ 1050 USM_IllAlwaysOnwithPSTNSta 0;
BA_ "UserSigValidity" SG_ 1050 USM_IllAlwaysOnwithPSTNSta 0;
BA_ "GenSigSendType" SG_ 1050 USM_IllAlwaysOnwithPSTNSta 4;
BA_ "Description" SG_ 1050 USM_IllAlwaysOnwithPSTNSta "Current setting value for IntTailOn with DRL/PSTN";
BA_ "Version" SG_ 1052 BCM_Crc9Val "21.09.03";
BA_ "UserSigValidity" SG_ 1052 BCM_Crc9Val 0;
BA_ "GenSigSendType" SG_ 1052 BCM_Crc9Val 4;
BA_ "Description" SG_ 1052 BCM_Crc9Val "The data area for CRC calculation is based on the data length (DLC) of the message DB.

The CRC shall be calculated over the entire data block (excluding the CRC bytes) including the user data, alive counter and Data ID 

 

- CRC Polynomial (0x1D) , Ini";
BA_ "Version" SG_ 1052 BCM_AlvCnt9Val "21.09.03";
BA_ "UserSigValidity" SG_ 1052 BCM_AlvCnt9Val 0;
BA_ "GenSigSendType" SG_ 1052 BCM_AlvCnt9Val 4;
BA_ "Description" SG_ 1052 BCM_AlvCnt9Val "For the first transmission request for a data element the counter shall be initialized with 0 and shall be incremented by 1

for every subsequent send request. When the counter reaches the maximum value(0xE), then it shall restart with 0 for the next sen";
BA_ "Version" SG_ 1052 Lamp_AutoLtSnsrNightSta "20.04.06";
BA_ "NetworkRequestHoldingTime" SG_ 1052 Lamp_AutoLtSnsrNightSta 5000;
BA_ "NetworkRequest" SG_ 1052 Lamp_AutoLtSnsrNightSta 0;
BA_ "UserSigValidity" SG_ 1052 Lamp_AutoLtSnsrNightSta 0;
BA_ "GenSigStartValue" SG_ 1052 Lamp_AutoLtSnsrNightSta 1;
BA_ "GenSigSendType" SG_ 1052 Lamp_AutoLtSnsrNightSta 4;
BA_ "Description" SG_ 1052 Lamp_AutoLtSnsrNightSta "This signal indicates autolight sensor output";
BA_ "Version" SG_ 1052 Lamp_VendorInfo "20.05.03";
BA_ "NetworkRequestHoldingTime" SG_ 1052 Lamp_VendorInfo 5000;
BA_ "NetworkRequest" SG_ 1052 Lamp_VendorInfo 0;
BA_ "UserSigValidity" SG_ 1052 Lamp_VendorInfo 0;
BA_ "GenSigStartValue" SG_ 1052 Lamp_VendorInfo 7;
BA_ "GenSigSendType" SG_ 1052 Lamp_VendorInfo 4;
BA_ "Description" SG_ 1052 Lamp_VendorInfo "Rain seosor Vendor info (LIN to CAN signal)

- 001 : TRW(BCS)

- 010 : HELLA";
BA_ "Version" SG_ 1052 Lamp_AutoLtSnsrHorVal "21.12.00";
BA_ "NetworkRequestHoldingTime" SG_ 1052 Lamp_AutoLtSnsrHorVal 5000;
BA_ "NetworkRequest" SG_ 1052 Lamp_AutoLtSnsrHorVal 0;
BA_ "UserSigValidity" SG_ 1052 Lamp_AutoLtSnsrHorVal 0;
BA_ "GenSigSendType" SG_ 1052 Lamp_AutoLtSnsrHorVal 4;
BA_ "Description" SG_ 1052 Lamp_AutoLtSnsrHorVal "This signal indicates autolight sensor output (for HUD)

<BCS>

0x0~0x3FE : Light Sensor Value

0x3FF : Invalid

<HELLA>

0x0~0xFE, 100~0x3FE : Light Sensor Value

0xFF, 0x3FF : Invalid";
BA_ "Version" SG_ 1052 IBU_HDPSpprtSWVer "21.10.04";
BA_ "NetworkRequestHoldingTime" SG_ 1052 IBU_HDPSpprtSWVer 5000;
BA_ "NetworkRequest" SG_ 1052 IBU_HDPSpprtSWVer 0;
BA_ "UserSigValidity" SG_ 1052 IBU_HDPSpprtSWVer 0;
BA_ "GenSigSendType" SG_ 1052 IBU_HDPSpprtSWVer 4;
BA_ "Description" SG_ 1052 IBU_HDPSpprtSWVer "This signal indicates HDP-IBU requirement version";
BA_ "Version" SG_ 1052 IBU_HDPSpprtRdy "22.03.02";
BA_ "NetworkRequestHoldingTime" SG_ 1052 IBU_HDPSpprtRdy 5000;
BA_ "NetworkRequest" SG_ 1052 IBU_HDPSpprtRdy 0;
BA_ "UserSigValidity" SG_ 1052 IBU_HDPSpprtRdy 0;
BA_ "GenSigSendType" SG_ 1052 IBU_HDPSpprtRdy 4;
BA_ "Description" SG_ 1052 IBU_HDPSpprtRdy "ADAS Message (received) Error State";
BA_ "Version" SG_ 1052 Wiper_RainAmount "23.02.01";
BA_ "NetworkRequestHoldingTime" SG_ 1052 Wiper_RainAmount 5000;
BA_ "NetworkRequest" SG_ 1052 Wiper_RainAmount 0;
BA_ "UserSigValidity" SG_ 1052 Wiper_RainAmount 0;
BA_ "GenSigStartValue" SG_ 1052 Wiper_RainAmount 255;
BA_ "GenSigSendType" SG_ 1052 Wiper_RainAmount 4;
BA_ "Description" SG_ 1052 Wiper_RainAmount "Amount of rain on windshield (LIN to CAN Signal)

- LIN Signal Name : VAL_RAIN_AMOUNT

- 0~150 : PH=0.1*HEX(mm/Hr)

- 151~254 : Reserved

- 255 (1111 1111) : Invalid 



RainSnsrPartNum CU000's Factor is 0.5

- 0~150 : PH=0.5*HEX(%)

- 151~254 : Reserved";
BA_ "Version" SG_ 1041 ICU_Crc2Val "21.09.03";
BA_ "RoutingFactor" SG_ 1041 ICU_Crc2Val 0;
BA_ "UserSigValidity" SG_ 1041 ICU_Crc2Val 0;
BA_ "GenSigSendType" SG_ 1041 ICU_Crc2Val 4;
BA_ "Description" SG_ 1041 ICU_Crc2Val "The data area for CRC calculation is based on the data length (DLC) of the message DB.

The CRC shall be calculated over the entire data block (excluding the CRC bytes) including the user data, alive counter and Data ID 

 

- CRC Polynomial (0x1D) , Ini";
BA_ "Version" SG_ 1041 ICU_MtGearPosRSta "21.07.05";
BA_ "RoutingFactor" SG_ 1041 ICU_MtGearPosRSta 0;
BA_ "UserSigValidity" SG_ 1041 ICU_MtGearPosRSta 3;
BA_ "GenSigSendType" SG_ 1041 ICU_MtGearPosRSta 4;
BA_ "Description" SG_ 1041 ICU_MtGearPosRSta "Manual Shift Lever R Switch Status 0x0:Off/0x1:On";
BA_ "Version" SG_ 1041 ICU_AlvCnt2Val "21.09.03";
BA_ "RoutingFactor" SG_ 1041 ICU_AlvCnt2Val 0;
BA_ "UserSigValidity" SG_ 1041 ICU_AlvCnt2Val 0;
BA_ "GenSigSendType" SG_ 1041 ICU_AlvCnt2Val 4;
BA_ "Description" SG_ 1041 ICU_AlvCnt2Val "For the first transmission request for a data element the counter shall be initialized with 0 and shall be incremented by 1

for every subsequent send request. When the counter reaches the maximum value(0xE), then it shall restart with 0 for the next sen";
BA_ "Version" SG_ 1041 Autocut_DlvryModSta "17.12.00";
BA_ "RoutingFactor" SG_ 1041 Autocut_DlvryModSta 0;
BA_ "NetworkRequestHoldingTime" SG_ 1041 Autocut_DlvryModSta 5000;
BA_ "NetworkRequest" SG_ 1041 Autocut_DlvryModSta 0;
BA_ "UserSigValidity" SG_ 1041 Autocut_DlvryModSta 0;
BA_ "GenSigStartValue" SG_ 1041 Autocut_DlvryModSta 1;
BA_ "GenSigSendType" SG_ 1041 Autocut_DlvryModSta 4;
BA_ "Description" SG_ 1041 Autocut_DlvryModSta "-(Old)C_SJB_DeliveryMode

-Initial value: 1";
BA_ "Version" SG_ 1041 DoorLock_AsstDrUnLkSta "17.12.00";
BA_ "RoutingFactor" SG_ 1041 DoorLock_AsstDrUnLkSta 0;
BA_ "NetworkRequestHoldingTime" SG_ 1041 DoorLock_AsstDrUnLkSta 5000;
BA_ "NetworkRequest" SG_ 1041 DoorLock_AsstDrUnLkSta 0;
BA_ "UserSigValidity" SG_ 1041 DoorLock_AsstDrUnLkSta 0;
BA_ "GenSigSendType" SG_ 1041 DoorLock_AsstDrUnLkSta 4;
BA_ "Version" SG_ 1041 Warn_DrvDrSwSta "17.12.00";
BA_ "RoutingFactor" SG_ 1041 Warn_DrvDrSwSta 0;
BA_ "NetworkRequestHoldingTime" SG_ 1041 Warn_DrvDrSwSta 5000;
BA_ "NetworkRequest" SG_ 1041 Warn_DrvDrSwSta 0;
BA_ "UserSigValidity" SG_ 1041 Warn_DrvDrSwSta 0;
BA_ "GenSigSendType" SG_ 1041 Warn_DrvDrSwSta 4;
BA_ "Version" SG_ 1041 DoorLock_DrvKeyUnLkSwSta "17.12.00";
BA_ "RoutingFactor" SG_ 1041 DoorLock_DrvKeyUnLkSwSta 0;
BA_ "NetworkRequestHoldingTime" SG_ 1041 DoorLock_DrvKeyUnLkSwSta 5000;
BA_ "NetworkRequest" SG_ 1041 DoorLock_DrvKeyUnLkSwSta 0;
BA_ "UserSigValidity" SG_ 1041 DoorLock_DrvKeyUnLkSwSta 0;
BA_ "GenSigSendType" SG_ 1041 DoorLock_DrvKeyUnLkSwSta 4;
BA_ "Version" SG_ 1041 DoorLock_RrLftDrUnLkSta "17.12.00";
BA_ "RoutingFactor" SG_ 1041 DoorLock_RrLftDrUnLkSta 0;
BA_ "NetworkRequestHoldingTime" SG_ 1041 DoorLock_RrLftDrUnLkSta 5000;
BA_ "NetworkRequest" SG_ 1041 DoorLock_RrLftDrUnLkSta 0;
BA_ "UserSigValidity" SG_ 1041 DoorLock_RrLftDrUnLkSta 0;
BA_ "GenSigSendType" SG_ 1041 DoorLock_RrLftDrUnLkSta 4;
BA_ "Version" SG_ 1041 DoorLock_RrRtDrUnLkSta "17.12.00";
BA_ "RoutingFactor" SG_ 1041 DoorLock_RrRtDrUnLkSta 0;
BA_ "NetworkRequestHoldingTime" SG_ 1041 DoorLock_RrRtDrUnLkSta 5000;
BA_ "NetworkRequest" SG_ 1041 DoorLock_RrRtDrUnLkSta 0;
BA_ "UserSigValidity" SG_ 1041 DoorLock_RrRtDrUnLkSta 0;
BA_ "GenSigSendType" SG_ 1041 DoorLock_RrRtDrUnLkSta 4;
BA_ "Version" SG_ 1041 Warn_AsstDrSwSta "17.12.00";
BA_ "RoutingFactor" SG_ 1041 Warn_AsstDrSwSta 0;
BA_ "NetworkRequestHoldingTime" SG_ 1041 Warn_AsstDrSwSta 5000;
BA_ "NetworkRequest" SG_ 1041 Warn_AsstDrSwSta 0;
BA_ "UserSigValidity" SG_ 1041 Warn_AsstDrSwSta 0;
BA_ "GenSigSendType" SG_ 1041 Warn_AsstDrSwSta 4;
BA_ "Version" SG_ 1041 Warn_AsstStBltSwSta "17.12.00";
BA_ "RoutingFactor" SG_ 1041 Warn_AsstStBltSwSta 0;
BA_ "NetworkRequestHoldingTime" SG_ 1041 Warn_AsstStBltSwSta 5000;
BA_ "NetworkRequest" SG_ 1041 Warn_AsstStBltSwSta 0;
BA_ "UserSigValidity" SG_ 1041 Warn_AsstStBltSwSta 0;
BA_ "GenSigStartValue" SG_ 1041 Warn_AsstStBltSwSta 1;
BA_ "GenSigSendType" SG_ 1041 Warn_AsstStBltSwSta 4;
BA_ "Description" SG_ 1041 Warn_AsstStBltSwSta "-Default value: 0x1 (Belt)



-Initial value: 0x1 (Belt)



-Timeout value: 0x1 (Belt)";
BA_ "Version" SG_ 1041 Warn_BrkFldSwSta "17.12.00";
BA_ "RoutingFactor" SG_ 1041 Warn_BrkFldSwSta 0;
BA_ "NetworkRequestHoldingTime" SG_ 1041 Warn_BrkFldSwSta 5000;
BA_ "NetworkRequest" SG_ 1041 Warn_BrkFldSwSta 0;
BA_ "UserSigValidity" SG_ 1041 Warn_BrkFldSwSta 0;
BA_ "GenSigSendType" SG_ 1041 Warn_BrkFldSwSta 4;
BA_ "Version" SG_ 1041 DoorLock_DrvKeyLkSwSta "17.12.00";
BA_ "RoutingFactor" SG_ 1041 DoorLock_DrvKeyLkSwSta 0;
BA_ "NetworkRequestHoldingTime" SG_ 1041 DoorLock_DrvKeyLkSwSta 5000;
BA_ "NetworkRequest" SG_ 1041 DoorLock_DrvKeyLkSwSta 0;
BA_ "UserSigValidity" SG_ 1041 DoorLock_DrvKeyLkSwSta 0;
BA_ "GenSigSendType" SG_ 1041 DoorLock_DrvKeyLkSwSta 4;
BA_ "Version" SG_ 1041 Warn_DrvStBltSwSta "17.12.00";
BA_ "RoutingFactor" SG_ 1041 Warn_DrvStBltSwSta 0;
BA_ "NetworkRequestHoldingTime" SG_ 1041 Warn_DrvStBltSwSta 5000;
BA_ "NetworkRequest" SG_ 1041 Warn_DrvStBltSwSta 0;
BA_ "UserSigValidity" SG_ 1041 Warn_DrvStBltSwSta 0;
BA_ "GenSigSendType" SG_ 1041 Warn_DrvStBltSwSta 4;
BA_ "Version" SG_ 1041 Warn_HoodSwSta "17.12.00";
BA_ "RoutingFactor" SG_ 1041 Warn_HoodSwSta 0;
BA_ "NetworkRequestHoldingTime" SG_ 1041 Warn_HoodSwSta 5000;
BA_ "NetworkRequest" SG_ 1041 Warn_HoodSwSta 0;
BA_ "UserSigValidity" SG_ 1041 Warn_HoodSwSta 0;
BA_ "GenSigSendType" SG_ 1041 Warn_HoodSwSta 4;
BA_ "Version" SG_ 1041 Warn_PassStOccSta "17.12.00";
BA_ "RoutingFactor" SG_ 1041 Warn_PassStOccSta 0;
BA_ "NetworkRequestHoldingTime" SG_ 1041 Warn_PassStOccSta 5000;
BA_ "NetworkRequest" SG_ 1041 Warn_PassStOccSta 0;
BA_ "UserSigValidity" SG_ 1041 Warn_PassStOccSta 0;
BA_ "GenSigSendType" SG_ 1041 Warn_PassStOccSta 4;
BA_ "Description" SG_ 1041 Warn_PassStOccSta "Passenger Seated State







-Default value: 0x0 (¹ÌÅ¾½Â)



-Initial value: 0x0 (¹ÌÅ¾½Â)



-Timeout value: 0x0 (¹ÌÅ¾½Â)";
BA_ "Version" SG_ 1041 Warn_PrkngBrkSwSta "17.12.00";
BA_ "RoutingFactor" SG_ 1041 Warn_PrkngBrkSwSta 0;
BA_ "NetworkRequestHoldingTime" SG_ 1041 Warn_PrkngBrkSwSta 5000;
BA_ "NetworkRequest" SG_ 1041 Warn_PrkngBrkSwSta 0;
BA_ "UserSigValidity" SG_ 1041 Warn_PrkngBrkSwSta 0;
BA_ "GenSigSendType" SG_ 1041 Warn_PrkngBrkSwSta 4;
BA_ "Version" SG_ 1041 Warn_RrCtrStBltSwSta "17.12.00";
BA_ "RoutingFactor" SG_ 1041 Warn_RrCtrStBltSwSta 0;
BA_ "NetworkRequestHoldingTime" SG_ 1041 Warn_RrCtrStBltSwSta 5000;
BA_ "NetworkRequest" SG_ 1041 Warn_RrCtrStBltSwSta 0;
BA_ "UserSigValidity" SG_ 1041 Warn_RrCtrStBltSwSta 0;
BA_ "GenSigSendType" SG_ 1041 Warn_RrCtrStBltSwSta 4;
BA_ "Version" SG_ 1041 Warn_RrLftDrSwSta "17.12.00";
BA_ "RoutingFactor" SG_ 1041 Warn_RrLftDrSwSta 0;
BA_ "NetworkRequestHoldingTime" SG_ 1041 Warn_RrLftDrSwSta 5000;
BA_ "NetworkRequest" SG_ 1041 Warn_RrLftDrSwSta 0;
BA_ "UserSigValidity" SG_ 1041 Warn_RrLftDrSwSta 0;
BA_ "GenSigSendType" SG_ 1041 Warn_RrLftDrSwSta 4;
BA_ "Version" SG_ 1041 Warn_RrLftStBltSwSta "17.12.00";
BA_ "RoutingFactor" SG_ 1041 Warn_RrLftStBltSwSta 0;
BA_ "NetworkRequestHoldingTime" SG_ 1041 Warn_RrLftStBltSwSta 5000;
BA_ "NetworkRequest" SG_ 1041 Warn_RrLftStBltSwSta 0;
BA_ "UserSigValidity" SG_ 1041 Warn_RrLftStBltSwSta 0;
BA_ "GenSigSendType" SG_ 1041 Warn_RrLftStBltSwSta 4;
BA_ "Version" SG_ 1041 Warn_RrRtDrSwSta "17.12.00";
BA_ "RoutingFactor" SG_ 1041 Warn_RrRtDrSwSta 0;
BA_ "NetworkRequestHoldingTime" SG_ 1041 Warn_RrRtDrSwSta 5000;
BA_ "NetworkRequest" SG_ 1041 Warn_RrRtDrSwSta 0;
BA_ "UserSigValidity" SG_ 1041 Warn_RrRtDrSwSta 0;
BA_ "GenSigSendType" SG_ 1041 Warn_RrRtDrSwSta 4;
BA_ "Version" SG_ 1041 Warn_RrRtStBltSwSta "17.12.00";
BA_ "RoutingFactor" SG_ 1041 Warn_RrRtStBltSwSta 0;
BA_ "NetworkRequestHoldingTime" SG_ 1041 Warn_RrRtStBltSwSta 5000;
BA_ "NetworkRequest" SG_ 1041 Warn_RrRtStBltSwSta 0;
BA_ "UserSigValidity" SG_ 1041 Warn_RrRtStBltSwSta 0;
BA_ "GenSigSendType" SG_ 1041 Warn_RrRtStBltSwSta 4;
BA_ "Version" SG_ 1041 Warn_HoodSwMemorySta "21.11.00";
BA_ "RoutingFactor" SG_ 1041 Warn_HoodSwMemorySta 0;
BA_ "NetworkRequestHoldingTime" SG_ 1041 Warn_HoodSwMemorySta 5000;
BA_ "NetworkRequest" SG_ 1041 Warn_HoodSwMemorySta 0;
BA_ "UserSigValidity" SG_ 1041 Warn_HoodSwMemorySta 3;
BA_ "GenSigSendType" SG_ 1041 Warn_HoodSwMemorySta 4;
BA_ "Description" SG_ 1041 Warn_HoodSwMemorySta "Hood swtich open->close information(memory)



This signal is for oil level warning lamp reset In case hood open->close when IG-OFF, 0x01 sent for 5 sec at next IG-ON";
BA_ "Version" SG_ 1041 Warn_WshrFldSwSta "21.07.05";
BA_ "RoutingFactor" SG_ 1041 Warn_WshrFldSwSta 0;
BA_ "NetworkRequestHoldingTime" SG_ 1041 Warn_WshrFldSwSta 5000;
BA_ "NetworkRequest" SG_ 1041 Warn_WshrFldSwSta 0;
BA_ "UserSigValidity" SG_ 1041 Warn_WshrFldSwSta 3;
BA_ "GenSigSendType" SG_ 1041 Warn_WshrFldSwSta 4;
BA_ "Description" SG_ 1041 Warn_WshrFldSwSta "Washer Fluid Switch Signal

This signal indicates Washer Fluid Switch Signal

0x0:Off/0x1:On";
BA_ "Version" SG_ 1041 ICU_Haptic_OPT "18.07.07";
BA_ "RoutingFactor" SG_ 1041 ICU_Haptic_OPT 0;
BA_ "NetworkRequestHoldingTime" SG_ 1041 ICU_Haptic_OPT 5000;
BA_ "NetworkRequest" SG_ 1041 ICU_Haptic_OPT 0;
BA_ "UserSigValidity" SG_ 1041 ICU_Haptic_OPT 0;
BA_ "GenSigSendType" SG_ 1041 ICU_Haptic_OPT 4;
BA_ "Description" SG_ 1041 ICU_Haptic_OPT "Steering Wheel Haptic Warning Option Infomation (From ICU)";
BA_ "Version" SG_ 1040 ICU_Crc10Val "21.09.03";
BA_ "RoutingFactor" SG_ 1040 ICU_Crc10Val 0;
BA_ "UserSigValidity" SG_ 1040 ICU_Crc10Val 0;
BA_ "GenSigSendType" SG_ 1040 ICU_Crc10Val 4;
BA_ "Description" SG_ 1040 ICU_Crc10Val "The data area for CRC calculation is based on the data length (DLC) of the message DB.

The CRC shall be calculated over the entire data block (excluding the CRC bytes) including the user data, alive counter and Data ID 

 

- CRC Polynomial (0x1D) , Ini";
BA_ "Version" SG_ 1040 BmsFailWarning "21.03.11";
BA_ "RoutingFactor" SG_ 1040 BmsFailWarning 0;
BA_ "UserSigValidity" SG_ 1040 BmsFailWarning 0;
BA_ "GenSigSendType" SG_ 1040 BmsFailWarning 4;
BA_ "Description" SG_ 1040 BmsFailWarning "If a 12V lithium battery fails, it is a signal that is sent according to the type of fault";
BA_ "Version" SG_ 1040 ICU_AlvCnt10Val "21.09.03";
BA_ "RoutingFactor" SG_ 1040 ICU_AlvCnt10Val 0;
BA_ "UserSigValidity" SG_ 1040 ICU_AlvCnt10Val 0;
BA_ "GenSigSendType" SG_ 1040 ICU_AlvCnt10Val 4;
BA_ "Description" SG_ 1040 ICU_AlvCnt10Val "For the first transmission request for a data element the counter shall be initialized with 0 and shall be incremented by 1

for every subsequent send request. When the counter reaches the maximum value(0xE), then it shall restart with 0 for the next sen";
BA_ "Version" SG_ 1040 ICU_BS2SoC "21.09.05";
BA_ "RoutingFactor" SG_ 1040 ICU_BS2SoC 0;
BA_ "UserSigValidity" SG_ 1040 ICU_BS2SoC 3;
BA_ "GenSigStartValue" SG_ 1040 ICU_BS2SoC 255;
BA_ "GenSigSendType" SG_ 1040 ICU_BS2SoC 4;
BA_ "Description" SG_ 1040 ICU_BS2SoC "This signal is battery State of Charge as calculated by battery sensor.";
BA_ "Version" SG_ 1040 ICU_BS2NCap "21.07.05";
BA_ "RoutingFactor" SG_ 1040 ICU_BS2NCap 0;
BA_ "UserSigValidity" SG_ 1040 ICU_BS2NCap 3;
BA_ "GenSigStartValue" SG_ 1040 ICU_BS2NCap 255;
BA_ "GenSigSendType" SG_ 1040 ICU_BS2NCap 4;
BA_ "Description" SG_ 1040 ICU_BS2NCap "Nominal capacity";
BA_ "Version" SG_ 1040 ICU_BS2OpnCirVol "21.07.05";
BA_ "RoutingFactor" SG_ 1040 ICU_BS2OpnCirVol 0;
BA_ "UserSigValidity" SG_ 1040 ICU_BS2OpnCirVol 3;
BA_ "GenSigStartValue" SG_ 1040 ICU_BS2OpnCirVol 4095;
BA_ "GenSigSendType" SG_ 1040 ICU_BS2OpnCirVol 4;
BA_ "Description" SG_ 1040 ICU_BS2OpnCirVol "Last open circuit voltage";
BA_ "Version" SG_ 1040 ICU_BS2_FSOC "18.08.03";
BA_ "RoutingFactor" SG_ 1040 ICU_BS2_FSOC 0;
BA_ "UserSigValidity" SG_ 1040 ICU_BS2_FSOC 3;
BA_ "GenSigStartValue" SG_ 1040 ICU_BS2_FSOC 1;
BA_ "GenSigSendType" SG_ 1040 ICU_BS2_FSOC 4;
BA_ "Description" SG_ 1040 ICU_BS2_FSOC "This signal indicates whether the state of SOC signal is fault or not";
BA_ "Version" SG_ 1040 ICU_BS2_FSOH "18.08.03";
BA_ "RoutingFactor" SG_ 1040 ICU_BS2_FSOH 0;
BA_ "UserSigValidity" SG_ 1040 ICU_BS2_FSOH 3;
BA_ "GenSigStartValue" SG_ 1040 ICU_BS2_FSOH 1;
BA_ "GenSigSendType" SG_ 1040 ICU_BS2_FSOH 4;
BA_ "Description" SG_ 1040 ICU_BS2_FSOH "This signal indicates whether the state of SOH signal is fault or not";
BA_ "Version" SG_ 1040 ICU_BS2_FSOF "18.08.03";
BA_ "RoutingFactor" SG_ 1040 ICU_BS2_FSOF 0;
BA_ "UserSigValidity" SG_ 1040 ICU_BS2_FSOF 3;
BA_ "GenSigStartValue" SG_ 1040 ICU_BS2_FSOF 1;
BA_ "GenSigSendType" SG_ 1040 ICU_BS2_FSOF 4;
BA_ "Description" SG_ 1040 ICU_BS2_FSOF "This signal indicates whether the state of SOF signal is fault or not";
BA_ "Version" SG_ 1040 ICU_BS2_FQSTAT "18.08.03";
BA_ "RoutingFactor" SG_ 1040 ICU_BS2_FQSTAT 0;
BA_ "UserSigValidity" SG_ 1040 ICU_BS2_FQSTAT 3;
BA_ "GenSigStartValue" SG_ 1040 ICU_BS2_FQSTAT 1;
BA_ "GenSigSendType" SG_ 1040 ICU_BS2_FQSTAT 4;
BA_ "Description" SG_ 1040 ICU_BS2_FQSTAT "This signal indicates whether quiescent current is high or not compared to pre-defined value";
BA_ "Version" SG_ 1040 ICU_BS2SoH "21.07.05";
BA_ "RoutingFactor" SG_ 1040 ICU_BS2SoH 0;
BA_ "UserSigValidity" SG_ 1040 ICU_BS2SoH 3;
BA_ "GenSigStartValue" SG_ 1040 ICU_BS2SoH 255;
BA_ "GenSigSendType" SG_ 1040 ICU_BS2SoH 4;
BA_ "Description" SG_ 1040 ICU_BS2SoH "This signal is battery State of Health(SOH) as calculated by battery sensor.



This value shows reduction rate of nominal capacity.



This value can be used for diagnosis information of application system.";
BA_ "Version" SG_ 1040 ICU_BS2SoF "21.07.05";
BA_ "RoutingFactor" SG_ 1040 ICU_BS2SoF 0;
BA_ "UserSigValidity" SG_ 1040 ICU_BS2SoF 3;
BA_ "GenSigStartValue" SG_ 1040 ICU_BS2SoF 255;
BA_ "GenSigSendType" SG_ 1040 ICU_BS2SoF 4;
BA_ "Description" SG_ 1040 ICU_BS2SoF "This signal is battery State of Function(SOF) as calculated by battery sensor.



This value shows information about the battery ability to crank the engine (both of warm & cold cranking).



This value is prediction value of the minimum voltage for the ";
BA_ "Version" SG_ 95 CF_AVN_MdLpBttmRedNvalueSet "21.05.01";
BA_ "UserSigValidity" SG_ 95 CF_AVN_MdLpBttmRedNvalueSet 3;
BA_ "GenSigStartValue" SG_ 95 CF_AVN_MdLpBttmRedNvalueSet 512;
BA_ "GenSigSendType" SG_ 95 CF_AVN_MdLpBttmRedNvalueSet 4;
BA_ "Description" SG_ 95 CF_AVN_MdLpBttmRedNvalueSet "USM Mood Lamp Bottom Red Color Set signal";
BA_ "Version" SG_ 95 CF_AVN_MdLpBttmGreenNvalueSet "21.05.01";
BA_ "UserSigValidity" SG_ 95 CF_AVN_MdLpBttmGreenNvalueSet 3;
BA_ "GenSigStartValue" SG_ 95 CF_AVN_MdLpBttmGreenNvalueSet 512;
BA_ "GenSigSendType" SG_ 95 CF_AVN_MdLpBttmGreenNvalueSet 4;
BA_ "Description" SG_ 95 CF_AVN_MdLpBttmGreenNvalueSet "USM Mood Lamp Bottom Green Color Set signal";
BA_ "Version" SG_ 95 CF_AVN_MdLpBttmBlueNvalueSet "22.07.02";
BA_ "UserSigValidity" SG_ 95 CF_AVN_MdLpBttmBlueNvalueSet 3;
BA_ "GenSigStartValue" SG_ 95 CF_AVN_MdLpBttmBlueNvalueSet 512;
BA_ "GenSigSendType" SG_ 95 CF_AVN_MdLpBttmBlueNvalueSet 4;
BA_ "Description" SG_ 95 CF_AVN_MdLpBttmBlueNvalueSet "USM Mood Lamp Bottom Red Color Set Signal";
BA_ "Version" SG_ 95 CF_AVN_MdLpSpdModNvalueSet "21.05.01";
BA_ "UserSigValidity" SG_ 95 CF_AVN_MdLpSpdModNvalueSet 3;
BA_ "GenSigSendType" SG_ 95 CF_AVN_MdLpSpdModNvalueSet 4;
BA_ "Description" SG_ 95 CF_AVN_MdLpSpdModNvalueSet "USM Mood Lamp Speed relation setting Set signal";
BA_ "Version" SG_ 95 CF_AVN_MdLpColorModNvalueSet "21.05.01";
BA_ "UserSigValidity" SG_ 95 CF_AVN_MdLpColorModNvalueSet 3;
BA_ "GenSigSendType" SG_ 95 CF_AVN_MdLpColorModNvalueSet 4;
BA_ "Description" SG_ 95 CF_AVN_MdLpColorModNvalueSet "USM Mood Lamp Mode number Set signal";
BA_ "Version" SG_ 95 CF_AVN_AIVoiceModNvalueSet "21.07.05";
BA_ "UserSigValidity" SG_ 95 CF_AVN_AIVoiceModNvalueSet 3;
BA_ "GenSigSendType" SG_ 95 CF_AVN_AIVoiceModNvalueSet 4;
BA_ "Version" SG_ 95 CF_AVN_AIVoiceMicModNvalue "22.01.06";
BA_ "UserSigValidity" SG_ 95 CF_AVN_AIVoiceMicModNvalue 3;
BA_ "GenSigSendType" SG_ 95 CF_AVN_AIVoiceMicModNvalue 4;
BA_ "Version" SG_ 95 CF_AVN_AIVoiceTTSModNvalue "22.01.06";
BA_ "UserSigValidity" SG_ 95 CF_AVN_AIVoiceTTSModNvalue 3;
BA_ "GenSigSendType" SG_ 95 CF_AVN_AIVoiceTTSModNvalue 4;
BA_ "Version" SG_ 95 CF_AVN_WiperAutoModeSet "21.12.00";
BA_ "UserSigValidity" SG_ 95 CF_AVN_WiperAutoModeSet 3;
BA_ "GenSigSendType" SG_ 95 CF_AVN_WiperAutoModeSet 4;
BA_ "Description" SG_ 95 CF_AVN_WiperAutoModeSet "Auto Washer Mode Wiper working set signal";
BA_ "Version" SG_ 95 CF_AVN_AFCUAutoWashModeSet "22.01.06";
BA_ "UserSigValidity" SG_ 95 CF_AVN_AFCUAutoWashModeSet 3;
BA_ "GenSigSendType" SG_ 95 CF_AVN_AFCUAutoWashModeSet 4;
BA_ "Description" SG_ 95 CF_AVN_AFCUAutoWashModeSet "Auto wash set signal for AFCU unit";
BA_ "Version" SG_ 95 CF_AVN_PSDAutoWashModeSet "22.01.06";
BA_ "UserSigValidity" SG_ 95 CF_AVN_PSDAutoWashModeSet 3;
BA_ "GenSigSendType" SG_ 95 CF_AVN_PSDAutoWashModeSet 4;
BA_ "Description" SG_ 95 CF_AVN_PSDAutoWashModeSet "Auto wash mode set signal for PSD Unit";
BA_ "Version" SG_ 95 CF_AVN_PTGAutoWashModeSet "22.01.06";
BA_ "UserSigValidity" SG_ 95 CF_AVN_PTGAutoWashModeSet 3;
BA_ "GenSigSendType" SG_ 95 CF_AVN_PTGAutoWashModeSet 4;
BA_ "Description" SG_ 95 CF_AVN_PTGAutoWashModeSet "Auto Wash Mode Set signal for PTG(PTL) Unit";
BA_ "Version" SG_ 95 CF_AVN_CDMAutoWashModeSet "22.02.01";
BA_ "UserSigValidity" SG_ 95 CF_AVN_CDMAutoWashModeSet 3;
BA_ "GenSigSendType" SG_ 95 CF_AVN_CDMAutoWashModeSet 4;
BA_ "Description" SG_ 95 CF_AVN_CDMAutoWashModeSet "Auto wash mode set signal for CDM";
BA_ "Version" SG_ 1043 ICU_Crc4Val "21.09.03";
BA_ "RoutingFactor" SG_ 1043 ICU_Crc4Val 0;
BA_ "UserSigValidity" SG_ 1043 ICU_Crc4Val 0;
BA_ "GenSigSendType" SG_ 1043 ICU_Crc4Val 4;
BA_ "Description" SG_ 1043 ICU_Crc4Val "The data area for CRC calculation is based on the data length (DLC) of the message DB.

The CRC shall be calculated over the entire data block (excluding the CRC bytes) including the user data, alive counter and Data ID 

 

- CRC Polynomial (0x1D) , Ini";
BA_ "Version" SG_ 1043 Lamp_TrnSigLmpRtActiveSt "21.11.00";
BA_ "RoutingFactor" SG_ 1043 Lamp_TrnSigLmpRtActiveSt 0;
BA_ "NetworkRequestHoldingTime" SG_ 1043 Lamp_TrnSigLmpRtActiveSt 5000;
BA_ "NetworkRequest" SG_ 1043 Lamp_TrnSigLmpRtActiveSt 0;
BA_ "UserSigValidity" SG_ 1043 Lamp_TrnSigLmpRtActiveSt 0;
BA_ "GenSigSendType" SG_ 1043 Lamp_TrnSigLmpRtActiveSt 4;
BA_ "Description" SG_ 1043 Lamp_TrnSigLmpRtActiveSt "Turn Signal Lamp Blink Info";
BA_ "Version" SG_ 1043 ICU_AlvCnt4Val "21.09.03";
BA_ "RoutingFactor" SG_ 1043 ICU_AlvCnt4Val 0;
BA_ "UserSigValidity" SG_ 1043 ICU_AlvCnt4Val 0;
BA_ "GenSigSendType" SG_ 1043 ICU_AlvCnt4Val 4;
BA_ "Description" SG_ 1043 ICU_AlvCnt4Val "For the first transmission request for a data element the counter shall be initialized with 0 and shall be incremented by 1

for every subsequent send request. When the counter reaches the maximum value(0xE), then it shall restart with 0 for the next sen";
BA_ "Version" SG_ 1043 ExtLamp_HzrdSwSta "17.12.00";
BA_ "RoutingFactor" SG_ 1043 ExtLamp_HzrdSwSta 0;
BA_ "NetworkRequestHoldingTime" SG_ 1043 ExtLamp_HzrdSwSta 5000;
BA_ "NetworkRequest" SG_ 1043 ExtLamp_HzrdSwSta 0;
BA_ "UserSigValidity" SG_ 1043 ExtLamp_HzrdSwSta 0;
BA_ "GenSigSendType" SG_ 1043 ExtLamp_HzrdSwSta 4;
BA_ "Version" SG_ 1043 IntLamp_InlTailLmpSta "17.12.00";
BA_ "RoutingFactor" SG_ 1043 IntLamp_InlTailLmpSta 0;
BA_ "NetworkRequestHoldingTime" SG_ 1043 IntLamp_InlTailLmpSta 5000;
BA_ "NetworkRequest" SG_ 1043 IntLamp_InlTailLmpSta 0;
BA_ "UserSigValidity" SG_ 1043 IntLamp_InlTailLmpSta 0;
BA_ "GenSigSendType" SG_ 1043 IntLamp_InlTailLmpSta 4;
BA_ "Description" SG_ 1043 IntLamp_InlTailLmpSta "-(Old)C_INTTail_Act";
BA_ "Version" SG_ 1043 Lamp_LedHdLmpSta "21.11.00";
BA_ "RoutingFactor" SG_ 1043 Lamp_LedHdLmpSta 0;
BA_ "NetworkRequestHoldingTime" SG_ 1043 Lamp_LedHdLmpSta 5000;
BA_ "NetworkRequest" SG_ 1043 Lamp_LedHdLmpSta 0;
BA_ "UserSigValidity" SG_ 1043 Lamp_LedHdLmpSta 3;
BA_ "GenSigSendType" SG_ 1043 Lamp_LedHdLmpSta 4;
BA_ "Description" SG_ 1043 Lamp_LedHdLmpSta "This signal is LED headlamp status inform whether LED fail or not which is regulation of ECE, Domestic.



If LED H/Lamp detects LED failure then a cluster shall be turn on to 'LED' indicator in the display panel and It should be to display the words 'Ch";
BA_ "Version" SG_ 1043 TrnLmpSeqEnblCmd "20.08.07";
BA_ "RoutingFactor" SG_ 1043 TrnLmpSeqEnblCmd 0;
BA_ "NetworkRequestHoldingTime" SG_ 1043 TrnLmpSeqEnblCmd 5000;
BA_ "NetworkRequest" SG_ 1043 TrnLmpSeqEnblCmd 0;
BA_ "UserSigValidity" SG_ 1043 TrnLmpSeqEnblCmd 0;
BA_ "GenSigSendType" SG_ 1043 TrnLmpSeqEnblCmd 4;
BA_ "Description" SG_ 1043 TrnLmpSeqEnblCmd "Turn Signal Sequential Enable CAN Command";
BA_ "Version" SG_ 1043 Lamp_TrnSigLmpLftOnReq "22.05.04";
BA_ "RoutingFactor" SG_ 1043 Lamp_TrnSigLmpLftOnReq 0;
BA_ "NetworkRequestHoldingTime" SG_ 1043 Lamp_TrnSigLmpLftOnReq 5000;
BA_ "NetworkRequest" SG_ 1043 Lamp_TrnSigLmpLftOnReq 0;
BA_ "UserSigValidity" SG_ 1043 Lamp_TrnSigLmpLftOnReq 0;
BA_ "GenSigSendType" SG_ 1043 Lamp_TrnSigLmpLftOnReq 4;
BA_ "Version" SG_ 1043 Lamp_TrnSigLmpRtOnReq "22.05.04";
BA_ "RoutingFactor" SG_ 1043 Lamp_TrnSigLmpRtOnReq 0;
BA_ "NetworkRequestHoldingTime" SG_ 1043 Lamp_TrnSigLmpRtOnReq 5000;
BA_ "NetworkRequest" SG_ 1043 Lamp_TrnSigLmpRtOnReq 0;
BA_ "UserSigValidity" SG_ 1043 Lamp_TrnSigLmpRtOnReq 0;
BA_ "GenSigSendType" SG_ 1043 Lamp_TrnSigLmpRtOnReq 4;
BA_ "Version" SG_ 1043 ICU_HDPSpprtRdy "22.03.02";
BA_ "RoutingFactor" SG_ 1043 ICU_HDPSpprtRdy 0;
BA_ "UserSigValidity" SG_ 1043 ICU_HDPSpprtRdy 3;
BA_ "GenSigSendType" SG_ 1043 ICU_HDPSpprtRdy 4;
BA_ "Description" SG_ 1043 ICU_HDPSpprtRdy "This signal is the received state information signal of the ADAS message.";
BA_ "Version" SG_ 1043 Lamp_TrnSigLmpLftActiveSt "21.11.00";
BA_ "RoutingFactor" SG_ 1043 Lamp_TrnSigLmpLftActiveSt 0;
BA_ "NetworkRequestHoldingTime" SG_ 1043 Lamp_TrnSigLmpLftActiveSt 5000;
BA_ "NetworkRequest" SG_ 1043 Lamp_TrnSigLmpLftActiveSt 0;
BA_ "UserSigValidity" SG_ 1043 Lamp_TrnSigLmpLftActiveSt 0;
BA_ "GenSigSendType" SG_ 1043 Lamp_TrnSigLmpLftActiveSt 4;
BA_ "Description" SG_ 1043 Lamp_TrnSigLmpLftActiveSt "Turn Signal Lmap Blink Info";
BA_ "Version" SG_ 1044 ICU_Crc5Val "21.09.03";
BA_ "RoutingFactor" SG_ 1044 ICU_Crc5Val 0;
BA_ "UserSigValidity" SG_ 1044 ICU_Crc5Val 0;
BA_ "GenSigSendType" SG_ 1044 ICU_Crc5Val 4;
BA_ "Description" SG_ 1044 ICU_Crc5Val "The data area for CRC calculation is based on the data length (DLC) of the message DB.

The CRC shall be calculated over the entire data block (excluding the CRC bytes) including the user data, alive counter and Data ID 

 

- CRC Polynomial (0x1D) , Ini";
BA_ "Version" SG_ 1044 ICU_AlvCnt5Val "21.09.03";
BA_ "RoutingFactor" SG_ 1044 ICU_AlvCnt5Val 0;
BA_ "UserSigValidity" SG_ 1044 ICU_AlvCnt5Val 0;
BA_ "GenSigSendType" SG_ 1044 ICU_AlvCnt5Val 4;
BA_ "Description" SG_ 1044 ICU_AlvCnt5Val "For the first transmission request for a data element the counter shall be initialized with 0 and shall be incremented by 1

for every subsequent send request. When the counter reaches the maximum value(0xE), then it shall restart with 0 for the next sen";
BA_ "Version" SG_ 1044 Trunk_TrnkInReleaseSwSta "23.04.02";
BA_ "RoutingFactor" SG_ 1044 Trunk_TrnkInReleaseSwSta 0;
BA_ "NetworkRequestHoldingTime" SG_ 1044 Trunk_TrnkInReleaseSwSta 5000;
BA_ "NetworkRequest" SG_ 1044 Trunk_TrnkInReleaseSwSta 0;
BA_ "UserSigValidity" SG_ 1044 Trunk_TrnkInReleaseSwSta 0;
BA_ "GenSigSendType" SG_ 1044 Trunk_TrnkInReleaseSwSta 4;
BA_ "Description" SG_ 1044 Trunk_TrnkInReleaseSwSta "-Trunk Inner Release SW";
BA_ "Version" SG_ 1044 Trunk_TrnkTlgtOutReleaseSwSta "23.04.02";
BA_ "RoutingFactor" SG_ 1044 Trunk_TrnkTlgtOutReleaseSwSta 0;
BA_ "NetworkRequestHoldingTime" SG_ 1044 Trunk_TrnkTlgtOutReleaseSwSta 5000;
BA_ "NetworkRequest" SG_ 1044 Trunk_TrnkTlgtOutReleaseSwSta 0;
BA_ "UserSigValidity" SG_ 1044 Trunk_TrnkTlgtOutReleaseSwSta 0;
BA_ "GenSigSendType" SG_ 1044 Trunk_TrnkTlgtOutReleaseSwSta 4;
BA_ "Description" SG_ 1044 Trunk_TrnkTlgtOutReleaseSwSta "-(Old)C_TRUNK_LID

-Trunk/Tailgate Outter Release SW";
BA_ "Version" SG_ 1044 Trunk_TrnkTlgtSwSta "17.12.00";
BA_ "RoutingFactor" SG_ 1044 Trunk_TrnkTlgtSwSta 0;
BA_ "NetworkRequestHoldingTime" SG_ 1044 Trunk_TrnkTlgtSwSta 5000;
BA_ "NetworkRequest" SG_ 1044 Trunk_TrnkTlgtSwSta 0;
BA_ "UserSigValidity" SG_ 1044 Trunk_TrnkTlgtSwSta 0;
BA_ "GenSigSendType" SG_ 1044 Trunk_TrnkTlgtSwSta 4;
BA_ "Description" SG_ 1044 Trunk_TrnkTlgtSwSta "Full Lock SW Status Signal



(TailGate/TrunkLid Tpye all)



1. Luggage or Trunkroom Lamp On/Off



2. TailGate/TrunkLid Open Ind in cluster



3. Normal Open SW



  - SW Off: Full Lock(Full Close state)



  - SW On: ^Full Lock";
BA_ "Version" SG_ 1044 Trunk_GlvBxTrnkLkSwSta "17.12.00";
BA_ "RoutingFactor" SG_ 1044 Trunk_GlvBxTrnkLkSwSta 0;
BA_ "NetworkRequestHoldingTime" SG_ 1044 Trunk_GlvBxTrnkLkSwSta 5000;
BA_ "NetworkRequest" SG_ 1044 Trunk_GlvBxTrnkLkSwSta 0;
BA_ "UserSigValidity" SG_ 1044 Trunk_GlvBxTrnkLkSwSta 0;
BA_ "GenSigSendType" SG_ 1044 Trunk_GlvBxTrnkLkSwSta 4;
BA_ "Description" SG_ 1044 Trunk_GlvBxTrnkLkSwSta "- Glove Box Trunk Lock SW";
BA_ "Version" SG_ 1044 Trunk_TlgtFullOpnSwSta "17.12.00";
BA_ "RoutingFactor" SG_ 1044 Trunk_TlgtFullOpnSwSta 0;
BA_ "NetworkRequestHoldingTime" SG_ 1044 Trunk_TlgtFullOpnSwSta 5000;
BA_ "NetworkRequest" SG_ 1044 Trunk_TlgtFullOpnSwSta 0;
BA_ "UserSigValidity" SG_ 1044 Trunk_TlgtFullOpnSwSta 0;
BA_ "GenSigSendType" SG_ 1044 Trunk_TlgtFullOpnSwSta 4;
BA_ "Description" SG_ 1044 Trunk_TlgtFullOpnSwSta "Full Open SW Status Signal



(Power TailGate/TrunkLid Tpye or tailgate latch 2sw type)



* Normal Open SW



  - SW Off: ^Full Open



  - SW On: Full Open(Full Open state)";
BA_ "Version" SG_ 1044 Trunk_TrnkTlgtReleaseRlySta "17.12.00";
BA_ "RoutingFactor" SG_ 1044 Trunk_TrnkTlgtReleaseRlySta 0;
BA_ "NetworkRequestHoldingTime" SG_ 1044 Trunk_TrnkTlgtReleaseRlySta 5000;
BA_ "NetworkRequest" SG_ 1044 Trunk_TrnkTlgtReleaseRlySta 0;
BA_ "UserSigValidity" SG_ 1044 Trunk_TrnkTlgtReleaseRlySta 0;
BA_ "GenSigSendType" SG_ 1044 Trunk_TrnkTlgtReleaseRlySta 4;
BA_ "Version" SG_ 1044 USM_OneTouchTrnSigFuncSta "21.07.05";
BA_ "RoutingFactor" SG_ 1044 USM_OneTouchTrnSigFuncSta 0;
BA_ "NetworkRequestHoldingTime" SG_ 1044 USM_OneTouchTrnSigFuncSta 5000;
BA_ "NetworkRequest" SG_ 1044 USM_OneTouchTrnSigFuncSta 0;
BA_ "UserSigValidity" SG_ 1044 USM_OneTouchTrnSigFuncSta 0;
BA_ "GenSigSendType" SG_ 1044 USM_OneTouchTrnSigFuncSta 4;
BA_ "Description" SG_ 1044 USM_OneTouchTrnSigFuncSta "This signal is 



- For One Touch Turn Signal Function,



 the advanced version of One Touch triple turn signal



- Communicated with Cluster for setting USM



- Periodic Event Signal to notice current staus to USM of Cluster";
BA_ "Version" SG_ 1044 DoorLock_DrvDrUnLkSta "21.09.05";
BA_ "RoutingFactor" SG_ 1044 DoorLock_DrvDrUnLkSta 0;
BA_ "NetworkRequestHoldingTime" SG_ 1044 DoorLock_DrvDrUnLkSta 5000;
BA_ "NetworkRequest" SG_ 1044 DoorLock_DrvDrUnLkSta 0;
BA_ "UserSigValidity" SG_ 1044 DoorLock_DrvDrUnLkSta 0;
BA_ "GenSigSendType" SG_ 1044 DoorLock_DrvDrUnLkSta 4;
BA_ "Version" SG_ 1044 DoorLock_LkOutSta "17.12.00";
BA_ "RoutingFactor" SG_ 1044 DoorLock_LkOutSta 0;
BA_ "NetworkRequestHoldingTime" SG_ 1044 DoorLock_LkOutSta 5000;
BA_ "NetworkRequest" SG_ 1044 DoorLock_LkOutSta 0;
BA_ "UserSigValidity" SG_ 1044 DoorLock_LkOutSta 0;
BA_ "GenSigSendType" SG_ 1044 DoorLock_LkOutSta 4;
BA_ "Description" SG_ 1044 DoorLock_LkOutSta "- Door Lock or Unlock Output State 



0x0 : Off (Door lock/unlock output Off state)



0x1 : On (Door lock/unlock output On state)";
BA_ "Version" SG_ 1044 C_CrashUnlockState "21.07.05";
BA_ "RoutingFactor" SG_ 1044 C_CrashUnlockState 0;
BA_ "NetworkRequest" SG_ 1044 C_CrashUnlockState 0;
BA_ "UserSigValidity" SG_ 1044 C_CrashUnlockState 0;
BA_ "GenSigSendType" SG_ 1044 C_CrashUnlockState 4;
BA_ "Description" SG_ 1044 C_CrashUnlockState "Crash Unlock Active State

-0x0:Off

-0x1:Unlock(crash)";
BA_ "Version" SG_ 1044 C_AutoLeverManualSW "19.09.06";
BA_ "RoutingFactor" SG_ 1044 C_AutoLeverManualSW 0;
BA_ "UserSigValidity" SG_ 1044 C_AutoLeverManualSW 3;
BA_ "GenSigSendType" SG_ 1044 C_AutoLeverManualSW 4;
BA_ "Description" SG_ 1044 C_AutoLeverManualSW "This signal represents operating status of AT/CVT/DCT Lever Manual Switch";
BA_REL_ "GenSigTimeoutTime" BU_SG_REL_ EMCU SG_ 2176875010 ECSIVSS_RdRoughVal 1500;
BA_REL_ "GenSigTimeoutTime" BU_SG_REL_ CGW_CCU SG_ 1130 DLBCU_LumbarUpDis 1500;
BA_REL_ "GenSigTimeoutTime" BU_SG_REL_ GW_DPSU SG_ 1130 DLBCU_LumbarUpDis 1500;
BA_REL_ "GenSigTimeoutTime" BU_SG_REL_ CGW_CCU SG_ 1130 DLBCU_LumbarMidDis 1500;
BA_REL_ "GenSigTimeoutTime" BU_SG_REL_ GW_DPSU SG_ 1130 DLBCU_LumbarMidDis 1500;
BA_REL_ "GenSigTimeoutTime" BU_SG_REL_ CGW_CCU SG_ 1130 DLBCU_LumbarLowDis 1500;
BA_REL_ "GenSigTimeoutTime" BU_SG_REL_ GW_DPSU SG_ 1130 DLBCU_LumbarLowDis 1500;
BA_REL_ "GenSigTimeoutTime" BU_SG_REL_ CGW_CCU SG_ 1130 DLBCU_LumbarDefDis 1500;
BA_REL_ "GenSigTimeoutTime" BU_SG_REL_ GW_DPSU SG_ 1130 DLBCU_LumbarDefDis 1500;
BA_REL_ "GenSigTimeoutTime" BU_SG_REL_ CGW_CCU SG_ 1131 DLBCU_BolsterInfDis 1500;
BA_REL_ "GenSigTimeoutTime" BU_SG_REL_ GW_DPSU SG_ 1131 DLBCU_BolsterInfDis 1500;
BA_REL_ "GenSigTimeoutTime" BU_SG_REL_ CGW_CCU SG_ 1131 DLBCU_BolsterDefDis 1500;
BA_REL_ "GenSigTimeoutTime" BU_SG_REL_ GW_DPSU SG_ 1131 DLBCU_BolsterDefDis 1500;
BA_REL_ "GenSigTimeoutTime" BU_SG_REL_ GW_DLBCU SG_ 1128 DPSS_Crc2Val 1500;
BA_REL_ "GenSigTimeoutTime" BU_SG_REL_ GW_DLBCU SG_ 1128 DPSS_AlvCnt2Val 1500;
BA_REL_ "GenSigTimeoutTime" BU_SG_REL_ CGW_CCU SG_ 1128 DPSS_LumbarUpSw 1500;
BA_REL_ "GenSigTimeoutTime" BU_SG_REL_ GW_DLBCU SG_ 1128 DPSS_LumbarUpSw 1500;
BA_REL_ "GenSigTimeoutTime" BU_SG_REL_ CGW_CCU SG_ 1128 DPSS_LumbarMidSw 1500;
BA_REL_ "GenSigTimeoutTime" BU_SG_REL_ GW_DLBCU SG_ 1128 DPSS_LumbarMidSw 1500;
BA_REL_ "GenSigTimeoutTime" BU_SG_REL_ CGW_CCU SG_ 1128 DPSS_LumbarLowSw 1500;
BA_REL_ "GenSigTimeoutTime" BU_SG_REL_ GW_DLBCU SG_ 1128 DPSS_LumbarLowSw 1500;
BA_REL_ "GenSigTimeoutTime" BU_SG_REL_ CGW_CCU SG_ 1128 DPSS_LumbarDefSw 1500;
BA_REL_ "GenSigTimeoutTime" BU_SG_REL_ GW_DLBCU SG_ 1128 DPSS_LumbarDefSw 1500;
BA_REL_ "GenSigTimeoutTime" BU_SG_REL_ GW_DLBCU SG_ 1128 DPSS_BolsterInfSw 1500;
BA_REL_ "GenSigTimeoutTime" BU_SG_REL_ GW_DLBCU SG_ 1128 DPSS_BolsterDefSw 1500;
BA_REL_ "GenSigTimeoutTime" BU_SG_REL_ GW_DLBCU SG_ 1128 DPSS_ActiveSw 1500;
BA_REL_ "GenSigTimeoutTime" BU_SG_REL_ GW_DLBCU SG_ 1128 DPSS_CushInfSw 1500;
BA_REL_ "GenSigTimeoutTime" BU_SG_REL_ GW_DLBCU SG_ 1128 DPSS_CushDefSw 1500;
BA_REL_ "GenSigTimeoutTime" BU_SG_REL_ CGW_CCU SG_ 1129 DPSS_Crc3Val 1500;
BA_REL_ "GenSigTimeoutTime" BU_SG_REL_ CGW_CCU SG_ 1129 DPSS_SldTch 1500;
BA_REL_ "GenSigTimeoutTime" BU_SG_REL_ CGW_CCU SG_ 1129 DPSS_RclTch 1500;
BA_REL_ "GenSigTimeoutTime" BU_SG_REL_ CGW_CCU SG_ 1129 DPSS_ExtTch 1500;
BA_REL_ "GenSigTimeoutTime" BU_SG_REL_ CGW_CCU SG_ 1129 DPSS_LmbrTch 1500;
BA_REL_ "GenSigTimeoutTime" BU_SG_REL_ CGW_CCU SG_ 1129 DPSS_CushOnOffTch 1500;
BA_REL_ "GenSigTimeoutTime" BU_SG_REL_ CGW_CCU SG_ 1129 DPSS_HRestTch 1500;
BA_REL_ "GenSigTimeoutTime" BU_SG_REL_ CGW_CCU SG_ 1129 DPSS_RelaxTch 1500;
BA_REL_ "GenSigTimeoutTime" BU_SG_REL_ CGW_CCU SG_ 1129 DPSS_ThighTch 1500;
BA_REL_ "GenSigTimeoutTime" BU_SG_REL_ CGW_CCU SG_ 1129 DPSS_ExtThighTch 1500;
BA_REL_ "GenSigTimeoutTime" BU_SG_REL_ CGW_CCU SG_ 1129 DPSS_LmbrBolsterTch 1500;
BA_REL_ "GenSigTimeoutTime" BU_SG_REL_ ATS SG_ 1124 SunRoof_RrBlindPosSta 1500;
BA_REL_ "GenSigTimeoutTime" BU_SG_REL_ CGW_CCU SG_ 1141 Ast_SHVU_SeatOptSta 1500;
BA_REL_ "GenSigTimeoutTime" BU_SG_REL_ FCS SG_ 1141 Ast_SHVU_SeatOptSta 1500;
BA_REL_ "GenSigTimeoutTime" BU_SG_REL_ CGW_CCU SG_ 1141 Ast_SHVU_HtSwHiIndSta 1500;
BA_REL_ "GenSigTimeoutTime" BU_SG_REL_ FCS SG_ 1141 Ast_SHVU_HtSwHiIndSta 1500;
BA_REL_ "GenSigTimeoutTime" BU_SG_REL_ CGW_CCU SG_ 1141 Ast_SHVU_HtSwMidIndSta 1500;
BA_REL_ "GenSigTimeoutTime" BU_SG_REL_ FCS SG_ 1141 Ast_SHVU_HtSwMidIndSta 1500;
BA_REL_ "GenSigTimeoutTime" BU_SG_REL_ CGW_CCU SG_ 1141 Ast_SHVU_HtSwLowIndSta 1500;
BA_REL_ "GenSigTimeoutTime" BU_SG_REL_ FCS SG_ 1141 Ast_SHVU_HtSwLowIndSta 1500;
BA_REL_ "GenSigTimeoutTime" BU_SG_REL_ CGW_CCU SG_ 1141 Ast_SHVU_VntSwHiIndSta 1500;
BA_REL_ "GenSigTimeoutTime" BU_SG_REL_ FCS SG_ 1141 Ast_SHVU_VntSwHiIndSta 1500;
BA_REL_ "GenSigTimeoutTime" BU_SG_REL_ CGW_CCU SG_ 1141 Ast_SHVU_VntSwMidIndSta 1500;
BA_REL_ "GenSigTimeoutTime" BU_SG_REL_ FCS SG_ 1141 Ast_SHVU_VntSwMidIndSta 1500;
BA_REL_ "GenSigTimeoutTime" BU_SG_REL_ CGW_CCU SG_ 1141 Ast_SHVU_VntSwLowIndSta 1500;
BA_REL_ "GenSigTimeoutTime" BU_SG_REL_ FCS SG_ 1141 Ast_SHVU_VntSwLowIndSta 1500;
BA_REL_ "GenSigTimeoutTime" BU_SG_REL_ CGW_CCU SG_ 1141 Ast_SHVU_HtBlcUSMSta 1500;
BA_REL_ "GenSigTimeoutTime" BU_SG_REL_ CGW_CCU SG_ 1141 Ast_SHVU_SeatHtOperSta 1500;
BA_REL_ "GenSigTimeoutTime" BU_SG_REL_ FCS SG_ 1141 Ast_SHVU_SeatHtOperSta 1500;
BA_REL_ "GenSigTimeoutTime" BU_SG_REL_ CGW_CCU SG_ 1141 Ast_SHVU_HtSwHiIndSta_RHD 1500;
BA_REL_ "GenSigTimeoutTime" BU_SG_REL_ FCS SG_ 1141 Ast_SHVU_HtSwHiIndSta_RHD 1500;
BA_REL_ "GenSigTimeoutTime" BU_SG_REL_ CGW_CCU SG_ 1141 Ast_SHVU_HtSwMidIndSta_RHD 1500;
BA_REL_ "GenSigTimeoutTime" BU_SG_REL_ FCS SG_ 1141 Ast_SHVU_HtSwMidIndSta_RHD 1500;
BA_REL_ "GenSigTimeoutTime" BU_SG_REL_ CGW_CCU SG_ 1141 Ast_SHVU_HtSwLowIndSta_RHD 1500;
BA_REL_ "GenSigTimeoutTime" BU_SG_REL_ FCS SG_ 1141 Ast_SHVU_HtSwLowIndSta_RHD 1500;
BA_REL_ "GenSigTimeoutTime" BU_SG_REL_ CGW_CCU SG_ 1141 Ast_SHVU_VntSwHiIndSta_RHD 1500;
BA_REL_ "GenSigTimeoutTime" BU_SG_REL_ FCS SG_ 1141 Ast_SHVU_VntSwHiIndSta_RHD 1500;
BA_REL_ "GenSigTimeoutTime" BU_SG_REL_ CGW_CCU SG_ 1141 Ast_SHVU_VntSwMidIndSta_RHD 1500;
BA_REL_ "GenSigTimeoutTime" BU_SG_REL_ FCS SG_ 1141 Ast_SHVU_VntSwMidIndSta_RHD 1500;
BA_REL_ "GenSigTimeoutTime" BU_SG_REL_ CGW_CCU SG_ 1141 Ast_SHVU_VntSwLowIndSta_RHD 1500;
BA_REL_ "GenSigTimeoutTime" BU_SG_REL_ FCS SG_ 1141 Ast_SHVU_VntSwLowIndSta_RHD 1500;
BA_REL_ "GenSigTimeoutTime" BU_SG_REL_ FCS SG_ 2244046850 ADAS_PRK_PDW_SwIndOnReq 1500;
BA_REL_ "GenSigTimeoutTime" BU_SG_REL_ GW_DPSU SG_ 1027 Win_DrvIMSSwSta 1500;
BA_REL_ "GenSigTimeoutTime" BU_SG_REL_ GW_APSU SG_ 1029 ICU_IGN3On_ReqState_New 1500;
BA_REL_ "GenSigTimeoutTime" BU_SG_REL_ GW_DLBCU SG_ 1029 ICU_IGN3On_ReqState_New 1500;
BA_REL_ "GenSigTimeoutTime" BU_SG_REL_ GW_DPSU SG_ 1029 ICU_IGN3On_ReqState_New 1500;
BA_REL_ "GenSigTimeoutTime" BU_SG_REL_ GW_RLPSU SG_ 1029 ICU_IGN3On_ReqState_New 1500;
BA_REL_ "GenSigTimeoutTime" BU_SG_REL_ GW_RRPSU SG_ 1029 ICU_IGN3On_ReqState_New 1500;
BA_REL_ "GenSigTimeoutTime" BU_SG_REL_ PFSU SG_ 1029 ICU_IGN3On_ReqState_New 1500;
BA_REL_ "GenSigTimeoutTime" BU_SG_REL_ RLHV SG_ 1029 ICU_IGN3On_ReqState_New 1500;
BA_REL_ "GenSigTimeoutTime" BU_SG_REL_ RRHV SG_ 1029 ICU_IGN3On_ReqState_New 1500;
BA_REL_ "GenSigTimeoutTime" BU_SG_REL_ SHVU_FR SG_ 1029 ICU_IGN3On_ReqState_New 1500;
BA_REL_ "GenSigTimeoutTime" BU_SG_REL_ SHVU_RR SG_ 1029 ICU_IGN3On_ReqState_New 1500;
BA_REL_ "GenSigTimeoutTime" BU_SG_REL_ CGW_CCU SG_ 1030 APSM_SWVerMajor1 1500;
BA_REL_ "GenSigTimeoutTime" BU_SG_REL_ CGW_CCU SG_ 1030 APSM_SWVerMinor1 1500;
BA_REL_ "GenSigTimeoutTime" BU_SG_REL_ CGW_CCU SG_ 1030 APSM_SWVerMinor2 1500;
BA_REL_ "GenSigTimeoutTime" BU_SG_REL_ GW_RLPSU SG_ 1030 APSM_AstSeatPos_Sta 1500;
BA_REL_ "GenSigTimeoutTime" BU_SG_REL_ CGW_CCU SG_ 1030 APSM_AstSeatPosRclnLmt_Sta 1500;
BA_REL_ "GenSigTimeoutTime" BU_SG_REL_ CGW_CCU SG_ 1030 APSM_AstSeatPosSldLmt_Sta 1500;
BA_REL_ "GenSigTimeoutTime" BU_SG_REL_ GW_RLPSU SG_ 1031 APSM_RearModeEnable 1500;
BA_REL_ "GenSigTimeoutTime" BU_SG_REL_ GW_RRPSU SG_ 1031 APSM_RearModeEnable 1500;
BA_REL_ "GenSigTimeoutTime" BU_SG_REL_ GW_RLPSU SG_ 1031 APSM_SeatPosPlyBck_Sta 1500;
BA_REL_ "GenSigTimeoutTime" BU_SG_REL_ ALBCU SG_ 1031 APSM_AstStEsyAcsUSMSta 1500;
BA_REL_ "GenSigTimeoutTime" BU_SG_REL_ CGW_CCU SG_ 1031 APSM_AstStEsyAcsUSMSta 1500;
BA_REL_ "GenSigTimeoutTime" BU_SG_REL_ GW_RLPSU SG_ 1031 APSM_ReturnModeState 1500;
BA_REL_ "GenSigTimeoutTime" BU_SG_REL_ GW_RRPSU SG_ 1031 APSM_ReturnModeState 1500;
BA_REL_ "GenSigTimeoutTime" BU_SG_REL_ GW_RLPSU SG_ 1031 APSM_RelaxModeState 1500;
BA_REL_ "GenSigTimeoutTime" BU_SG_REL_ GW_RRPSU SG_ 1031 APSM_RelaxModeState 1500;
BA_REL_ "GenSigTimeoutTime" BU_SG_REL_ GW_RLPSU SG_ 1031 APSM_LimSetSta 1500;
BA_REL_ "GenSigTimeoutTime" BU_SG_REL_ GW_RRPSU SG_ 1031 APSM_LimSetSta 1500;
BA_REL_ "GenSigTimeoutTime" BU_SG_REL_ ATS SG_ 1048 DriveTypeOption 1500;
BA_REL_ "GenSigTimeoutTime" BU_SG_REL_ BLTN_CAM SG_ 1048 DriveTypeOption 1500;
BA_REL_ "GenSigTimeoutTime" BU_SG_REL_ GW_APSU SG_ 1048 DriveTypeOption 1500;
BA_REL_ "GenSigTimeoutTime" BU_SG_REL_ GW_DLBCU SG_ 1048 DriveTypeOption 1500;
BA_REL_ "GenSigTimeoutTime" BU_SG_REL_ GW_DPSU SG_ 1048 DriveTypeOption 1500;
BA_REL_ "GenSigTimeoutTime" BU_SG_REL_ GW_RLPSU SG_ 1048 DriveTypeOption 1500;
BA_REL_ "GenSigTimeoutTime" BU_SG_REL_ GW_RRPSU SG_ 1048 DriveTypeOption 1500;
BA_REL_ "GenSigTimeoutTime" BU_SG_REL_ SHVU_FR SG_ 1048 DriveTypeOption 1500;
BA_REL_ "GenSigTimeoutTime" BU_SG_REL_ SHVU_RR SG_ 1048 DriveTypeOption 1500;
BA_REL_ "GenSigTimeoutTime" BU_SG_REL_ BLTN_CAM SG_ 1048 ICU_PowerAutoCutModSta 1500;
BA_REL_ "GenSigTimeoutTime" BU_SG_REL_ GW_APSU SG_ 1048 ICU_PowerAutoCutModSta 1500;
BA_REL_ "GenSigTimeoutTime" BU_SG_REL_ GW_DPSU SG_ 1048 ICU_PowerAutoCutModSta 1500;
BA_REL_ "GenSigTimeoutTime" BU_SG_REL_ GW_RLPSU SG_ 1048 ICU_PowerAutoCutModSta 1500;
BA_REL_ "GenSigTimeoutTime" BU_SG_REL_ GW_RRPSU SG_ 1048 ICU_PowerAutoCutModSta 1500;
BA_REL_ "GenSigTimeoutTime" BU_SG_REL_ PFSU SG_ 1048 ICU_PowerAutoCutModSta 1500;
BA_REL_ "GenSigTimeoutTime" BU_SG_REL_ RLHV SG_ 1048 ICU_PowerAutoCutModSta 1500;
BA_REL_ "GenSigTimeoutTime" BU_SG_REL_ RRHV SG_ 1048 ICU_PowerAutoCutModSta 1500;
BA_REL_ "GenSigTimeoutTime" BU_SG_REL_ SHVU_FR SG_ 1048 ICU_PowerAutoCutModSta 1500;
BA_REL_ "GenSigTimeoutTime" BU_SG_REL_ SHVU_RR SG_ 1048 ICU_PowerAutoCutModSta 1500;
BA_REL_ "GenSigTimeoutTime" BU_SG_REL_ ARS SG_ 1048 C_3rdRCSeatBeltSW 1500;
BA_REL_ "GenSigTimeoutTime" BU_SG_REL_ GW_RLPSU SG_ 1048 C_3rdRCSeatBeltSW 1500;
BA_REL_ "GenSigTimeoutTime" BU_SG_REL_ GW_RRPSU SG_ 1048 C_3rdRCSeatBeltSW 1500;
BA_REL_ "GenSigTimeoutTime" BU_SG_REL_ PFSU SG_ 1048 C_3rdRCSeatBeltSW 1500;
BA_REL_ "GenSigTimeoutTime" BU_SG_REL_ WPC2 SG_ 1048 C_3rdRCSeatBeltSW 1500;
BA_REL_ "GenSigTimeoutTime" BU_SG_REL_ ARS SG_ 1048 C_3rdRRSBRMatSw 1500;
BA_REL_ "GenSigTimeoutTime" BU_SG_REL_ GW_RRPSU SG_ 1048 C_3rdRRSBRMatSw 1500;
BA_REL_ "GenSigTimeoutTime" BU_SG_REL_ PFSU SG_ 1048 C_3rdRRSBRMatSw 1500;
BA_REL_ "GenSigTimeoutTime" BU_SG_REL_ WPC2 SG_ 1048 C_3rdRRSBRMatSw 1500;
BA_REL_ "GenSigTimeoutTime" BU_SG_REL_ ARS SG_ 1048 C_3rdRLSBRMatSw 1500;
BA_REL_ "GenSigTimeoutTime" BU_SG_REL_ GW_RLPSU SG_ 1048 C_3rdRLSBRMatSw 1500;
BA_REL_ "GenSigTimeoutTime" BU_SG_REL_ PFSU SG_ 1048 C_3rdRLSBRMatSw 1500;
BA_REL_ "GenSigTimeoutTime" BU_SG_REL_ WPC2 SG_ 1048 C_3rdRLSBRMatSw 1500;
BA_REL_ "GenSigTimeoutTime" BU_SG_REL_ ARS SG_ 1048 C_3rdRRSeatBeltSW 1500;
BA_REL_ "GenSigTimeoutTime" BU_SG_REL_ GW_RRPSU SG_ 1048 C_3rdRRSeatBeltSW 1500;
BA_REL_ "GenSigTimeoutTime" BU_SG_REL_ PFSU SG_ 1048 C_3rdRRSeatBeltSW 1500;
BA_REL_ "GenSigTimeoutTime" BU_SG_REL_ WPC2 SG_ 1048 C_3rdRRSeatBeltSW 1500;
BA_REL_ "GenSigTimeoutTime" BU_SG_REL_ ARS SG_ 1048 C_3rdRLSeatBeltSW 1500;
BA_REL_ "GenSigTimeoutTime" BU_SG_REL_ GW_RLPSU SG_ 1048 C_3rdRLSeatBeltSW 1500;
BA_REL_ "GenSigTimeoutTime" BU_SG_REL_ PFSU SG_ 1048 C_3rdRLSeatBeltSW 1500;
BA_REL_ "GenSigTimeoutTime" BU_SG_REL_ WPC2 SG_ 1048 C_3rdRLSeatBeltSW 1500;
BA_REL_ "GenSigTimeoutTime" BU_SG_REL_ FCS SG_ 1050 Lamp_IntTailLmpOnReq 1500;
BA_REL_ "GenSigTimeoutTime" BU_SG_REL_ GW_APSU SG_ 1050 Lamp_IntTailLmpOnReq 1500;
BA_REL_ "GenSigTimeoutTime" BU_SG_REL_ GW_DPSU SG_ 1050 Lamp_IntTailLmpOnReq 1500;
BA_REL_ "GenSigTimeoutTime" BU_SG_REL_ RLHV SG_ 1050 Lamp_IntTailLmpOnReq 1500;
BA_REL_ "GenSigTimeoutTime" BU_SG_REL_ RRHV SG_ 1050 Lamp_IntTailLmpOnReq 1500;
BA_REL_ "GenSigTimeoutTime" BU_SG_REL_ RWPC SG_ 1050 Lamp_IntTailLmpOnReq 1500;
BA_REL_ "GenSigTimeoutTime" BU_SG_REL_ SHVU_FR SG_ 1050 Lamp_IntTailLmpOnReq 1500;
BA_REL_ "GenSigTimeoutTime" BU_SG_REL_ SHVU_RR SG_ 1050 Lamp_IntTailLmpOnReq 1500;
BA_REL_ "GenSigTimeoutTime" BU_SG_REL_ WPC SG_ 1050 Lamp_IntTailLmpOnReq 1500;
BA_REL_ "GenSigTimeoutTime" BU_SG_REL_ WPC2 SG_ 1050 Lamp_IntTailLmpOnReq 1500;
BA_REL_ "GenSigTimeoutTime" BU_SG_REL_ BLTN_CAM SG_ 1050 Lamp_ExtrnlTailLmpOnReq 1500;
BA_REL_ "GenSigTimeoutTime" BU_SG_REL_ ARS SG_ 1050 Lamp_AvTailLmpSta 1500;
BA_REL_ "GenSigTimeoutTime" BU_SG_REL_ ATS SG_ 1050 Lamp_AvTailLmpSta 1500;
BA_REL_ "GenSigTimeoutTime" BU_SG_REL_ GW_APSU SG_ 1050 Lamp_AvTailLmpSta 1500;
BA_REL_ "GenSigTimeoutTime" BU_SG_REL_ SWRC SG_ 1050 Lamp_AvTailLmpSta 1500;
BA_REL_ "GenSigTimeoutTime" BU_SG_REL_ ARS SG_ 1052 Lamp_AutoLtSnsrNightSta 1500;
BA_REL_ "GenSigTimeoutTime" BU_SG_REL_ ATS SG_ 1052 Lamp_AutoLtSnsrNightSta 1500;
BA_REL_ "GenSigTimeoutTime" BU_SG_REL_ GW_APSU SG_ 1052 Lamp_AutoLtSnsrNightSta 1500;
BA_REL_ "GenSigTimeoutTime" BU_SG_REL_ SWRC SG_ 1052 Lamp_AutoLtSnsrNightSta 1500;
BA_REL_ "GenSigTimeoutTime" BU_SG_REL_ ATS SG_ 1052 Lamp_AutoLtSnsrHorVal 1500;
BA_REL_ "GenSigTimeoutTime" BU_SG_REL_ BLTN_CAM SG_ 1041 ICU_MtGearPosRSta 1500;
BA_REL_ "GenSigTimeoutTime" BU_SG_REL_ BLTN_CAM SG_ 1041 Warn_DrvDrSwSta 1500;
BA_REL_ "GenSigTimeoutTime" BU_SG_REL_ GW_DPSU SG_ 1041 Warn_DrvDrSwSta 1500;
BA_REL_ "GenSigTimeoutTime" BU_SG_REL_ PSB SG_ 1041 Warn_DrvDrSwSta 1500;
BA_REL_ "GenSigTimeoutTime" BU_SG_REL_ RWPC SG_ 1041 Warn_DrvDrSwSta 1500;
BA_REL_ "GenSigTimeoutTime" BU_SG_REL_ WPC SG_ 1041 Warn_DrvDrSwSta 1500;
BA_REL_ "GenSigTimeoutTime" BU_SG_REL_ WPC2 SG_ 1041 Warn_DrvDrSwSta 1500;
BA_REL_ "GenSigTimeoutTime" BU_SG_REL_ ALBCU SG_ 1041 Warn_AsstDrSwSta 1500;
BA_REL_ "GenSigTimeoutTime" BU_SG_REL_ BLTN_CAM SG_ 1041 Warn_AsstDrSwSta 1500;
BA_REL_ "GenSigTimeoutTime" BU_SG_REL_ GW_APSU SG_ 1041 Warn_AsstDrSwSta 1500;
BA_REL_ "GenSigTimeoutTime" BU_SG_REL_ GW_RLPSU SG_ 1041 Warn_AsstDrSwSta 1500;
BA_REL_ "GenSigTimeoutTime" BU_SG_REL_ GW_RRPSU SG_ 1041 Warn_AsstDrSwSta 1500;
BA_REL_ "GenSigTimeoutTime" BU_SG_REL_ PSB SG_ 1041 Warn_AsstDrSwSta 1500;
BA_REL_ "GenSigTimeoutTime" BU_SG_REL_ RWPC SG_ 1041 Warn_AsstDrSwSta 1500;
BA_REL_ "GenSigTimeoutTime" BU_SG_REL_ WPC SG_ 1041 Warn_AsstDrSwSta 1500;
BA_REL_ "GenSigTimeoutTime" BU_SG_REL_ WPC2 SG_ 1041 Warn_AsstDrSwSta 1500;
BA_REL_ "GenSigTimeoutTime" BU_SG_REL_ ALBCU SG_ 1041 Warn_AsstStBltSwSta 1500;
BA_REL_ "GenSigTimeoutTime" BU_SG_REL_ ASAU SG_ 1041 Warn_AsstStBltSwSta 1500;
BA_REL_ "GenSigTimeoutTime" BU_SG_REL_ GW_APSU SG_ 1041 Warn_AsstStBltSwSta 1500;
BA_REL_ "GenSigTimeoutTime" BU_SG_REL_ GW_RLPSU SG_ 1041 Warn_AsstStBltSwSta 1500;
BA_REL_ "GenSigTimeoutTime" BU_SG_REL_ PSB SG_ 1041 Warn_AsstStBltSwSta 1500;
BA_REL_ "GenSigTimeoutTime" BU_SG_REL_ ASAU SG_ 1041 Warn_DrvStBltSwSta 1500;
BA_REL_ "GenSigTimeoutTime" BU_SG_REL_ ATS SG_ 1041 Warn_DrvStBltSwSta 1500;
BA_REL_ "GenSigTimeoutTime" BU_SG_REL_ DSAU SG_ 1041 Warn_DrvStBltSwSta 1500;
BA_REL_ "GenSigTimeoutTime" BU_SG_REL_ GW_DLBCU SG_ 1041 Warn_DrvStBltSwSta 1500;
BA_REL_ "GenSigTimeoutTime" BU_SG_REL_ GW_DPSU SG_ 1041 Warn_DrvStBltSwSta 1500;
BA_REL_ "GenSigTimeoutTime" BU_SG_REL_ PSB SG_ 1041 Warn_DrvStBltSwSta 1500;
BA_REL_ "GenSigTimeoutTime" BU_SG_REL_ BLTN_CAM SG_ 1041 Warn_HoodSwSta 1500;
BA_REL_ "GenSigTimeoutTime" BU_SG_REL_ GW_APSU SG_ 1041 Warn_PassStOccSta 1500;
BA_REL_ "GenSigTimeoutTime" BU_SG_REL_ GW_APSU SG_ 1041 Warn_PrkngBrkSwSta 1500;
BA_REL_ "GenSigTimeoutTime" BU_SG_REL_ GW_RLPSU SG_ 1041 Warn_PrkngBrkSwSta 1500;
BA_REL_ "GenSigTimeoutTime" BU_SG_REL_ GW_RRPSU SG_ 1041 Warn_PrkngBrkSwSta 1500;
BA_REL_ "GenSigTimeoutTime" BU_SG_REL_ PFSU SG_ 1041 Warn_PrkngBrkSwSta 1500;
BA_REL_ "GenSigTimeoutTime" BU_SG_REL_ RLHV SG_ 1041 Warn_PrkngBrkSwSta 1500;
BA_REL_ "GenSigTimeoutTime" BU_SG_REL_ RRHV SG_ 1041 Warn_PrkngBrkSwSta 1500;
BA_REL_ "GenSigTimeoutTime" BU_SG_REL_ GW_RLPSU SG_ 1041 Warn_RrCtrStBltSwSta 1500;
BA_REL_ "GenSigTimeoutTime" BU_SG_REL_ GW_RRPSU SG_ 1041 Warn_RrCtrStBltSwSta 1500;
BA_REL_ "GenSigTimeoutTime" BU_SG_REL_ PSB SG_ 1041 Warn_RrCtrStBltSwSta 1500;
BA_REL_ "GenSigTimeoutTime" BU_SG_REL_ BLTN_CAM SG_ 1041 Warn_RrLftDrSwSta 1500;
BA_REL_ "GenSigTimeoutTime" BU_SG_REL_ GW_APSU SG_ 1041 Warn_RrLftDrSwSta 1500;
BA_REL_ "GenSigTimeoutTime" BU_SG_REL_ GW_RLPSU SG_ 1041 Warn_RrLftDrSwSta 1500;
BA_REL_ "GenSigTimeoutTime" BU_SG_REL_ GW_RRPSU SG_ 1041 Warn_RrLftDrSwSta 1500;
BA_REL_ "GenSigTimeoutTime" BU_SG_REL_ RLHV SG_ 1041 Warn_RrLftDrSwSta 1500;
BA_REL_ "GenSigTimeoutTime" BU_SG_REL_ RWPC SG_ 1041 Warn_RrLftDrSwSta 1500;
BA_REL_ "GenSigTimeoutTime" BU_SG_REL_ WPC SG_ 1041 Warn_RrLftDrSwSta 1500;
BA_REL_ "GenSigTimeoutTime" BU_SG_REL_ WPC2 SG_ 1041 Warn_RrLftDrSwSta 1500;
BA_REL_ "GenSigTimeoutTime" BU_SG_REL_ GW_APSU SG_ 1041 Warn_RrLftStBltSwSta 1500;
BA_REL_ "GenSigTimeoutTime" BU_SG_REL_ GW_DPSU SG_ 1041 Warn_RrLftStBltSwSta 1500;
BA_REL_ "GenSigTimeoutTime" BU_SG_REL_ GW_RLPSU SG_ 1041 Warn_RrLftStBltSwSta 1500;
BA_REL_ "GenSigTimeoutTime" BU_SG_REL_ GW_RRPSU SG_ 1041 Warn_RrLftStBltSwSta 1500;
BA_REL_ "GenSigTimeoutTime" BU_SG_REL_ PSB SG_ 1041 Warn_RrLftStBltSwSta 1500;
BA_REL_ "GenSigTimeoutTime" BU_SG_REL_ BLTN_CAM SG_ 1041 Warn_RrRtDrSwSta 1500;
BA_REL_ "GenSigTimeoutTime" BU_SG_REL_ GW_APSU SG_ 1041 Warn_RrRtDrSwSta 1500;
BA_REL_ "GenSigTimeoutTime" BU_SG_REL_ GW_RLPSU SG_ 1041 Warn_RrRtDrSwSta 1500;
BA_REL_ "GenSigTimeoutTime" BU_SG_REL_ GW_RRPSU SG_ 1041 Warn_RrRtDrSwSta 1500;
BA_REL_ "GenSigTimeoutTime" BU_SG_REL_ RRHV SG_ 1041 Warn_RrRtDrSwSta 1500;
BA_REL_ "GenSigTimeoutTime" BU_SG_REL_ RWPC SG_ 1041 Warn_RrRtDrSwSta 1500;
BA_REL_ "GenSigTimeoutTime" BU_SG_REL_ WPC SG_ 1041 Warn_RrRtDrSwSta 1500;
BA_REL_ "GenSigTimeoutTime" BU_SG_REL_ WPC2 SG_ 1041 Warn_RrRtDrSwSta 1500;
BA_REL_ "GenSigTimeoutTime" BU_SG_REL_ GW_APSU SG_ 1041 Warn_RrRtStBltSwSta 1500;
BA_REL_ "GenSigTimeoutTime" BU_SG_REL_ GW_DPSU SG_ 1041 Warn_RrRtStBltSwSta 1500;
BA_REL_ "GenSigTimeoutTime" BU_SG_REL_ GW_RRPSU SG_ 1041 Warn_RrRtStBltSwSta 1500;
BA_REL_ "GenSigTimeoutTime" BU_SG_REL_ PSB SG_ 1041 Warn_RrRtStBltSwSta 1500;
BA_REL_ "GenSigTimeoutTime" BU_SG_REL_ BLTN_CAM SG_ 1040 ICU_BS2SoC 1500;
BA_REL_ "GenSigTimeoutTime" BU_SG_REL_ SWRC SG_ 95 CF_AVN_AIVoiceModNvalueSet 0;
BA_REL_ "GenSigTimeoutTime" BU_SG_REL_ SWRC SG_ 95 CF_AVN_AIVoiceMicModNvalue 0;
BA_REL_ "GenSigTimeoutTime" BU_SG_REL_ SWRC SG_ 95 CF_AVN_AIVoiceTTSModNvalue 0;
BA_REL_ "GenSigTimeoutTime" BU_SG_REL_ BLTN_CAM SG_ 1043 IntLamp_InlTailLmpSta 1500;
BA_REL_ "GenSigTimeoutTime" BU_SG_REL_ SWRC SG_ 1043 IntLamp_InlTailLmpSta 1500;
BA_REL_ "GenSigTimeoutTime" BU_SG_REL_ WPC2 SG_ 1043 IntLamp_InlTailLmpSta 1500;
BA_REL_ "GenSigTimeoutTime" BU_SG_REL_ BLTN_CAM SG_ 1043 Lamp_TrnSigLmpLftOnReq 1500;
BA_REL_ "GenSigTimeoutTime" BU_SG_REL_ BLTN_CAM SG_ 1043 Lamp_TrnSigLmpRtOnReq 1500;
BA_REL_ "GenSigTimeoutTime" BU_SG_REL_ BLTN_CAM SG_ 1044 Trunk_TrnkTlgtSwSta 1500;
BA_REL_ "GenSigTimeoutTime" BU_SG_REL_ GW_APSU SG_ 1044 Trunk_TrnkTlgtSwSta 1500;
BA_REL_ "GenSigTimeoutTime" BU_SG_REL_ GW_RLPSU SG_ 1044 Trunk_TrnkTlgtSwSta 1500;
BA_REL_ "GenSigTimeoutTime" BU_SG_REL_ GW_RRPSU SG_ 1044 Trunk_TrnkTlgtSwSta 1500;
BA_REL_ "GenSigTimeoutTime" BU_SG_REL_ PFSU SG_ 1044 Trunk_TrnkTlgtSwSta 1500;
BA_REL_ "GenSigTimeoutTime" BU_SG_REL_ RLHV SG_ 1044 Trunk_TrnkTlgtSwSta 1500;
BA_REL_ "GenSigTimeoutTime" BU_SG_REL_ RRHV SG_ 1044 Trunk_TrnkTlgtSwSta 1500;
BA_REL_ "GenSigTimeoutTime" BU_SG_REL_ GW_DPSU SG_ 1044 DoorLock_DrvDrUnLkSta 1500;
BA_REL_ "GenSigTimeoutTime" BU_SG_REL_ BLTN_CAM SG_ 1044 C_CrashUnlockState 1500;
VAL_ 2176875010 ECSIVSS_DmpCtrlrErrSta 0 "ECS Normal" 1 "ECS Error" 2 "Not used" 3 "Error Indicator" ;
VAL_ 2176875010 ECSIVSS_IVSSCtrlrErrSta 0 "Ivss signal is valid" 1 "Ivss signal is invalid" 2 "Not used" 3 "Error Indicator" ;
VAL_ 2176875010 ECSIVSS_AntRollCtrlSta 0 "Anti-roll Control Inactive" 1 "Anti-roll Control Active" 2 "Not used" 3 "Error Indicator" ;
VAL_ 2176875010 ECSIVSS_RdRoughVal 0 "0x0x00~0xFD:0~253" 253 "0x0x00~0xFD:0~253" 254 "Not used" 255 "Invalid" ;
VAL_ 2176875010 ECSIVSS_FLCtrlSta 0 "ECS" 1 "ICSC" 2 "Preview ECS" 3 "Preview ECS Limited" ;
VAL_ 1130 DLBCU_LumbarUpDis 0 "default" 1 "off" 2 "on" 3 "invalid" ;
VAL_ 1130 DLBCU_LumbarMidDis 0 "default" 1 "off" 2 "on" 3 "invalid" ;
VAL_ 1130 DLBCU_LumbarLowDis 0 "default" 1 "off" 2 "on" 3 "invalid" ;
VAL_ 1130 DLBCU_LumbarDefDis 0 "default" 1 "off" 2 "on" 3 "invalid" ;
VAL_ 2176875011 ECSIVSS_FRCtrlSta 0 "ECS" 1 "ICSC" 2 "Preview ECS" 3 "Preview ECS Limited" ;
VAL_ 2176875011 ECSIVSS_RLCtrlSta 0 "ECS" 1 "ICSC" 2 "Preview ECS" 3 "Preview ECS Limited" ;
VAL_ 2176875011 ECSIVSS_RRCtrlSta 0 "ECS" 1 "ICSC" 2 "Preview ECS" 3 "Preview ECS Limited" ;
VAL_ 1131 DLBCU_BolsterInfDis 0 "default" 1 "off" 2 "on" 3 "invalid" ;
VAL_ 1131 DLBCU_BolsterDefDis 0 "default" 1 "off" 2 "on" 3 "invalid" ;
VAL_ 1128 DPSS_Crc2Val 0 "0x0x0~0xFF:CRCValue" 255 "0x0x0~0xFF:CRCValue" ;
VAL_ 1128 DPSS_AlvCnt2Val 0 "AlvCntValue" 1 "AlvCntValue" 2 "AlvCntValue" 3 "AlvCntValue" 4 "AlvCntValue" 5 "AlvCntValue" 6 "AlvCntValue" 7 "AlvCntValue" 8 "AlvCntValue" 9 "AlvCntValue" 10 "AlvCntValue" 11 "AlvCntValue" 12 "AlvCntValue" 13 "AlvCntValue" 14 "AlvCntValue" 15 "AlvCntValue" ;
VAL_ 1128 DPSS_LumbarUpSw 0 "Default" 1 "Off" 2 "On" 3 "Invalid" ;
VAL_ 1128 DPSS_LumbarMidSw 0 "Default" 1 "Off" 2 "On" 3 "Invalid" ;
VAL_ 1128 DPSS_LumbarLowSw 0 "Default" 1 "Off" 2 "On" 3 "Invalid" ;
VAL_ 1128 DPSS_LumbarDefSw 0 "Default" 1 "Off" 2 "On" 3 "Invalid" ;
VAL_ 1128 DPSS_BolsterInfSw 0 "Default" 1 "Off" 2 "On" 3 "Invalid" ;
VAL_ 1128 DPSS_BolsterDefSw 0 "Default" 1 "Off" 2 "On" 3 "Invalid" ;
VAL_ 1128 DPSS_ActiveSw 0 "Default" 1 "Off" 2 "On" 3 "Invalid" ;
VAL_ 1128 DPSS_CushInfSw 0 "Default" 1 "Off" 2 "On" 3 "Invaild" ;
VAL_ 1128 DPSS_CushDefSw 0 "Default" 1 "Off" 2 "On" 3 "Invalid" ;
VAL_ 2176875009 ECS_Crc3Val 0 "0x0x0~0xFFFF:CRCValue" 65535 "0x0x0~0xFFFF:CRCValue" ;
VAL_ 2176875009 ECS_AlvCnt3Val 0 "0x0x0~0xFF:AlvCntValue" 255 "0x0x0~0xFF:AlvCntValue" ;
VAL_ 1129 DPSS_Crc3Val 0 "0x0x0~0xFF:CRCValue" 255 "0x0x0~0xFF:CRCValue" ;
VAL_ 1129 DPSS_AlvCnt3Val 0 "AlvCntValue" 1 "AlvCntValue" 2 "AlvCntValue" 3 "AlvCntValue" 4 "AlvCntValue" 5 "AlvCntValue" 6 "AlvCntValue" 7 "AlvCntValue" 8 "AlvCntValue" 9 "AlvCntValue" 10 "AlvCntValue" 11 "AlvCntValue" 12 "AlvCntValue" 13 "AlvCntValue" 14 "AlvCntValue" 15 "AlvCntValue" ;
VAL_ 1129 DPSS_SldTch 0 "Default" 1 "Off" 2 "On" 3 "Invalid" ;
VAL_ 1129 DPSS_RclTch 0 "Default" 1 "Off" 2 "On" 3 "Invalid" ;
VAL_ 1129 DPSS_ExtTch 0 "Default" 1 "Off" 2 "On" 3 "Invalid" ;
VAL_ 1129 DPSS_LmbrTch 0 "Default" 1 "Off" 2 "On" 3 "Invalid" ;
VAL_ 1129 DPSS_CushOnOffTch 0 "Default" 1 "Off" 2 "On(Off State)" 3 "On(Mode1 State)" 4 "On(Mode2 State)" 5 "On(Mode3 State)" 6 "Reserved" 7 "Invalid" ;
VAL_ 1129 DPSS_HRestTch 0 "Default" 1 "Off" 2 "On" 3 "Invalid" ;
VAL_ 1129 DPSS_RelaxTch 0 "Default" 1 "Off" 2 "On" 3 "Invalid" ;
VAL_ 1129 DPSS_ThighTch 0 "Default" 1 "Off" 2 "On" 3 "Invalid" ;
VAL_ 1129 DPSS_ExtThighTch 0 "Default" 1 "Off" 2 "On" 3 "Invalid" ;
VAL_ 1129 DPSS_LmbrBolsterTch 0 "Default" 1 "Off" 2 "On" 3 "Invalid" ;
VAL_ 1124 BCM_Crc15Val 0 "0x0x0~0xFF:CRCValue" 255 "0x0x0~0xFF:CRCValue" ;
VAL_ 1124 BCM_AlvCnt15Val 0 "AlvCntValue" 1 "AlvCntValue" 2 "AlvCntValue" 3 "AlvCntValue" 4 "AlvCntValue" 5 "AlvCntValue" 6 "AlvCntValue" 7 "AlvCntValue" 8 "AlvCntValue" 9 "AlvCntValue" 10 "AlvCntValue" 11 "AlvCntValue" 12 "AlvCntValue" 13 "AlvCntValue" 14 "AlvCntValue" 15 "AlvCntValue" ;
VAL_ 1124 Window_DrvrSdWdwActSta 0 "No Action" 1 "Manual Down" 2 "Manual Up" 3 "RLY Stuck/FET Error" 4 "Motor Stop Error" 5 "Auto Down" 6 "Auto Up" 7 "Reverse" 8 "Reserved" 9 "Reserved" 10 "Reserved" 11 "Reserved" 12 "Reserved" 13 "Reserved" 14 "Reserved" 15 "Invalid" ;
VAL_ 1124 Window_AsstSdWdwActSta 0 "No Action" 1 "Manual Down" 2 "Manual Up" 3 "RLY Stuck/FET Error" 4 "Motor Stop Error" 5 "Auto Down" 6 "Auto Up" 7 "Reverse" 8 "Reserved" 9 "Reserved" 10 "Reserved" 11 "Reserved" 12 "Reserved" 13 "Reserved" 14 "Reserved" 15 "Invalid" ;
VAL_ 1124 Window_RrLftWdwActSta 0 "No Action" 1 "Manual Down" 2 "Manual Up" 3 "RLY Stuck/FET Error" 4 "Motor Stop Error" 5 "Auto Down" 6 "Auto Up" 7 "Reverse" 8 "Reserved" 9 "Reserved" 10 "Reserved" 11 "Reserved" 12 "Reserved" 13 "Reserved" 14 "Reserved" 15 "Invalid" ;
VAL_ 1124 Window_RrRtWdwActSta 0 "No Action" 1 "Manual Down" 2 "Manual Up" 3 "RLY Stuck/FET Error" 4 "Motor Stop Error" 5 "Auto Down" 6 "Auto Up" 7 "Reverse" 8 "Reserved" 9 "Reserved" 10 "Reserved" 11 "Reserved" 12 "Reserved" 13 "Reserved" 14 "Reserved" 15 "Invalid" ;
VAL_ 1124 Window_DrvrSdWdwDetailOpnSta 0 "Full Close" 1 "1~30% Open" 2 "31~99% Open" 3 "Full Open" 4 "Reserved" 5 "Reserved" 6 "Reserved" 7 "Invalid" ;
VAL_ 1124 Window_AsstSdWdwDetailOpnSta 0 "Full Close" 1 "1~30% Open" 2 "31~99% Open" 3 "Full Open" 4 "Reserved" 5 "Reserved" 6 "Reserved" 7 "Invalid" ;
VAL_ 1124 Window_DrvrSdWdwErrAntPinch 0 "Calibrated" 1 "De-Calibrated" 2 "Reserved" 3 "Invalid" ;
VAL_ 1124 Window_RrLftWdwDetailOpnSta 0 "Full Close" 1 "1~30% Open" 2 "31~99% Open" 3 "Full Open" 4 "Reserved" 5 "Reserved" 6 "Reserved" 7 "Invalid" ;
VAL_ 1124 Window_RrRtWdwDetailOpnSta 0 "Full Close" 1 "1~30% Open" 2 "31~99% Open" 3 "Full Open" 4 "Reserved" 5 "Reserved" 6 "Reserved" 7 "Invalid" ;
VAL_ 1124 Window_AsstSdWdwErrAntPinch 0 "Calibrated" 1 "De-Calibrated" 2 "Reserved" 3 "Invalid" ;
VAL_ 1124 Window_RrLftWdwErrAntPinch 0 "Calibrated" 1 "De-Calibrated" 2 "Reserved" 3 "Invalid" ;
VAL_ 1124 Window_RrRtWdwErrAntPinch 0 "Calibrated" 1 "De-Calibrated" 2 "Reserved" 3 "Invalid" ;
VAL_ 1124 SunRoof_RrBlindPosSta 0 "BLIND_HALF_OPEN" 1 "BLIND_LESS_THEN_HALF_OPEN" 2 "BLIND_ANTIPINCH_LESS_THAN_HALF_OPEN" 3 "BLIND_FULLY_CLOSE" 4 "BLIND_ANTIPINCH_MORE_THAN_HALF_OPEN" 5 "BLIND_MORE_THAN_HALF_OPEN" 6 "BLIND_FULLY_OPEN" 7 "BLIND_UNINITIALIZED" 8 "Reserved" 9 "Reserved" 10 "Reserved" 11 "Reserved" 12 "Reserved" 13 "Reserved" 14 "Reserved" 15 "invalid" ;
VAL_ 1141 Ast_SHVU_SeatOptSta 0 "Init" 1 "Heater only 2step" 2 "Heater only 3step" 3 "Vent only 2step" 4 "Vent only 3step" 5 "Heater and Vent 2step" 6 "Heater and Vent 3step" 7 "Invalid" ;
VAL_ 1141 Ast_SHVU_HtSwHiIndSta 0 "Off(Initial Value)" 1 "On" 2 "RESERVED" 3 "Error Indicator" ;
VAL_ 1141 Ast_SHVU_HtSwMidIndSta 0 "Off(Initial Value)" 1 "On" 2 "RESERVED" 3 "Error Indicator" ;
VAL_ 1141 Ast_SHVU_HtSwLowIndSta 0 "Off(Initial Value)" 1 "On" 2 "RESERVED" 3 "Error Indicator" ;
VAL_ 1141 Ast_SHVU_VntSwHiIndSta 0 "Off(Initial Value)" 1 "On" 2 "RESERVED" 3 "Error Indicator" ;
VAL_ 1141 Ast_SHVU_VntSwMidIndSta 0 "Off(Initial Value)" 1 "On" 2 "RESERVED" 3 "Error Indicator" ;
VAL_ 1141 Ast_SHVU_VntSwLowIndSta 0 "Off(Initial Value)" 1 "On" 2 "RESERVED" 3 "Error Indicator" ;
VAL_ 1141 Ast_SHVU_HtBlcUSMSta 0 "Default" 1 "Normal" 2 "Back 1" 3 "Back 2" 4 "Back 3" 5 "Cush 1" 6 "Cush 2" 7 "Cush 3" 8 "Reserved" 9 "Reserved" 10 "Reserved" 11 "Reserved" 12 "Reserved" 13 "Reserved" 14 "Reserved" 15 "Invalid" ;
VAL_ 1141 Ast_SHVU_SeatHtOperSta 0 "Init" 1 "RESERVED" 2 "Heater & Vent OFF" 3 "Vent Low" 4 "Vent Mid" 5 "Vent High" 6 "Heater Low" 7 "Heater Mid" 8 "Heater High" 9 "RESERVED" 10 "RESERVED" 11 "RESERVED" 12 "RESERVED" 13 "RESERVED" 14 "RESERVED" 15 "Invalid" ;
VAL_ 1141 Ast_SHVU_HtSwHiIndSta_RHD 0 "Off(Initial Value)" 1 "On" 2 "RESERVED" 3 "Error Indicator" ;
VAL_ 1141 Ast_SHVU_HtSwMidIndSta_RHD 0 "Off(Initial Value)" 1 "On" 2 "RESERVED" 3 "Error Indicator" ;
VAL_ 1141 Ast_SHVU_HtSwLowIndSta_RHD 0 "Off(Initial Value)" 1 "On" 2 "RESERVED" 3 "Error Indicator" ;
VAL_ 1141 Ast_SHVU_VntSwHiIndSta_RHD 0 "Off(Initial Value)" 1 "On" 2 "RESERVED" 3 "Error Indicator" ;
VAL_ 1141 Ast_SHVU_VntSwMidIndSta_RHD 0 "Off(Initial Value)" 1 "On" 2 "RESERVED" 3 "Error Indicator" ;
VAL_ 1141 Ast_SHVU_VntSwLowIndSta_RHD 0 "Off(Initial Value)" 1 "On" 2 "RESERVED" 3 "Error Indicator" ;
VAL_ 2244046850 ADAS_PRK_PDW_SwIndOnReq 0 "Indicator Off" 1 "Indicator On" 2 "Not Used" 3 "Error Indicator" ;
VAL_ 2244046850 PCA_RrEquipChkSta 0 "Default" 1 "Off" 2 "On" 3 "Invalid" ;
VAL_ 2244046850 ADAS_PRK_PDW_OptTyp 0 "None" 1 "PDW-R" 2 "PDW-FR" 3 "PDW-FSR" 4 "PDW-R (w/ 1st Corner Warning)" 5 "PDW-FR (w/ 1st Corner Warning)" 6 "Not Used" 7 "Error Indicator" ;
VAL_ 2244046850 PCA_FrBndryLn 0 "Off (No Display)" 1 "Ready" 2 "Assist" 3 "Error Indicator" ;
VAL_ 2244046850 PCA_RrBndryLn 0 "Off (No Display)" 1 "Ready" 2 "Assist" 3 "Error Indicator" ;
VAL_ 2244046850 PCA_LtBndryLn 0 "Off (No Display)" 1 "Ready" 2 "Assist" 3 "Error Indicator" ;
VAL_ 2244046850 PCA_RtBndryLn 0 "Off (No Display)" 1 "Ready" 2 "Assist" 3 "Error Indicator" ;
VAL_ 2244046850 PCA_WrngPhrs 0 "Off (No Display)" 1 "Warning" 2 "Assist" 3 "Assist Ended" 4 "Brake Hold" 5 "Reserved" 6 "Reserved" 7 "Error Indicator" ;
VAL_ 2244046850 ADAS_PRK_PDW_AutoOn_USM 0 "Default" 1 "Function Off" 2 "Function On" 3 "Invalid" ;
VAL_ 2244046850 PCA_FlrInfoSta 0 "0x0x0~0xFFF:Refer Description" 4095 "0x0x0~0xFFF:Refer Description" ;
VAL_ 2244046850 PCA_FrSdEquipChkSta 0 "Default" 1 "Off" 2 "On" 3 "Invalid" ;
VAL_ 2244046849 ADAS_PRK_Crc1Val 0 "0x0x0~0xFFFF:CRCValue" 65535 "0x0x0~0xFFFF:CRCValue" ;
VAL_ 2244046849 ADAS_PRK_AlvCnt1Val 0 "0x0x0~0xFF:AlvCntValue" 255 "0x0x0~0xFF:AlvCntValue" ;
VAL_ 2244046849 PCA_SysFlrSta 0 "Off (No Display)" 1 "Reserved" 2 "Camera Blockage" 3 "Ultrasonic sensor Blockage" 4 "PCA Failure" 5 "Reserved" 6 "Lidar Blockage" 7 "Error Indicator" ;
VAL_ 2244046849 PCA_ModDis 0 "No Warning" 1 "PCA-R Off" 2 "PCA-R On" 3 "PCA-R Off, PCA-F/S Off" 4 "PCA-R On, PCA-F/S Off" 5 "PCA-R On, PCA-F/S On" 6 "Reserved" 7 "Invalid" ;
VAL_ 2244046849 PCA_HptReq 0 "Haptic Off" 1 "Haptic On" 2 "Reserved" 3 "Invalid" ;
VAL_ 2244046849 PCA_BrkReq 0 "PCA Brake off" 1 "PCA Brake on" 2 "PCA Brake on (hold)" 3 "Error indicator" ;
VAL_ 2244046849 PCA_EpbReq 0 "Apply EPB" 1 "Stand by" 2 "Reserved" 3 "Invalid" ;
VAL_ 2244046849 PU_F_Group7_DrvrAsstFlr10Sta 0 "Not Display" 1 "Failure" 2 "Camera Blockage" 3 "Ultrasonic sensor Blockage" 4 "Reserved" 5 "Reserved" 6 "Lidar Blockage" 7 "Error Indicator" ;
VAL_ 2244046849 ADAS_PRK_PDW_SysFlrSta 0 "No Display" 1 "Unable by Ultrasonic" 2 "PDW Failure" 3 "Error Indicator" ;
VAL_ 1027 Win_ElecChildLkSwOpt 0 "Off" 1 "On" 2 "RESERVED" 3 "Error Indicator" ;
VAL_ 1027 Win_PwrWdwSwTyp 0 "Invalid" 1 "All Manual" 2 "Drv Auto Down" 3 "Drv Safety" 4 "Frt Safety" 5 "All Safety" 6 "RESERVED" 7 "Error Indicator" ;
VAL_ 1027 Win_DrvIMSSwSta 0 "Off" 1 "1" 2 "2" 3 "3(Smart)" 4 "Set(Passenger Seat)" 5 "RESERVED" 6 "RESERVED" 7 "Error Indicator" ;
VAL_ 1027 Win_DrvPwrWdwSwSta 0 "Off" 1 "Manual Up" 2 "Manual Down" 3 "Auto Up" 4 "Auto Down" 5 "Stuck" 6 "RESERVED" 7 "Error Indicator" ;
VAL_ 1027 Win_AsstPwrWdwSwSta 0 "Off" 1 "Manual Up" 2 "Manual Down" 3 "Auto Up" 4 "Auto Down" 5 "Stuck" 6 "RESERVED" 7 "Error Indicator" ;
VAL_ 1027 Win_CtrlDrLkSwSta 0 "Off" 1 "On" 2 "RESERVED" 3 "Error Indicator" ;
VAL_ 1027 Win_RrLftPwrWdwSwSta 0 "Off" 1 "Manual Up" 2 "Manual Down" 3 "Auto Up" 4 "Auto Down" 5 "Stuck" 6 "RESERVED" 7 "Error Indicator" ;
VAL_ 1027 Win_RrRtPwrWdwSwSta 0 "Off" 1 "Manual Up" 2 "Manual Down" 3 "Auto Up" 4 "Auto Down" 5 "Stuck" 6 "RESERVED" 7 "Error Indicator" ;
VAL_ 1027 Win_CtrlDrUnLkSwSta 0 "Off" 1 "On" 2 "RESERVED" 3 "Error Indicator" ;
VAL_ 1027 Win_PwrWdwLkSwSta 0 "Off" 1 "On" 2 "RESERVED" 3 "Error Indicator" ;
VAL_ 1027 Win_RrCrtSwSta 0 "Off" 1 "On" 2 "RESERVED" 3 "Error Indicator" ;
VAL_ 1029 ICU_Crc12Val 0 "0x0x0~0xFF:CRCValue" 255 "0x0x0~0xFF:CRCValue" ;
VAL_ 1029 Warn_ChaDrSwRrSta 0 "Default" 1 "Close" 2 "Open" 3 "Error Indicator" ;
VAL_ 1029 ICU_AlvCnt12Val 0 "AlvCntValue" 1 "AlvCntValue" 2 "AlvCntValue" 3 "AlvCntValue" 4 "AlvCntValue" 5 "AlvCntValue" 6 "AlvCntValue" 7 "AlvCntValue" 8 "AlvCntValue" 9 "AlvCntValue" 10 "AlvCntValue" 11 "AlvCntValue" 12 "AlvCntValue" 13 "AlvCntValue" 14 "AlvCntValue" 15 "AlvCntValue" ;
VAL_ 1029 DoorLock_CtrlDrLkSwSta_ICU 0 "Off" 1 "On(Lock On)" 2 "Not Used" 3 "Error Indicator" ;
VAL_ 1029 DoorLock_CtrlDrUnLkSwSta_ICU 0 "Off" 1 "On(Unlock On)" 2 "Not Used" 3 "Error Indicator" ;
VAL_ 1029 DoorLock_CtrlDrLkUnLkSwSta_ICU 0 "Off" 1 "On" 2 "Not Used" 3 "Error Indicator" ;
VAL_ 1029 HEV_IGN3On_Req 0 "Default (IG3 Off)" 1 "IG3 On (by BMS)" 2 "IG3 On (by IG1 On)" 3 "IG3 On (by AVNT)" ;
VAL_ 1029 AutoLtOpt 0 "Not Applied" 1 "Applied" 2 "Reserved" 3 "Reserved" ;
VAL_ 1029 ICU_IGN3On_ReqState_New 0 "OFF" 1 "IGN1 On" 2 "IBS On" 3 "IBS & IGN1 On" 4 "CCU(HU) On" 5 "CCU(HU) & IGN1 On" 6 "CCU(HU) & IBS On" 7 "CCU(HU) & IBS & IGN1 On" 8 "VCU On" 9 "VCU & IGN1 On" 10 "VCU & IBS On" 11 "VCU & IBS & IGN1 On" 12 "VCU & CCU(HU) On" 13 "VCU & CCU(HU) & IGN1 On" 14 "VCU & CCU(HU) & IBS On" 15 "VCU & CCU(HU) & IBS & IGN1 On" 16 "VCMS On" 17 "VCMS & IGN1 On" 18 "VCMS & IBS On" 19 "VCMS & IBS & IGN1 On" 20 "VCMS & CCU(HU) On" 21 "VCMS & CCU(HU) & IGN1 On" 22 "VCMS & CCU(HU) & IBS On" 23 "VCMS & CCU(HU) & IBS & IGN1 On" 24 "VCMS & VCU On" 25 "VCMS & VCU & IGN1 On" 26 "VCMS & VCU & IBS On" 27 "VCMS & VCU & IBS & IGN1 On" 28 "VCMS & VCU & CCU(HU) On" 29 "VCMS & VCU & CCU(HU) & IGN1 On" 30 "VCMS & VCU & CCU(HU) & IBS On" 31 "VCMS & VCU & CCU(HU) & IBS & IGN1 On" 32 "DATC on" 33 "DATC & IGN1 On" 34 "DATC & IBS On" 35 "DATC & IBS & IGN1 On" 36 "DATC & CCU(HU) On" 37 "DATC & CCU(HU) & IGN1 On" 38 "DATC & CCU(HU) & IBS On" 39 "DATC & CCU(HU) & IBS & IGN1 On" 40 "DATC & VCU On" 41 "DATC & VCU & IGN1 On" 42 "DATC & VCU & IBS On" 43 "DATC & VCU & IBS & IGN1 On" 44 "DATC & VCU & CCU(HU) On" 45 "DATC & VCU & CCU(HU) & IGN1 On" 46 "DATC & VCU & CCU(HU) & IBS On" 47 "DATC & VCU & CCU(HU) & IBS & IGN1 On" 48 "DATC & VCMS On" 49 "DATC & VCMS & IGN1 On" 50 "DATC & VCMS & IBS On" 51 "DATC & VCMS & IBS & IGN1 On" 52 "DATC & VCMS & CCU(HU) On" 53 "DATC & VCMS & CCU(HU) and IGN1 On" 54 "DATC & VCMS & CCU(HU) & IBS On" 55 "DATC & VCMS & CCU(HU) & IBS & IGN1 On" 56 "DATC & VCMS & VCU On" 57 "DATC & VCMS & VCU & IGN1 On" 58 "DATC & VCMS & VCU & IBS On" 59 "DATC & VCMS & VCU & IBS & IGN1 On" 60 "DATC & VCMS & VCU & CCU(HU) On" 61 "DATC & VCMS & VCU & CCU(HU) & IGN1 On" 62 "DATC & VCMS & VCU & CCU(HU) & IBS On" 63 "DATC & VCMS & VCU & CCU(HU) & IBS & IGN1 On" 64 "CC on" 65 "CC & IGN1 On" 66 "CC & IBS On" 67 "CC & IBS & IGN1 On" 68 "CC & CCU(HU) On" 69 "CC & CCU(HU) & IGN1 On" 70 "CC & CCU(HU) & IBS On" 71 "CC & CCU(HU) & IBS & IGN1 On" 72 "CC & VCU On" 73 "CC & VCU & IGN1 On" 74 "CC & VCU & IBS On" 75 "CC & VCU & IBS & IGN1 On" 76 "CC & VCU & CCU(HU) On" 77 "CC & VCU & CCU(HU) & IGN1 On" 78 "CC & VCU & CCU(HU) & IBS On" 79 "CC & VCU & CCU(HU) & IBS & IGN1 On" 80 "CC & VCMS On" 81 "CC & VCMS & IGN1 On" 82 "CC & VCMS & IBS On" 83 "CC & VCMS & IBS & IGN1 On" 84 "CC & VCMS & CCU(HU) On" 85 "CC & VCMS & CCU(HU) & IGN1 On" 86 "CC & VCMS & CCU(HU) & IBS On" 87 "CC & VCMS & CCU(HU) & IBS & IGN1 On" 88 "CC & VCMS & VCU On" 89 "CC & VCMS & VCU & IGN1 On" 90 "CC & VCMS & VCU & IBS On" 91 "CC & VCMS & VCU & IBS & IGN1 On" 92 "CC & VCMS & VCU & CCU(HU) On" 93 "CC & VCMS & VCU & CCU(HU) & IGN1 On" 94 "CC & VCMS & VCU & CCU(HU) & IBS On" 95 "CC & VCMS & VCU & CCU(HU) & IBS & IGN1 On" 96 "CC & DATC on" 97 "CC & DATC & IGN1 On" 98 "CC & DATC & IBS On" 99 "CC & DATC & IBS & IGN1 On" 100 "CC & DATC & CCU(HU) On" 101 "CC & DATC & CCU(HU) & IGN1 On" 102 "CC & DATC & CCU(HU) & IBS On" 103 "CC & DATC & CCU(HU) & IBS & IGN1 On" 104 "CC & DATC & VCU On" 105 "CC & DATC & VCU & IGN1 On" 106 "CC & DATC & VCU & IBS On" 107 "CC & DATC & VCU & IBS & IGN1 On" 108 "CC & DATC & VCU & CCU(HU) On" 109 "CC & DATC & VCU & CCU(HU) & IGN1 On" 110 "CC & DATC & VCU & CCU(HU) & IBS" 111 "CC & DATC & VCU & CCU(HU) & IBS & IGN1 On" 112 "CC & DATC & VCMS On" 113 "CC & DATC & VCMS & IGN1 On" 114 "CC & DATC & VCMS & IBS On" 115 "CC & DATC & VCMS & IBS & IGN1 On" 116 "CC & DATC & VCMS & CCU(HU) On" 117 "CC & DATC & VCMS & CCU(HU) & IGN1 On" 118 "CC & DATC & VCMS & CCU(HU) & IBS On" 119 "CC & DATC & VCMS & CCU(HU) & IBS & IGN1 On" 120 "CC & DATC & VCMS & VCU On" 121 "CC & DATC & VCMS & VCU & IGN1 On" 122 "CC & DATC & VCMS & VCU & IBS On" 123 "CC & DATC & VCMS & VCU & IBS & IGN1 On" 124 "CC & DATC & VCMS & VCU & CCU(HU) On" 125 "CC & DATC & VCMS & VCU & CCU(HU) & IGN1 On" 126 "CC & DATC & VCMS & VCU & CCU(HU) & IBS On" 127 "CC & DATC & VCMS & VCU & CCU(HU) & IBS & IGN1 On" 128 "0x80~0xFF:RESERVED" 255 "0x80~0xFF:RESERVED" ;
VAL_ 1029 ICU_BattMngAlert 0 "No Warning(Default)" 1 "Hazard On" 2 "Tail On" 3 "Hazard/Tail On" 4 "0x4~0xFE:RESERVED" 254 "0x4~0xFE:RESERVED" 255 "Invalid" ;
VAL_ 1029 HLmpLoHiOptLtSrcTyp 0 "Not Applied" 1 "2 Light MFR Bulb" 2 "4 Light Bulb" 3 "4 Light Led Ldm" 4 "Bi-Function Bulb" 5 "Bi-Function Led Ldm" 6 "Reserved" 7 "Reserved" ;
VAL_ 1029 PDC_PwrOnModePowerReq 0 "Default" 1 "Request On" 2 "RESERVED" 3 "Error" ;
VAL_ 1029 IGN3State_By_Bat 0 "Off" 1 "On" 2 "RESERVED" 3 "RESERVED" ;
VAL_ 1029 Warn_ChaDrSwFrtSta 0 "Default" 1 "Close" 2 "Open" 3 "Error Indicator" ;
VAL_ 1030 APSM_SWVerMajor1 0 "0x0x0~0x7F:ASCII Code Value (HEX)" 127 "0x0x0~0x7F:ASCII Code Value (HEX)" ;
VAL_ 1030 APSM_SWVerMinor1 0 "0x0x0~0x7F:ASCII Code Value (HEX)" 127 "0x0x0~0x7F:ASCII Code Value (HEX)" ;
VAL_ 1030 APSM_SWVerMinor2 0 "0x0x0~0x7F:ASCII Code Value (HEX)" 127 "0x0x0~0x7F:ASCII Code Value (HEX)" ;
VAL_ 1030 APSM_AstSeatPos_Sta 0 "Default" 1 "Memory1" 2 "Memory2" 3 "Memory3" 4 "Not Used" 5 "Not Used" 6 "Not Used" 7 "Any Postion" ;
VAL_ 1030 APSM_AstSeatPosRclnLmt_Sta 0 "Default" 1 "Recline Fwd Limit" 2 "Recline Bwd Limit" 3 "Not Initialized" ;
VAL_ 1030 APSM_AstSeatPosSldLmt_Sta 0 "Default" 1 "Slide Fwd Limit" 2 "Slide Bwd Limit" 3 "Not Initialized" ;
VAL_ 1031 APSM_RearModeEnable 0 "Disable" 1 "Enable" 2 "Not Used" 3 "Error" ;
VAL_ 1031 APSM_SeatPosPlyBck_Sta 0 "Default" 1 "Moving" 2 "Moving Finish" 3 "Moving Not Finish" 4 "Not Used" 5 "Not Used" 6 "Stop" 7 "Not Used" ;
VAL_ 1031 APSM_AstStEsyAcsUSMSta 0 "Default Value" 1 "Off (Disable)" 2 "50mmOn (Enable)" 3 "75mmOn (Enable)" 4 "Reserved" 5 "Reserved" 6 "Reserved" 7 "Invalid" ;
VAL_ 1031 APSM_ReturnModeState 0 "Off" 1 "Stop" 2 "Moving" 3 "Finish" 4 "Only Rear" 5 "Reserved" 6 "Reserved" 7 "Invalid" ;
VAL_ 1031 APSM_RelaxModeState 0 "Off" 1 "Stop" 2 "Moving" 3 "Finish" 4 "Only Rear" 5 "Reserved" 6 "Reserved" 7 "Invalid" ;
VAL_ 1031 APSM_WalkInEnable 0 "Disable" 1 "Enable" 2 "Not Used" 3 "Error" ;
VAL_ 1031 APSM_LimSetSta 0 "Default" 1 "Initialized" 2 "Not Initialized" 3 "Reserved" ;
VAL_ 1031 APSM_FootRest_Opt 0 "Default" 1 "Off" 2 "On(FootRest OPT)" 3 "Ivalid" ;
VAL_ 1031 APSM_RSE_Opt 0 "Default" 1 "Off" 2 "On(RSE OPT)" 3 "Ivalid" ;
VAL_ 1048 ICU_Crc8Val 0 "0x0x0~0xFF:CRCValue" 255 "0x0x0~0xFF:CRCValue" ;
VAL_ 1048 ICU_AlvCnt8Val 0 "AlvCntValue" 1 "AlvCntValue" 2 "AlvCntValue" 3 "AlvCntValue" 4 "AlvCntValue" 5 "AlvCntValue" 6 "AlvCntValue" 7 "AlvCntValue" 8 "AlvCntValue" 9 "AlvCntValue" 10 "AlvCntValue" 11 "AlvCntValue" 12 "AlvCntValue" 13 "AlvCntValue" 14 "AlvCntValue" 15 "AlvCntValue" ;
VAL_ 1048 DriveTypeOption 0 "Left Handle Drive Type" 1 "Right Handle Drive Type" 2 "RESERVED" 3 "Error Indicator" ;
VAL_ 1048 Warn_RrLftSBRMATSwSta 0 "Off (UnSeated)" 1 "On (Seated)" 2 "RESERVED" 3 "Error Indicator" ;
VAL_ 1048 Warn_RrRhtSBRMATSwSta 0 "Off (UnSeated)" 1 "On (Seated)" 2 "RESERVED" 3 "Error Indicator" ;
VAL_ 1048 Lamp_FootLampOnReq 0 "Off" 1 "On" 2 "Dim Out" 3 "Error Indicator" ;
VAL_ 1048 Lamp_MoodLampOnReq 0 "0%" 1 "FadeIn" 2 "MoodBrightPercent" 3 "FadeOut" 4 "100%" 5 "RESERVED" 6 "RESERVED" 7 "RESERVED" ;
VAL_ 1048 ICU_PowerAutoCutModSta 0 "Factory Mode (default)" 1 "Dealer Mode" 2 "Customer Mode" 3 "Error Indicator" ;
VAL_ 1048 ICU_SoCBattStaMsgReq 0 "Default" 1 "Alert" 2 "Warning" 3 "Invalid" ;
VAL_ 1048 C_1stCTRSeatBeltSW 0 "Unbelted" 1 "Belted" ;
VAL_ 1048 Brake_SwSta_ICU 0 "Off" 1 "On" 2 "RESERVED" 3 "RESERVED" ;
VAL_ 1048 C_1stCTRSBRMatSw 0 "Off (UnSeated)" 1 "On (Seated)" ;
VAL_ 1048 C_3rdRCSeatBeltSW 0 "Unbelted" 1 "Belted" ;
VAL_ 1048 C_3rdRRSBRMatSw 0 "Off (UnSeated)" 1 "On (Seated)" ;
VAL_ 1048 C_3rdRLSBRMatSw 0 "Off (UnSeated)" 1 "On (Seated)" ;
VAL_ 1048 C_3rdRRSeatBeltSW 0 "Unbelted" 1 "Belted" ;
VAL_ 1048 C_3rdRLSeatBeltSW 0 "Unbelted" 1 "Belted" ;
VAL_ 1048 HSWS_SysWrngSta_ICU 0 "Normal" 1 "System Fail" 2 "RESERVED" 3 "Invalid" ;
VAL_ 1050 BCM_Crc7Val 0 "0x0x0~0xFF:CRCValue" 255 "0x0x0~0xFF:CRCValue" ;
VAL_ 1050 BCM_AlvCnt7Val 0 "AlvCntValue" 1 "AlvCntValue" 2 "AlvCntValue" 3 "AlvCntValue" 4 "AlvCntValue" 5 "AlvCntValue" 6 "AlvCntValue" 7 "AlvCntValue" 8 "AlvCntValue" 9 "AlvCntValue" 10 "AlvCntValue" 11 "AlvCntValue" 12 "AlvCntValue" 13 "AlvCntValue" 14 "AlvCntValue" 15 "AlvCntValue" ;
VAL_ 1050 Lamp_HiPrioHzrdReq 0 "Off" 1 "High On" 2 "High Inactive" 3 "Reserved" 4 "Reserved" 5 "Reseved" 6 "Not Used" 7 "Error Indicator" ;
VAL_ 1050 Lamp_LoPrioHzrdReq 0 "Off" 1 "Low On" 2 "Low Inactive" 3 "Reserved" 4 "Reserved" 5 "Reseved" 6 "Not Used" 7 "Error Indicator" ;
VAL_ 1050 Lamp_IntTailLmpOnReq 0 "Off" 1 "On" 2 "Not Used" 3 "Error Indicator" ;
VAL_ 1050 Lamp_ExtrnlTailLmpOnReq 0 "Off" 1 "On" 2 "Not Used" 3 "Error Indicator" ;
VAL_ 1050 Lamp_HdLmpLoOnReq 0 "Off" 1 "On" 2 "Not Used" 3 "Error Indicator" ;
VAL_ 1050 Lamp_HdLmpHiOnReq 0 "Off" 1 "On" 2 "Not Used" 3 "Error Indicator" ;
VAL_ 1050 Lamp_AvTailLmpSta 0 "Off" 1 "On" 2 "Not Used" 3 "Error Indicator" ;
VAL_ 1050 Lamp_BckUpLmpCmd 0 "Off" 1 "On" 2 "Not Used" 3 "Error Indicator" ;
VAL_ 1050 Lamp_DrlOnReq 0 "Off" 1 "On" 2 "Not Used" 3 "Error Indicator" ;
VAL_ 1050 USM_IllAlwaysOnwithPSTNSta 0 "Default" 1 "Off" 2 "IllAlwaysOn" 3 "IllAlwaysOnwithPSTN" 4 "RESERVED" 5 "RESERVED" 6 "RESERVED" 7 "Invalid" ;
VAL_ 1052 BCM_Crc9Val 0 "0x0x0~0xFF:CRCValue" 255 "0x0x0~0xFF:CRCValue" ;
VAL_ 1052 BCM_AlvCnt9Val 0 "AlvCntValue" 1 "AlvCntValue" 2 "AlvCntValue" 3 "AlvCntValue" 4 "AlvCntValue" 5 "AlvCntValue" 6 "AlvCntValue" 7 "AlvCntValue" 8 "AlvCntValue" 9 "AlvCntValue" 10 "AlvCntValue" 11 "AlvCntValue" 12 "AlvCntValue" 13 "AlvCntValue" 14 "AlvCntValue" 15 "AlvCntValue" ;
VAL_ 1052 Lamp_AutoLtSnsrNightSta 0 "Off" 1 "Night" 2 "Not Used" 3 "Error Indicator" ;
VAL_ 1052 Lamp_VendorInfo 0 "Not Used" 1 "TRW(BCS)" 2 "HELLA" 3 "Not Used" 4 "Not Used" 5 "Not Used" 6 "Not Used" 7 "Error Indicator" ;
VAL_ 1052 Lamp_AutoLtSnsrHorVal 0 "0x0x0~0x3FE:Light Sensor Value" 1022 "0x0x0~0x3FE:Light Sensor Value" 1023 "Invalid" ;
VAL_ 1052 IBU_HDPSpprtSWVer 0 "Not Support (Init)" 1 "SW Version" 2 "SW Version" 3 "SW Version" 4 "SW Version" 5 "SW Version" 6 "SW Version" 7 "SW Version" 8 "SW Version" 9 "SW Version" 10 "SW Version" 11 "SW Version" 12 "SW Version" 13 "SW Version" 14 "SW Version" 15 "SW Version" 16 "SW Version" 17 "SW Version" 18 "SW Version" 19 "SW Version" 20 "SW Version" 21 "SW Version" 22 "SW Version" 23 "SW Version" 24 "SW Version" 25 "SW Version" 26 "SW Version" 27 "SW Version" 28 "SW Version" 29 "SW Version" 30 "SW Version" 31 "SW Version" 32 "SW Version" 33 "SW Version" 34 "SW Version" 35 "SW Version" 36 "SW Version" 37 "SW Version" 38 "SW Version" 39 "SW Version" 40 "SW Version" 41 "SW Version" 42 "SW Version" 43 "SW Version" 44 "SW Version" 45 "SW Version" 46 "SW Version" 47 "SW Version" 48 "SW Version" 49 "SW Version" 50 "SW Version" 51 "SW Version" 52 "SW Version" 53 "SW Version" 54 "SW Version" 55 "SW Version" 56 "SW Version" 57 "SW Version" 58 "SW Version" 59 "SW Version" 60 "SW Version" 61 "SW Version" 62 "SW Version" 63 "Error Indicator" ;
VAL_ 1052 IBU_HDPSpprtRdy 0 "Normal" 1 "ADAS Message Not Recognized" 2 "RESERVED" 3 "RESERVED" ;
VAL_ 1052 Wiper_RainAmount 0 "0x0x0~0x96:PH=0.1*HEX(mm/Hr)" 150 "0x0x0~0x96:PH=0.1*HEX(mm/Hr)" 151 "0x97~0xFE:RESERVED" 254 "0x97~0xFE:RESERVED" 255 "Invalid" ;
VAL_ 1041 ICU_Crc2Val 0 "0x0x0~0xFF:CRCValue" 255 "0x0x0~0xFF:CRCValue" ;
VAL_ 1041 ICU_MtGearPosRSta 0 "Off" 1 "On" 2 "RESERVED" 3 "RESERVED" ;
VAL_ 1041 ICU_AlvCnt2Val 0 "AlvCntValue" 1 "AlvCntValue" 2 "AlvCntValue" 3 "AlvCntValue" 4 "AlvCntValue" 5 "AlvCntValue" 6 "AlvCntValue" 7 "AlvCntValue" 8 "AlvCntValue" 9 "AlvCntValue" 10 "AlvCntValue" 11 "AlvCntValue" 12 "AlvCntValue" 13 "AlvCntValue" 14 "AlvCntValue" 15 "AlvCntValue" ;
VAL_ 1041 Autocut_DlvryModSta 0 "Before Delivery(Welcome Off)" 1 "After Delivery(Welcome On)" 2 "Not Used" 3 "Error Indicator" ;
VAL_ 1041 DoorLock_AsstDrUnLkSta 0 "Lock" 1 "Unlock" 2 "Not Used" 3 "Error Indicator" ;
VAL_ 1041 Warn_DrvDrSwSta 0 "Close" 1 "Open" 2 "Not Used" 3 "Error Indicator" ;
VAL_ 1041 DoorLock_DrvKeyUnLkSwSta 0 "Off" 1 "Unlock" 2 "Not Used" 3 "Error Indicator" ;
VAL_ 1041 DoorLock_RrLftDrUnLkSta 0 "Lock" 1 "Unlock" 2 "Not Used" 3 "Error Indicator" ;
VAL_ 1041 DoorLock_RrRtDrUnLkSta 0 "Lock" 1 "Unlock" 2 "Not Used" 3 "Error Indicator" ;
VAL_ 1041 Warn_AsstDrSwSta 0 "Close" 1 "Open" 2 "Not Used" 3 "Error Indicator" ;
VAL_ 1041 Warn_AsstStBltSwSta 0 "Unbelted" 1 "Belted" 2 "Not Used" 3 "Error Indicator" ;
VAL_ 1041 Warn_BrkFldSwSta 0 "Off" 1 "On" 2 "Not Used" 3 "Error Indicator" ;
VAL_ 1041 DoorLock_DrvKeyLkSwSta 0 "Off" 1 "Lock" 2 "Not Used" 3 "Error Indicator" ;
VAL_ 1041 Warn_DrvStBltSwSta 0 "Unbelted" 1 "Belted" 2 "Not Used" 3 "Error Indicator" ;
VAL_ 1041 Warn_HoodSwSta 0 "Off" 1 "On" 2 "Not Used" 3 "Error Indicator" ;
VAL_ 1041 Warn_PassStOccSta 0 "Off (UnSeated)" 1 "On (Seated)" 2 "Not Used" 3 "Error Indicator" ;
VAL_ 1041 Warn_PrkngBrkSwSta 0 "Off" 1 "On" 2 "Not Used" 3 "Error Indicator" ;
VAL_ 1041 Warn_RrCtrStBltSwSta 0 "Unbelted" 1 "Belted" 2 "Not Used" 3 "Error Indicator" ;
VAL_ 1041 Warn_RrLftDrSwSta 0 "Close" 1 "Open" 2 "Not Used" 3 "Error Indicator" ;
VAL_ 1041 Warn_RrLftStBltSwSta 0 "Unbelted" 1 "Belted" 2 "Not Used" 3 "Error Indicator" ;
VAL_ 1041 Warn_RrRtDrSwSta 0 "Close" 1 "Open" 2 "Not Used" 3 "Error Indicator" ;
VAL_ 1041 Warn_RrRtStBltSwSta 0 "Unbelted" 1 "Belted" 2 "Not Used" 3 "Error Indicator" ;
VAL_ 1041 Warn_HoodSwMemorySta 0 "No event" 1 "hood_open_close" 2 "RESERVED" 3 "RESERVED" ;
VAL_ 1041 Warn_WshrFldSwSta 0 "Off" 1 "On" 2 "RESERVED" 3 "RESERVED" ;
VAL_ 1041 ICU_Haptic_OPT 0 "Default" 1 "No option(None Haptic Option)" 2 "Option" 3 "Invalid" ;
VAL_ 1040 ICU_Crc10Val 0 "0x0x0~0xFF:CRCValue" 255 "0x0x0~0xFF:CRCValue" ;
VAL_ 1040 BmsFailWarning 0 "Normal(Default)" 1 "1st warning" 2 "2nd warning" 3 "SMS warning" ;
VAL_ 1040 ICU_AlvCnt10Val 0 "AlvCntValue" 1 "AlvCntValue" 2 "AlvCntValue" 3 "AlvCntValue" 4 "AlvCntValue" 5 "AlvCntValue" 6 "AlvCntValue" 7 "AlvCntValue" 8 "AlvCntValue" 9 "AlvCntValue" 10 "AlvCntValue" 11 "AlvCntValue" 12 "AlvCntValue" 13 "AlvCntValue" 14 "AlvCntValue" 15 "AlvCntValue" ;
VAL_ 1040 ICU_BS2SoC 0 "0x0x00~0x64:0% ~ 100 %" 100 "0x0x00~0x64:0% ~ 100 %" 101 "0x65~0xFE:Invalid" 254 "0x65~0xFE:Invalid" 255 "Error" ;
VAL_ 1040 ICU_BS2NCap 0 "0x0x00~0xFA:0Ah ~ 250Ah" 250 "0x0x00~0xFA:0Ah ~ 250Ah" 251 "Invalid" 252 "Invalid" 253 "Invalid" 254 "Invalid" 255 "Error" ;
VAL_ 1040 ICU_BS2OpnCirVol 0 "0x0x000~0xFA0:10.000V ~ 14.000V" 4000 "0x0x000~0xFA0:10.000V ~ 14.000V" 4001 "Invailid" 4002 "Invailid" 4003 "Invailid" 4004 "Invailid" 4005 "Invailid" 4006 "Invailid" 4007 "Invailid" 4008 "Invailid" 4009 "Invailid" 4010 "Invailid" 4011 "Invailid" 4012 "Invailid" 4013 "Invailid" 4014 "Invailid" 4015 "Invailid" 4016 "Invailid" 4017 "Invailid" 4018 "Invailid" 4019 "Invailid" 4020 "Invailid" 4021 "Invailid" 4022 "Invailid" 4023 "Invailid" 4024 "Invailid" 4025 "Invailid" 4026 "Invailid" 4027 "Invailid" 4028 "Invailid" 4029 "Invailid" 4030 "Invailid" 4031 "Invailid" 4032 "Invailid" 4033 "Invailid" 4034 "Invailid" 4035 "Invailid" 4036 "Invailid" 4037 "Invailid" 4038 "Invailid" 4039 "Invailid" 4040 "Invailid" 4041 "Invailid" 4042 "Invailid" 4043 "Invailid" 4044 "Invailid" 4045 "Invailid" 4046 "Invailid" 4047 "Invailid" 4048 "Invailid" 4049 "Invailid" 4050 "Invailid" 4051 "Invailid" 4052 "Invailid" 4053 "Invailid" 4054 "Invailid" 4055 "Invailid" 4056 "Invailid" 4057 "Invailid" 4058 "Invailid" 4059 "Invailid" 4060 "Invailid" 4061 "Invailid" 4062 "Invailid" 4063 "Invailid" 4064 "Invailid" 4065 "Invailid" 4066 "Invailid" 4067 "Invailid" 4068 "Invailid" 4069 "Invailid" 4070 "Invailid" 4071 "Invailid" 4072 "Invailid" 4073 "Invailid" 4074 "Invailid" 4075 "Invailid" 4076 "Invailid" 4077 "Invailid" 4078 "Invailid" 4079 "Invailid" 4080 "Invailid" 4081 "Invailid" 4082 "Invailid" 4083 "Invailid" 4084 "Invailid" 4085 "Invailid" 4086 "Invailid" 4087 "Invailid" 4088 "Invailid" 4089 "Invailid" 4090 "Invailid" 4091 "Invailid" 4092 "Invailid" 4093 "Invailid" 4094 "Invailid" 4095 "Error" ;
VAL_ 1040 ICU_BS2_FSOC 0 "valid" 1 "invalid" ;
VAL_ 1040 ICU_BS2_FSOH 0 "valid" 1 "invalid" ;
VAL_ 1040 ICU_BS2_FSOF 0 "valid" 1 "invalid" ;
VAL_ 1040 ICU_BS2_FQSTAT 0 "valid" 1 "invalid" ;
VAL_ 1040 ICU_BS2SoH 0 "0x0x00~0x64:0% ~ 100 %" 100 "0x0x00~0x64:0% ~ 100 %" 101 "0x65~0xFE:Invalid" 254 "0x65~0xFE:Invalid" 255 "Error" ;
VAL_ 1040 ICU_BS2SoF 0 "0x0x00~0xF0:0.00V ~ 12.00V" 240 "0x0x00~0xF0:0.00V ~ 12.00V" 241 "Invalid" 242 "Invalid" 243 "Invalid" 244 "Invalid" 245 "Invalid" 246 "Invalid" 247 "Invalid" 248 "Invalid" 249 "Invalid" 250 "Invalid" 251 "Invalid" 252 "Invalid" 253 "Invalid" 254 "Invalid" 255 "Error" ;
VAL_ 95 CF_AVN_MdLpBttmRedNvalueSet 0 "0x0x000~0x0FF:Red Color 0~255 (User selection)" 255 "0x0x000~0x0FF:Red Color 0~255 (User selection)" 256 "0x100~0x1FF:Red Color 0~255 (Expert Recommendation)" 511 "0x100~0x1FF:Red Color 0~255 (Expert Recommendation)" 512 "Default" 1023 "Invalid" ;
VAL_ 95 CF_AVN_MdLpBttmGreenNvalueSet 0 "0x0x000~0x0FF:0~255 (User selection)" 255 "0x0x000~0x0FF:0~255 (User selection)" 256 "0x100~0x1FF:0~255 (Expert Recommendation)" 511 "0x100~0x1FF:0~255 (Expert Recommendation)" 512 "Default" 1023 "Invalid" ;
VAL_ 95 CF_AVN_MdLpBttmBlueNvalueSet 0 "0x0x000~0x0FF:0~255 (User Selection)" 255 "0x0x000~0x0FF:0~255 (User Selection)" 256 "0x100~0x1FF:0~255 (Expert Recommendation)" 511 "0x100~0x1FF:0~255 (Expert Recommendation)" 512 "Default" 1023 "Invalid" ;
VAL_ 95 CF_AVN_MdLpSpdModNvalueSet 0 "Default" 1 "Off" 2 "On" 3 "Invalid" ;
VAL_ 95 CF_AVN_MdLpColorModNvalueSet 0 "Default" 1 "Single" 2 "Multi" 3 "Invalid" ;
VAL_ 95 CF_AVN_AIVoiceModNvalueSet 0 "Default" 1 "AI Voice Start" 2 "User Response" 3 "User No Response" 4 "Processing" 5 "AI Voice Response" 6 "AI Voice End" 7 "Invalid" ;
VAL_ 95 CF_AVN_AIVoiceMicModNvalue 0 "Default" 1 "MiCModLVL 1" 16 "MiCModLVL 16" 17 "MiCModLVL 17" 18 "MiCModLVL 18" 19 "MiCModLVL 19" 20 "MiCModLVL 20" 21 "MiCModLVL 21" 22 "MiCModLVL 22" 23 "MiCModLVL 23" 24 "MiCModLVL 24" 25 "MiCModLVL 25" 26 "MiCModLVL 26" 27 "MiCModLVL 27" 28 "MiCModLVL 28" 29 "MiCModLVL 29" 30 "MiCModLVL 30" 31 "MiCModLVL 31" 2 "MiCModLVL 2" 32 "MiCModLVL 32" 33 "MiCModLVL 33" 34 "MiCModLVL 34" 35 "MiCModLVL 35" 36 "MiCModLVL 36" 37 "MiCModLVL 37" 38 "MiCModLVL 38" 39 "MiCModLVL 39" 40 "MiCModLVL 40" 41 "MiCModLVL 41" 42 "MiCModLVL 42" 43 "MiCModLVL 43" 44 "MiCModLVL 44" 45 "MiCModLVL 45" 46 "MiCModLVL 46" 47 "MiCModLVL 47" 3 "MiCModLVL 3" 48 "MiCModLVL 48" 49 "MiCModLVL 49" 50 "MiCModLVL 50" 51 "MiCModLVL 51" 52 "MiCModLVL 52" 53 "MiCModLVL 53" 54 "MiCModLVL 54" 55 "MiCModLVL 55" 56 "MiCModLVL 56" 57 "MiCModLVL 57" 58 "MiCModLVL 58" 59 "MiCModLVL 59" 60 "MiCModLVL 60" 61 "MiCModLVL 61" 62 "MiCModLVL 62" 63 "Invalid" 4 "MiCModLVL 4" 5 "MiCModLVL 5" 6 "MiCModLVL 6" 7 "MiCModLVL 7" 8 "MiCModLVL 8" 9 "MiCModLVL 9" 10 "MiCModLVL 10" 11 "MiCModLVL 11" 12 "MiCModLVL 12" 13 "MiCModLVL 13" 14 "MiCModLVL 14" 15 "MiCModLVL 15" ;
VAL_ 95 CF_AVN_AIVoiceTTSModNvalue 0 "Default" 1 "TTSModLVL 1" 16 "TTSModLVL 16" 17 "TTSModLVL 17" 18 "TTSModLVL 18" 19 "TTSModLVL 19" 20 "TTSModLVL 20" 21 "TTSModLVL 21" 22 "TTSModLVL 22" 23 "TTSModLVL 23" 24 "TTSModLVL 24" 25 "TTSModLVL 25" 26 "TTSModLVL 26" 27 "TTSModLVL 27" 28 "TTSModLVL 28" 29 "TTSModLVL 29" 30 "TTSModLVL 30" 31 "TTSModLVL 31" 2 "TTSModLVL 2" 32 "TTSModLVL 32" 33 "TTSModLVL 33" 34 "TTSModLVL 34" 35 "TTSModLVL 35" 36 "TTSModLVL 36" 37 "TTSModLVL 37" 38 "TTSModLVL 38" 39 "TTSModLVL 39" 40 "TTSModLVL 40" 41 "TTSModLVL 41" 42 "TTSModLVL 42" 43 "TTSModLVL 43" 44 "TTSModLVL 44" 45 "TTSModLVL 45" 46 "TTSModLVL 46" 47 "TTSModLVL 47" 3 "TTSModLVL 3" 48 "TTSModLVL 48" 49 "TTSModLVL 49" 50 "TTSModLVL 50" 51 "TTSModLVL 51" 52 "TTSModLVL 52" 53 "TTSModLVL 53" 54 "TTSModLVL 54" 55 "TTSModLVL 55" 56 "TTSModLVL 56" 57 "TTSModLVL 57" 58 "TTSModLVL 58" 59 "TTSModLVL 59" 60 "TTSModLVL 60" 61 "TTSModLVL 61" 62 "TTSModLVL 62" 63 "Invalid" 4 "TTSModLVL 4" 5 "TTSModLVL 5" 6 "TTSModLVL 6" 7 "TTSModLVL 7" 8 "TTSModLVL 8" 9 "TTSModLVL 9" 10 "TTSModLVL 10" 11 "TTSModLVL 11" 12 "TTSModLVL 12" 13 "TTSModLVL 13" 14 "TTSModLVL 14" 15 "TTSModLVL 15" ;
VAL_ 95 CF_AVN_WiperAutoModeSet 0 "Default" 1 "Auto Wash Mode Off" 2 "Auto Wash Mode On" 3 "RESERVED" 4 "RESERVED" 5 "RESERVED" 6 "RESERVED" 7 "Invalid" ;
VAL_ 95 CF_AVN_AFCUAutoWashModeSet 0 "Default" 1 "AFCU Auto Wash Mode Off" 2 "AFCU Auto Wash Mode On" 3 "RESERVED" 4 "RESERVED" 5 "RESERVED" 6 "RESERVED" 7 "Invalid" ;
VAL_ 95 CF_AVN_PSDAutoWashModeSet 0 "Default" 1 "PSD Auto Wash Mode Off" 2 "PSD Auto Wash Mode On" 3 "RESERVED" 4 "RESERVED" 5 "RESERVED" 6 "RESERVED" 7 "Invalid" ;
VAL_ 95 CF_AVN_PTGAutoWashModeSet 0 "Default" 1 "PTG Auto Wash Mode Off" 2 "PTG AUto Wash Mode On" 3 "RESERVED" 4 "RESERVED" 5 "RESERVED" 6 "RESERVED" 7 "Invalid" ;
VAL_ 95 CF_AVN_CDMAutoWashModeSet 0 "Default" 1 "CDM Auto Wash Mode Off" 2 "CDM Auto Wash Mode On" 3 "RESERVED" 4 "RESERVED" 5 "RESERVED" 6 "RESERVED" 7 "Invalid" ;
VAL_ 1043 ICU_Crc4Val 0 "0x0x0~0xFF:CRCValue" 255 "0x0x0~0xFF:CRCValue" ;
VAL_ 1043 Lamp_TrnSigLmpRtActiveSt 0 "Off (Inactive)" 1 "On (Active)" 2 "RESERVED" 3 "Invalid" ;
VAL_ 1043 ICU_AlvCnt4Val 0 "AlvCntValue" 1 "AlvCntValue" 2 "AlvCntValue" 3 "AlvCntValue" 4 "AlvCntValue" 5 "AlvCntValue" 6 "AlvCntValue" 7 "AlvCntValue" 8 "AlvCntValue" 9 "AlvCntValue" 10 "AlvCntValue" 11 "AlvCntValue" 12 "AlvCntValue" 13 "AlvCntValue" 14 "AlvCntValue" 15 "AlvCntValue" ;
VAL_ 1043 ExtLamp_HzrdSwSta 0 "Off" 1 "On" 2 "Not Used" 3 "Error Indicator" ;
VAL_ 1043 IntLamp_InlTailLmpSta 0 "Off" 1 "On" 2 "Not Used" 3 "Error Indicator" ;
VAL_ 1043 Lamp_LedHdLmpSta 0 "LED Headlamp is in nornal condition" 1 "RESERVED" 2 "LED Fail" 3 "RESERVED" ;
VAL_ 1043 TrnLmpSeqEnblCmd 0 "Off" 1 "On" 2 "Reserved" 3 "Reserved" ;
VAL_ 1043 Lamp_TrnSigLmpLftOnReq 0 "Inactive" 1 "Active Off(Flasher Off)" 2 "Active On(Flasher On)" 3 "RESERVED" ;
VAL_ 1043 Lamp_TrnSigLmpRtOnReq 0 "Inactive" 1 "Active Off(Flasher Off)" 2 "Active On(Flasher On)" 3 "RESERVED" ;
VAL_ 1043 ICU_HDPSpprtRdy 0 "Normal" 1 "ADAS Message Not Recognized" 2 "RESERVED" 3 "RESERVED" ;
VAL_ 1043 Lamp_TrnSigLmpLftActiveSt 0 "Off (Inactive)" 1 "On (Active)" 2 "RESERVED" 3 "Invalid" ;
VAL_ 1044 ICU_Crc5Val 0 "0x0x0~0xFF:CRCValue" 255 "0x0x0~0xFF:CRCValue" ;
VAL_ 1044 ICU_AlvCnt5Val 0 "AlvCntValue" 1 "AlvCntValue" 2 "AlvCntValue" 3 "AlvCntValue" 4 "AlvCntValue" 5 "AlvCntValue" 6 "AlvCntValue" 7 "AlvCntValue" 8 "AlvCntValue" 9 "AlvCntValue" 10 "AlvCntValue" 11 "AlvCntValue" 12 "AlvCntValue" 13 "AlvCntValue" 14 "AlvCntValue" 15 "AlvCntValue" ;
VAL_ 1044 Trunk_TrnkInReleaseSwSta 0 "Off" 1 "On" 2 "Stuck" 3 "Error Indicator" ;
VAL_ 1044 Trunk_TrnkTlgtOutReleaseSwSta 0 "Off" 1 "On" 2 "Stuck" 3 "Error Indicator" ;
VAL_ 1044 Trunk_TrnkTlgtSwSta 0 "Close(Full Lock)" 1 "Open(Not Full Lock)" 2 "Not Used" 3 "Error Indicator" ;
VAL_ 1044 Trunk_GlvBxTrnkLkSwSta 0 "Off" 1 "On" 2 "Not Used" 3 "Error Indicator" ;
VAL_ 1044 Trunk_TlgtFullOpnSwSta 0 "Close(Not Full Open)" 1 "Open(Full Open)" 2 "Not Used" 3 "Error Indicator" ;
VAL_ 1044 Trunk_TrnkTlgtReleaseRlySta 0 "OFF" 1 "ON" 2 "Not Used" 3 "Error Indicator" ;
VAL_ 1044 USM_OneTouchTrnSigFuncSta 0 "Default" 1 "One Touch Turn Off" 2 "3 Flashing" 3 "5 Flashing" 4 "7 Flashing" 5 "Invalid" 6 "RESERVED" 7 "RESERVED" ;
VAL_ 1044 DoorLock_DrvDrUnLkSta 0 "Lock" 1 "Unlock" 2 "Not Used" 3 "Error Indicator" ;
VAL_ 1044 DoorLock_LkOutSta 0 "Off" 1 "On" 2 "Not Used" 3 "Error Indicator" ;
VAL_ 1044 C_CrashUnlockState 0 "Off" 1 "Unlock(Crash)" 2 "RESERVED" 3 "RESERVED" ;
VAL_ 1044 C_AutoLeverManualSW 0 "Not Manual" 1 "Manual" 2 "Manual +" 3 "Manual -" ;
